VERSION ""

NS_ :

BS_:

BU_: CH DIPF DIPR ETH FC HVI HVS PARTY SDCV VEH VIRT

BO_ 1297 RCM_alertLog: 8 CH
 SG_ RCM_a001_eventIDFsignal m1 : 25|1@1+ (1,0) [0|1] ""  gtw
 SG_ RCM_a100_eventIDFsignal m100 : 25|1@1+ (1,0) [0|1] ""  gtw
 SG_ RCM_a023_eventIDFsignal m23 : 25|1@1+ (1,0) [0|1] ""  gtw
 SG_ RCM_a090_eventIDFsignal m90 : 25|1@1+ (1,0) [0|1] ""  gtw
 SG_ RCM_a089_eventIDFsignal m89 : 25|1@1+ (1,0) [0|1] ""  gtw
 SG_ RCM_a068_eventIDFsignal m68 : 25|1@1+ (1,0) [0|1] ""  gtw
 SG_ RCM_a071_eventIDFsignal m71 : 25|1@1+ (1,0) [0|1] ""  gtw
 SG_ RCM_a086_eventIDFsignal m86 : 25|1@1+ (1,0) [0|1] ""  gtw
 SG_ RCM_a053_eventIDFsignal m53 : 25|1@1+ (1,0) [0|1] ""  gtw
 SG_ RCM_a116_eventIDFsignal m116 : 25|1@1+ (1,0) [0|1] ""  gtw
 SG_ RCM_a017_eventIDFsignal m17 : 25|1@1+ (1,0) [0|1] ""  gtw
 SG_ RCM_a035_eventIDFsignal m35 : 25|1@1+ (1,0) [0|1] ""  gtw
 SG_ RCM_a056_eventIDFsignal m56 : 25|1@1+ (1,0) [0|1] ""  gtw
 SG_ RCM_a113_eventIDFsignal m113 : 25|1@1+ (1,0) [0|1] ""  gtw
 SG_ RCM_a012_eventIDFsignal m12 : 25|1@1+ (1,0) [0|1] ""  gtw
 SG_ RCM_a074_eventIDFsignal m74 : 25|1@1+ (1,0) [0|1] ""  gtw
 SG_ RCM_a029_eventIDFsignal m29 : 25|1@1+ (1,0) [0|1] ""  gtw
 SG_ RCM_a083_eventIDFsignal m83 : 25|1@1+ (1,0) [0|1] ""  gtw
 SG_ RCM_a030_eventIDFsignal m30 : 25|1@1+ (1,0) [0|1] ""  gtw
 SG_ RCM_a033_eventIDFsignal m33 : 25|1@1+ (1,0) [0|1] ""  gtw
 SG_ RCM_a011_eventIDFsignal m11 : 25|1@1+ (1,0) [0|1] ""  gtw
 SG_ RCM_a077_eventIDFsignal m77 : 25|1@1+ (1,0) [0|1] ""  gtw
 SG_ RCM_a008_eventIDFsignal m8 : 25|1@1+ (1,0) [0|1] ""  gtw
 SG_ RCM_a109_eventIDFsignal m109 : 25|1@1+ (1,0) [0|1] ""  gtw
 SG_ RCM_a099_eventIDFsignal m99 : 25|1@1+ (1,0) [0|1] ""  gtw
 SG_ RCM_a055_eventIDFsignal m55 : 25|1@1+ (1,0) [0|1] ""  gtw
 SG_ RCM_a110_eventIDFsignal m110 : 25|1@1+ (1,0) [0|1] ""  gtw
 SG_ RCM_a080_eventIDFsignal m80 : 25|1@1+ (1,0) [0|1] ""  gtw
 SG_ RCM_a094_eventIDFsignal m94 : 25|1@1+ (1,0) [0|1] ""  gtw
 SG_ RCM_a005_eventIDFsignal m5 : 25|1@1+ (1,0) [0|1] ""  gtw
 SG_ RCM_a027_eventIDFsignal m27 : 25|1@1+ (1,0) [0|1] ""  gtw
 SG_ RCM_a104_eventIDFsignal m104 : 25|1@1+ (1,0) [0|1] ""  gtw
 SG_ RCM_a058_eventIDFsignal m58 : 25|1@1+ (1,0) [0|1] ""  gtw
 SG_ RCM_a041_eventIDFsignal m41 : 25|1@1+ (1,0) [0|1] ""  gtw
 SG_ RCM_a063_eventIDFsignal m63 : 25|1@1+ (1,0) [0|1] ""  gtw
 SG_ RCM_a093_eventIDFsignal m93 : 25|1@1+ (1,0) [0|1] ""  gtw
 SG_ RCM_a020_eventIDFsignal m20 : 25|1@1+ (1,0) [0|1] ""  gtw
 SG_ RCM_a103_eventIDFsignal m103 : 25|1@1+ (1,0) [0|1] ""  gtw
 SG_ RCM_a002_eventIDFsignal m2 : 25|1@1+ (1,0) [0|1] ""  gtw
 SG_ RCM_a039_eventIDFsignal m39 : 25|1@1+ (1,0) [0|1] ""  gtw
 SG_ RCM_a064_eventIDFsignal m64 : 25|1@1+ (1,0) [0|1] ""  gtw
 SG_ RCM_a046_eventIDFsignal m46 : 25|1@1+ (1,0) [0|1] ""  gtw
 SG_ RCM_a070_eventIDFsignal m70 : 25|1@1+ (1,0) [0|1] ""  gtw
 SG_ RCM_a034_eventIDFsignal m34 : 25|1@1+ (1,0) [0|1] ""  gtw
 SG_ RCM_a052_eventIDFsignal m52 : 25|1@1+ (1,0) [0|1] ""  gtw
 SG_ RCM_a117_eventIDFsignal m117 : 25|1@1+ (1,0) [0|1] ""  gtw
 SG_ RCM_a087_eventIDFsignal m87 : 25|1@1+ (1,0) [0|1] ""  gtw
 SG_ RCM_a069_eventIDFsignal m69 : 25|1@1+ (1,0) [0|1] ""  gtw
 SG_ RCM_a016_eventIDFsignal m16 : 25|1@1+ (1,0) [0|1] ""  gtw
 SG_ RCM_a051_eventIDFsignal m51 : 25|1@1+ (1,0) [0|1] ""  gtw
 SG_ RCM_a114_eventIDFsignal m114 : 25|1@1+ (1,0) [0|1] ""  gtw
 SG_ RCM_a015_eventIDFsignal m15 : 25|1@1+ (1,0) [0|1] ""  gtw
 SG_ RCM_a073_eventIDFsignal m73 : 25|1@1+ (1,0) [0|1] ""  gtw
 SG_ RCM_a037_eventIDFsignal m37 : 25|1@1+ (1,0) [0|1] ""  gtw
 SG_ RCM_a084_eventIDFsignal m84 : 25|1@1+ (1,0) [0|1] ""  gtw
 SG_ RCM_a048_eventIDFsignal m48 : 25|1@1+ (1,0) [0|1] ""  gtw
 SG_ RCM_a098_eventIDFsignal m98 : 25|1@1+ (1,0) [0|1] ""  gtw
 SG_ RCM_a081_eventIDFsignal m81 : 25|1@1+ (1,0) [0|1] ""  gtw
 SG_ RCM_a108_eventIDFsignal m108 : 25|1@1+ (1,0) [0|1] ""  gtw
 SG_ RCM_a054_eventIDFsignal m54 : 25|1@1+ (1,0) [0|1] ""  gtw
 SG_ RCM_a111_eventIDFsignal m111 : 25|1@1+ (1,0) [0|1] ""  gtw
 SG_ RCM_a032_eventIDFsignal m32 : 25|1@1+ (1,0) [0|1] ""  gtw
 SG_ RCM_a009_eventIDFsignal m9 : 25|1@1+ (1,0) [0|1] ""  gtw
 SG_ RCM_a076_eventIDFsignal m76 : 25|1@1+ (1,0) [0|1] ""  gtw
 SG_ RCM_a010_eventIDFsignal m10 : 25|1@1+ (1,0) [0|1] ""  gtw
 SG_ RCM_a042_eventIDFsignal m42 : 25|1@1+ (1,0) [0|1] ""  gtw
 SG_ RCM_a079_eventIDFsignal m79 : 25|1@1+ (1,0) [0|1] ""  gtw
 SG_ RCM_a006_eventIDFsignal m6 : 25|1@1+ (1,0) [0|1] ""  gtw
 SG_ RCM_a097_eventIDFsignal m97 : 25|1@1+ (1,0) [0|1] ""  gtw
 SG_ RCM_a060_eventIDFsignal m60 : 25|1@1+ (1,0) [0|1] ""  gtw
 SG_ RCM_a107_eventIDFsignal m107 : 25|1@1+ (1,0) [0|1] ""  gtw
 SG_ RCM_a024_eventIDFsignal m24 : 25|1@1+ (1,0) [0|1] ""  gtw
 SG_ RCM_a047_eventIDFsignal m47 : 25|1@1+ (1,0) [0|1] ""  gtw
 SG_ RCM_a092_eventIDFsignal m92 : 25|1@1+ (1,0) [0|1] ""  gtw
 SG_ RCM_a065_eventIDFsignal m65 : 25|1@1+ (1,0) [0|1] ""  gtw
 SG_ RCM_a021_eventIDFsignal m21 : 25|1@1+ (1,0) [0|1] ""  gtw
 SG_ RCM_a102_eventIDFsignal m102 : 25|1@1+ (1,0) [0|1] ""  gtw
 SG_ RCM_a003_eventIDFsignal m3 : 25|1@1+ (1,0) [0|1] ""  gtw
 SG_ RCM_a038_eventIDFsignal m38 : 25|1@1+ (1,0) [0|1] ""  gtw
 SG_ RCM_a022_eventIDFsignal m22 : 25|1@1+ (1,0) [0|1] ""  gtw
 SG_ RCM_a101_eventIDFsignal m101 : 25|1@1+ (1,0) [0|1] ""  gtw
 SG_ RCM_a118_eventIDFsignal m118 : 25|1@1+ (1,0) [0|1] ""  gtw
 SG_ RCM_a044_eventIDFsignal m44 : 25|1@1+ (1,0) [0|1] ""  gtw
 SG_ RCM_a066_eventIDFsignal m66 : 25|1@1+ (1,0) [0|1] ""  gtw
 SG_ RCM_a000_eventIDFsignal m0 : 25|1@1+ (1,0) [0|1] ""  gtw
 SG_ RCM_a091_eventIDFsignal m91 : 25|1@1+ (1,0) [0|1] ""  gtw
 SG_ RCM_a088_eventIDFsignal m88 : 25|1@1+ (1,0) [0|1] ""  gtw
 SG_ RCM_a019_eventIDFsignal m19 : 25|1@1+ (1,0) [0|1] ""  gtw
 SG_ RCM_a054_presPedProRCrossCoup m54 : 24|1@1+ (1,0) [0|1] ""  gtw
 SG_ RCM_a051_presFrntLDoorCrossCoup m51 : 24|1@1+ (1,0) [0|1] ""  gtw
 SG_ RCM_a052_presFrntRDoorCrossCoup m52 : 24|1@1+ (1,0) [0|1] ""  gtw
 SG_ RCM_a053_presPedProLCrossCoup m53 : 24|1@1+ (1,0) [0|1] ""  gtw
 SG_ RCM_a000_crashDetectedHVpyro m0 : 24|1@1+ (1,0) [0|1] ""  gtw
 SG_ RCM_a045_upFrontSensorRDefect m45 : 23|1@1+ (1,0) [0|1] ""  gtw
 SG_ RCM_a052_presFrntRDoorSht2Bat m52 : 23|1@1+ (1,0) [0|1] ""  gtw
 SG_ RCM_a051_presFrntLDoorSht2Bat m51 : 23|1@1+ (1,0) [0|1] ""  gtw
 SG_ RCM_a047_sideAccelBPilRDefect m47 : 23|1@1+ (1,0) [0|1] ""  gtw
 SG_ RCM_a046_sideAccelBPilLDefect m46 : 23|1@1+ (1,0) [0|1] ""  gtw
 SG_ RCM_a050_upFrontSensorCDefect m50 : 23|1@1+ (1,0) [0|1] ""  gtw
 SG_ RCM_a000_crashDetectedStage2 m0 : 23|1@1+ (1,0) [0|1] ""  gtw
 SG_ RCM_a044_upFrontSensorLDefect m44 : 23|1@1+ (1,0) [0|1] ""  gtw
 SG_ RCM_a053_presPedProLSht2Bat m53 : 23|1@1+ (1,0) [0|1] ""  gtw
 SG_ RCM_a048_sideAccelCPilLDefect m48 : 23|1@1+ (1,0) [0|1] ""  gtw
 SG_ RCM_a049_sideAccelCPilRDefect m49 : 23|1@1+ (1,0) [0|1] ""  gtw
 SG_ RCM_a004_algoPASIDMismatch m4 : 23|1@1+ (1,0) [0|1] ""  gtw
 SG_ RCM_a054_presPedProRSht2Bat m54 : 23|1@1+ (1,0) [0|1] ""  gtw
 SG_ RCM_a048_sideAccelCPilLplaus m48 : 22|1@1+ (1,0) [0|1] ""  gtw
 SG_ RCM_a044_upFrontSensorLplaus m44 : 22|1@1+ (1,0) [0|1] ""  gtw
 SG_ RCM_a004_paramLayoutIDInv m4 : 22|1@1+ (1,0) [0|1] ""  gtw
 SG_ RCM_a050_upFrontSensorCplaus m50 : 22|1@1+ (1,0) [0|1] ""  gtw
 SG_ RCM_a053_presPedProLSht2Gnd m53 : 22|1@1+ (1,0) [0|1] ""  gtw
 SG_ RCM_a046_sideAccelBPilLplaus m46 : 22|1@1+ (1,0) [0|1] ""  gtw
 SG_ RCM_a052_presFrntRDoorSht2Gnd m52 : 22|1@1+ (1,0) [0|1] ""  gtw
 SG_ RCM_a051_presFrntLDoorSht2Gnd m51 : 22|1@1+ (1,0) [0|1] ""  gtw
 SG_ RCM_a054_presPedProRSht2Gnd m54 : 22|1@1+ (1,0) [0|1] ""  gtw
 SG_ RCM_a047_sideAccelBPilRplaus m47 : 22|1@1+ (1,0) [0|1] ""  gtw
 SG_ RCM_a000_crashDetectedStage1 m0 : 22|1@1+ (1,0) [0|1] ""  gtw
 SG_ RCM_a045_upFrontSensorRplaus m45 : 22|1@1+ (1,0) [0|1] ""  gtw
 SG_ RCM_a049_sideAccelCPilRplaus m49 : 22|1@1+ (1,0) [0|1] ""  gtw
 SG_ RCM_a017_passABStg2Config m17 : 21|1@1+ (1,0) [0|1] ""  gtw
 SG_ RCM_a052_presFrntRDoorDefect m52 : 21|1@1+ (1,0) [0|1] ""  gtw
 SG_ RCM_a103_imuPtchR8OffCompNegSLDC m103 : 21|1@1+ (1,0) [0|1] ""  gtw
 SG_ RCM_a035_preten2ndRowRCgf m35 : 21|1@1+ (1,0) [0|1] ""  gtw
 SG_ RCM_a041_hoodActuatorLConfig m41 : 21|1@1+ (1,0) [0|1] ""  gtw
 SG_ RCM_a105_imuLongAOffCompNegSLDC m105 : 21|1@1+ (1,0) [0|1] ""  gtw
 SG_ RCM_a031_frntCentrABConfig m31 : 21|1@1+ (1,0) [0|1] ""  gtw
 SG_ RCM_a040_hoodActuatorRConfig m40 : 21|1@1+ (1,0) [0|1] ""  gtw
 SG_ RCM_a014_driverABStg1Config m14 : 21|1@1+ (1,0) [0|1] ""  gtw
 SG_ RCM_a028_sideAB1stRowRConfig m28 : 21|1@1+ (1,0) [0|1] ""  gtw
 SG_ RCM_a016_passABStg1Config m16 : 21|1@1+ (1,0) [0|1] ""  gtw
 SG_ RCM_a054_presPedProRDefect m54 : 21|1@1+ (1,0) [0|1] ""  gtw
 SG_ RCM_a048_sideAccelCPilLOption m48 : 21|1@1+ (1,0) [0|1] ""  gtw
 SG_ RCM_a000_crashDetectedPreten m0 : 21|1@1+ (1,0) [0|1] ""  gtw
 SG_ RCM_a033_curABRightConfig m33 : 21|1@1+ (1,0) [0|1] ""  gtw
 SG_ RCM_a106_imuLatAcOffCompNegSLDC m106 : 21|1@1+ (1,0) [0|1] ""  gtw
 SG_ RCM_a027_sideAB1stRowLConfig m27 : 21|1@1+ (1,0) [0|1] ""  gtw
 SG_ RCM_a094_bucklSwVCRearCnterFault m94 : 21|1@1+ (1,0) [0|1] ""  gtw
 SG_ RCM_a063_sbsw2ndRowRConfig m63 : 21|1@1+ (1,0) [0|1] ""  gtw
 SG_ RCM_a019_pretenShldLeftConfig m19 : 21|1@1+ (1,0) [0|1] ""  gtw
 SG_ RCM_a038_unused6 m38 : 21|1@1+ (1,0) [0|1] ""  gtw
 SG_ RCM_a104_imuRollR8OffCompNegSLDC m104 : 21|1@1+ (1,0) [0|1] ""  gtw
 SG_ RCM_a026_kneeABPassConfig m26 : 21|1@1+ (1,0) [0|1] ""  gtw
 SG_ RCM_a062_alrConfig m62 : 21|1@1+ (1,0) [0|1] ""  gtw
 SG_ RCM_a049_sideAccelCPilROption m49 : 21|1@1+ (1,0) [0|1] ""  gtw
 SG_ RCM_a051_presFrntLDoorDefect m51 : 21|1@1+ (1,0) [0|1] ""  gtw
 SG_ RCM_a025_kneeABDrvrConfig m25 : 21|1@1+ (1,0) [0|1] ""  gtw
 SG_ RCM_a030_farsideABConfig m30 : 21|1@1+ (1,0) [0|1] ""  gtw
 SG_ RCM_a029_driverABAVConfig m29 : 21|1@1+ (1,0) [0|1] ""  gtw
 SG_ RCM_a061_seaTrkPosRightConfig m61 : 21|1@1+ (1,0) [0|1] ""  gtw
 SG_ RCM_a034_preten2ndRowLCgf m34 : 21|1@1+ (1,0) [0|1] ""  gtw
 SG_ RCM_a020_pretenShldRightConfig m20 : 21|1@1+ (1,0) [0|1] ""  gtw
 SG_ RCM_a036_curAB2ndRowLConfig m36 : 21|1@1+ (1,0) [0|1] ""  gtw
 SG_ RCM_a023_loadLimLeftConfig m23 : 21|1@1+ (1,0) [0|1] ""  gtw
 SG_ RCM_a058_bucklHallLeftConfig m58 : 21|1@1+ (1,0) [0|1] ""  gtw
 SG_ RCM_a047_sideAccelBPilROption m47 : 21|1@1+ (1,0) [0|1] ""  gtw
 SG_ RCM_a004_swVersionMismatch m4 : 21|1@1+ (1,0) [0|1] ""  gtw
 SG_ RCM_a001_nearDeployPretensioner m1 : 21|1@1+ (1,0) [0|1] ""  gtw
 SG_ RCM_a102_imuYawR8OffCompNegSLDC m102 : 21|1@1+ (1,0) [0|1] ""  gtw
 SG_ RCM_a039_unused12 m39 : 21|1@1+ (1,0) [0|1] ""  gtw
 SG_ RCM_a044_upFrontSensorLOption m44 : 21|1@1+ (1,0) [0|1] ""  gtw
 SG_ RCM_a053_presPedProLDefect m53 : 21|1@1+ (1,0) [0|1] ""  gtw
 SG_ RCM_a032_curABLeftConfig m32 : 21|1@1+ (1,0) [0|1] ""  gtw
 SG_ RCM_a022_pretenLapRightConfig m22 : 21|1@1+ (1,0) [0|1] ""  gtw
 SG_ RCM_a021_pretenLapLeftConfig m21 : 21|1@1+ (1,0) [0|1] ""  gtw
 SG_ RCM_a050_upFrontSensorCOption m50 : 21|1@1+ (1,0) [0|1] ""  gtw
 SG_ RCM_a018_passActiveVentConfig m18 : 21|1@1+ (1,0) [0|1] ""  gtw
 SG_ RCM_a024_loadLimRightConfig m24 : 21|1@1+ (1,0) [0|1] ""  gtw
 SG_ RCM_a045_upFrontSensorROption m45 : 21|1@1+ (1,0) [0|1] ""  gtw
 SG_ RCM_a037_curAB2ndRowRConfig m37 : 21|1@1+ (1,0) [0|1] ""  gtw
 SG_ RCM_a060_seaTrkPosLeftConfig m60 : 21|1@1+ (1,0) [0|1] ""  gtw
 SG_ RCM_a015_driverABStg2Config m15 : 21|1@1+ (1,0) [0|1] ""  gtw
 SG_ RCM_a107_imuVertAOffCompNegSLDC m107 : 21|1@1+ (1,0) [0|1] ""  gtw
 SG_ RCM_a046_sideAccelBPilLOption m46 : 21|1@1+ (1,0) [0|1] ""  gtw
 SG_ RCM_a059_bucklSwRightConfig m59 : 21|1@1+ (1,0) [0|1] ""  gtw
 SG_ RCM_a105_imuLongAOffCompPosSLDC m105 : 20|1@1+ (1,0) [0|1] ""  gtw
 SG_ RCM_a054_presPedProRAbsPre m54 : 20|1@1+ (1,0) [0|1] ""  gtw
 SG_ RCM_a060_seaTrkPosLeftCrossCoup m60 : 20|1@1+ (1,0) [0|1] ""  gtw
 SG_ RCM_a037_curAB2ndRowRCrossCoup m37 : 20|1@1+ (1,0) [0|1] ""  gtw
 SG_ RCM_a015_driverABStg2CrossCoup m15 : 20|1@1+ (1,0) [0|1] ""  gtw
 SG_ RCM_a103_imuPtchR8OffCompPosSLDC m103 : 20|1@1+ (1,0) [0|1] ""  gtw
 SG_ RCM_a036_curAB2ndRowLCrossCoup m36 : 20|1@1+ (1,0) [0|1] ""  gtw
 SG_ RCM_a058_bucklHallLeftCrossCoup m58 : 20|1@1+ (1,0) [0|1] ""  gtw
 SG_ RCM_a023_loadLimLeftCrossCoup m23 : 20|1@1+ (1,0) [0|1] ""  gtw
 SG_ RCM_a040_hoodActuatorRCrossCoup m40 : 20|1@1+ (1,0) [0|1] ""  gtw
 SG_ RCM_a031_frntCentrABCrossCoup m31 : 20|1@1+ (1,0) [0|1] ""  gtw
 SG_ RCM_a052_presFrntRDoorAbsPre m52 : 20|1@1+ (1,0) [0|1] ""  gtw
 SG_ RCM_a014_driverABStg1CrossCoup m14 : 20|1@1+ (1,0) [0|1] ""  gtw
 SG_ RCM_a039_unused11 m39 : 20|1@1+ (1,0) [0|1] ""  gtw
 SG_ RCM_a046_sideAccelBPilLInitTyp m46 : 20|1@1+ (1,0) [0|1] ""  gtw
 SG_ RCM_a093_bucklSwVCRearLeftFault m93 : 20|1@1+ (1,0) [0|1] ""  gtw
 SG_ RCM_a094_bucklSwVCRearRghtFault m94 : 20|1@1+ (1,0) [0|1] ""  gtw
 SG_ RCM_a106_imuLatAcOffCompPosSLDC m106 : 20|1@1+ (1,0) [0|1] ""  gtw
 SG_ RCM_a063_sbsw2ndRowRCrossCoup m63 : 20|1@1+ (1,0) [0|1] ""  gtw
 SG_ RCM_a022_pretenLapRightCrossCoup m22 : 20|1@1+ (1,0) [0|1] ""  gtw
 SG_ RCM_a021_pretenLapLeftCrossCoup m21 : 20|1@1+ (1,0) [0|1] ""  gtw
 SG_ RCM_a032_curABLeftCrossCoup m32 : 20|1@1+ (1,0) [0|1] ""  gtw
 SG_ RCM_a048_sideAccelCPilLInitTyp m48 : 20|1@1+ (1,0) [0|1] ""  gtw
 SG_ RCM_a018_passActiveVentCrossCoup m18 : 20|1@1+ (1,0) [0|1] ""  gtw
 SG_ RCM_a044_upFrontSensorLInitTyp m44 : 20|1@1+ (1,0) [0|1] ""  gtw
 SG_ RCM_a017_passABStg2CrossCoup m17 : 20|1@1+ (1,0) [0|1] ""  gtw
 SG_ RCM_a104_imuRollR8OffCompPosSLDC m104 : 20|1@1+ (1,0) [0|1] ""  gtw
 SG_ RCM_a041_hoodActuatorLCrossCoup m41 : 20|1@1+ (1,0) [0|1] ""  gtw
 SG_ RCM_a062_alrCrossCoup m62 : 20|1@1+ (1,0) [0|1] ""  gtw
 SG_ RCM_a026_kneeABPassCrossCoup m26 : 20|1@1+ (1,0) [0|1] ""  gtw
 SG_ RCM_a020_pretenShldRightCrossC m20 : 20|1@1+ (1,0) [0|1] ""  gtw
 SG_ RCM_a112_imuYawR8ChnlMonitPerm m112 : 20|1@1+ (1,0) [0|1] ""  gtw
 SG_ RCM_a025_kneeABDrvrCrossCoup m25 : 20|1@1+ (1,0) [0|1] ""  gtw
 SG_ RCM_a051_presFrntLDoorAbsPre m51 : 20|1@1+ (1,0) [0|1] ""  gtw
 SG_ RCM_a028_sideAB1stRowRCrossCoup m28 : 20|1@1+ (1,0) [0|1] ""  gtw
 SG_ RCM_a050_upFrontSensorCInitTyp m50 : 20|1@1+ (1,0) [0|1] ""  gtw
 SG_ RCM_a016_passABStg1CrossCoup m16 : 20|1@1+ (1,0) [0|1] ""  gtw
 SG_ RCM_a034_preten2ndRowLCrossCoup m34 : 20|1@1+ (1,0) [0|1] ""  gtw
 SG_ RCM_a061_seaTrkPosRightCrossCoup m61 : 20|1@1+ (1,0) [0|1] ""  gtw
 SG_ RCM_a029_driverABAVCrossCoup m29 : 20|1@1+ (1,0) [0|1] ""  gtw
 SG_ RCM_a045_upFrontSensorRInitTyp m45 : 20|1@1+ (1,0) [0|1] ""  gtw
 SG_ RCM_a049_sideAccelCPilRInitTyp m49 : 20|1@1+ (1,0) [0|1] ""  gtw
 SG_ RCM_a102_imuYawR8OffCompPosSLDC m102 : 20|1@1+ (1,0) [0|1] ""  gtw
 SG_ RCM_a019_pretenShldLeftCrossC m19 : 20|1@1+ (1,0) [0|1] ""  gtw
 SG_ RCM_a053_presPedProLAbsPre m53 : 20|1@1+ (1,0) [0|1] ""  gtw
 SG_ RCM_a000_crashDetectedRoll m0 : 20|1@1+ (1,0) [0|1] ""  gtw
 SG_ RCM_a033_curABRightCrossCoup m33 : 20|1@1+ (1,0) [0|1] ""  gtw
 SG_ RCM_a004_internalFaultDetected m4 : 20|1@1+ (1,0) [0|1] ""  gtw
 SG_ RCM_a001_nearDeployRoll m1 : 20|1@1+ (1,0) [0|1] ""  gtw
 SG_ RCM_a024_loadLimRightCrossCoup m24 : 20|1@1+ (1,0) [0|1] ""  gtw
 SG_ RCM_a047_sideAccelBPilRInitTyp m47 : 20|1@1+ (1,0) [0|1] ""  gtw
 SG_ RCM_a038_unused5 m38 : 20|1@1+ (1,0) [0|1] ""  gtw
 SG_ RCM_a027_sideAB1stRowLCrossCoup m27 : 20|1@1+ (1,0) [0|1] ""  gtw
 SG_ RCM_a035_preten2ndRowRCrossCoup m35 : 20|1@1+ (1,0) [0|1] ""  gtw
 SG_ RCM_a030_farsideABCrossCoup m30 : 20|1@1+ (1,0) [0|1] ""  gtw
 SG_ RCM_a107_imuVertAOffCompPosSLDC m107 : 20|1@1+ (1,0) [0|1] ""  gtw
 SG_ RCM_a059_bucklHallRightCrossCoup m59 : 20|1@1+ (1,0) [0|1] ""  gtw
 SG_ RCM_a017_passABStg2Short m17 : 19|1@1+ (1,0) [0|1] ""  gtw
 SG_ RCM_a065_swDrvrOrientConfig m65 : 19|1@1+ (1,0) [0|1] ""  gtw
 SG_ RCM_a104_imuRollR8OffCompNegFLDC m104 : 19|1@1+ (1,0) [0|1] ""  gtw
 SG_ RCM_a041_hoodActuatorLShort m41 : 19|1@1+ (1,0) [0|1] ""  gtw
 SG_ RCM_a113_imuPitchR8ChnlMonitPerm m113 : 19|1@1+ (1,0) [0|1] ""  gtw
 SG_ RCM_a020_pretenShldRightShort m20 : 19|1@1+ (1,0) [0|1] ""  gtw
 SG_ RCM_a061_seaTrkPosRightUndefined m61 : 19|1@1+ (1,0) [0|1] ""  gtw
 SG_ RCM_a029_driverABAVShort m29 : 19|1@1+ (1,0) [0|1] ""  gtw
 SG_ RCM_a034_preten2ndRowLShort m34 : 19|1@1+ (1,0) [0|1] ""  gtw
 SG_ RCM_a038_unused4 m38 : 19|1@1+ (1,0) [0|1] ""  gtw
 SG_ RCM_a046_sideAccelBPilLComm m46 : 19|1@1+ (1,0) [0|1] ""  gtw
 SG_ RCM_a016_passABStg1Short m16 : 19|1@1+ (1,0) [0|1] ""  gtw
 SG_ RCM_a028_sideAB1stRowRShort m28 : 19|1@1+ (1,0) [0|1] ""  gtw
 SG_ RCM_a045_upFrontSensorRComm m45 : 19|1@1+ (1,0) [0|1] ""  gtw
 SG_ RCM_a000_crashDetectedRight m0 : 19|1@1+ (1,0) [0|1] ""  gtw
 SG_ RCM_a064_hwcp1Config m64 : 19|1@1+ (1,0) [0|1] ""  gtw
 SG_ RCM_a050_upFrontSensorCComm m50 : 19|1@1+ (1,0) [0|1] ""  gtw
 SG_ RCM_a093_bucklSwVCFrontLeftFault m93 : 19|1@1+ (1,0) [0|1] ""  gtw
 SG_ RCM_a021_pretenLapLeftShort m21 : 19|1@1+ (1,0) [0|1] ""  gtw
 SG_ RCM_a112_imuYawR8ChnlMonitTmp m112 : 19|1@1+ (1,0) [0|1] ""  gtw
 SG_ RCM_a022_pretenLapRightShort m22 : 19|1@1+ (1,0) [0|1] ""  gtw
 SG_ RCM_a039_unused10 m39 : 19|1@1+ (1,0) [0|1] ""  gtw
 SG_ RCM_a051_presFrntLDoorPlaus m51 : 19|1@1+ (1,0) [0|1] ""  gtw
 SG_ RCM_a032_curABLeftShort m32 : 19|1@1+ (1,0) [0|1] ""  gtw
 SG_ RCM_a018_passActiveVentShort m18 : 19|1@1+ (1,0) [0|1] ""  gtw
 SG_ RCM_a019_pretenShldLeftShort m19 : 19|1@1+ (1,0) [0|1] ""  gtw
 SG_ RCM_a063_sbsw2ndRowRUndefined m63 : 19|1@1+ (1,0) [0|1] ""  gtw
 SG_ RCM_a044_upFrontSensorLComm m44 : 19|1@1+ (1,0) [0|1] ""  gtw
 SG_ RCM_a106_imuLatAcOffCompNegFLDC m106 : 19|1@1+ (1,0) [0|1] ""  gtw
 SG_ RCM_a015_driverABStg2Short m15 : 19|1@1+ (1,0) [0|1] ""  gtw
 SG_ RCM_a066_sbsw2ndRowLConfig m66 : 19|1@1+ (1,0) [0|1] ""  gtw
 SG_ RCM_a060_seaTrkPosLeftUndefined m60 : 19|1@1+ (1,0) [0|1] ""  gtw
 SG_ RCM_a047_sideAccelBPilRComm m47 : 19|1@1+ (1,0) [0|1] ""  gtw
 SG_ RCM_a037_curAB2ndRowRShort m37 : 19|1@1+ (1,0) [0|1] ""  gtw
 SG_ RCM_a105_imuLongAOffCompNegFLDC m105 : 19|1@1+ (1,0) [0|1] ""  gtw
 SG_ RCM_a103_imuPtchR8OffCompNegFLDC m103 : 19|1@1+ (1,0) [0|1] ""  gtw
 SG_ RCM_a035_preten2ndRowRShort m35 : 19|1@1+ (1,0) [0|1] ""  gtw
 SG_ RCM_a030_farsideABShort m30 : 19|1@1+ (1,0) [0|1] ""  gtw
 SG_ RCM_a107_imuVertAOffCompNegFLDC m107 : 19|1@1+ (1,0) [0|1] ""  gtw
 SG_ RCM_a004_idleMode m4 : 19|1@1+ (1,0) [0|1] ""  gtw
 SG_ RCM_a040_hoodActuatorRShort m40 : 19|1@1+ (1,0) [0|1] ""  gtw
 SG_ RCM_a091_comEPAS3PsysStatusCntr m91 : 19|1@1+ (1,0) [0|1] ""  gtw
 SG_ RCM_a014_driverABStg1Short m14 : 19|1@1+ (1,0) [0|1] ""  gtw
 SG_ RCM_a031_frntCentrABShort m31 : 19|1@1+ (1,0) [0|1] ""  gtw
 SG_ RCM_a023_loadLimLeftShort m23 : 19|1@1+ (1,0) [0|1] ""  gtw
 SG_ RCM_a049_sideAccelCPilRComm m49 : 19|1@1+ (1,0) [0|1] ""  gtw
 SG_ RCM_a036_curAB2ndRowLShort m36 : 19|1@1+ (1,0) [0|1] ""  gtw
 SG_ RCM_a094_bucklSwVCFrontRghtFault m94 : 19|1@1+ (1,0) [0|1] ""  gtw
 SG_ RCM_a033_curABRightShort m33 : 19|1@1+ (1,0) [0|1] ""  gtw
 SG_ RCM_a114_imuRollR8ChnlMonitPerm m114 : 19|1@1+ (1,0) [0|1] ""  gtw
 SG_ RCM_a102_imuYawR8OffCompNegFLDC m102 : 19|1@1+ (1,0) [0|1] ""  gtw
 SG_ RCM_a054_presPedProRPlaus m54 : 19|1@1+ (1,0) [0|1] ""  gtw
 SG_ RCM_a058_bucklHallLeftUndef m58 : 19|1@1+ (1,0) [0|1] ""  gtw
 SG_ RCM_a027_sideAB1stRowLShort m27 : 19|1@1+ (1,0) [0|1] ""  gtw
 SG_ RCM_a052_presFrntRDoorPlaus m52 : 19|1@1+ (1,0) [0|1] ""  gtw
 SG_ RCM_a001_nearDeployRight m1 : 19|1@1+ (1,0) [0|1] ""  gtw
 SG_ RCM_a024_loadLimRightShort m24 : 19|1@1+ (1,0) [0|1] ""  gtw
 SG_ RCM_a059_bucklHallRightUndef m59 : 19|1@1+ (1,0) [0|1] ""  gtw
 SG_ RCM_a053_presPedProLPlaus m53 : 19|1@1+ (1,0) [0|1] ""  gtw
 SG_ RCM_a026_kneeABPassShort m26 : 19|1@1+ (1,0) [0|1] ""  gtw
 SG_ RCM_a048_sideAccelCPilLComm m48 : 19|1@1+ (1,0) [0|1] ""  gtw
 SG_ RCM_a025_kneeABDrvrShort m25 : 19|1@1+ (1,0) [0|1] ""  gtw
 SG_ RCM_a062_alrUndefined m62 : 19|1@1+ (1,0) [0|1] ""  gtw
 SG_ RCM_a089_comChassisCANPH3Cntr m89 : 18|1@1+ (1,0) [0|1] ""  gtw
 SG_ RCM_a096_comESPwheelSpeedsCntr m96 : 18|1@1+ (1,0) [0|1] ""  gtw
 SG_ RCM_a024_loadLimRightOpen m24 : 18|1@1+ (1,0) [0|1] ""  gtw
 SG_ RCM_a104_imuRollR8OffCompPosFLDC m104 : 18|1@1+ (1,0) [0|1] ""  gtw
 SG_ RCM_a076_comEPBLStatusCntr m76 : 18|1@1+ (1,0) [0|1] ""  gtw
 SG_ RCM_a095_comESPstatusCntr m95 : 18|1@1+ (1,0) [0|1] ""  gtw
 SG_ RCM_a033_curABRightOpen m33 : 18|1@1+ (1,0) [0|1] ""  gtw
 SG_ RCM_a072_comUnusedCntr m72 : 18|1@1+ (1,0) [0|1] ""  gtw
 SG_ RCM_a077_comEPBRStatusCntr m77 : 18|1@1+ (1,0) [0|1] ""  gtw
 SG_ RCM_a091_comEPAS3PsysStatusChkSm m91 : 18|1@1+ (1,0) [0|1] ""  gtw
 SG_ RCM_a069_comChassisCANPH7Cntr m69 : 18|1@1+ (1,0) [0|1] ""  gtw
 SG_ RCM_a079_comOCS1DCntr m79 : 18|1@1+ (1,0) [0|1] ""  gtw
 SG_ RCM_a097_comDIspeedCntr m97 : 18|1@1+ (1,0) [0|1] ""  gtw
 SG_ RCM_a042_ens1Config m42 : 18|1@1+ (1,0) [0|1] ""  gtw
 SG_ RCM_a031_frntCentrABOpen m31 : 18|1@1+ (1,0) [0|1] ""  gtw
 SG_ RCM_a040_hoodActuatorROpen m40 : 18|1@1+ (1,0) [0|1] ""  gtw
 SG_ RCM_a014_driverABStg1Open m14 : 18|1@1+ (1,0) [0|1] ""  gtw
 SG_ RCM_a046_sideAccelBPilLCLosCoup m46 : 18|1@1+ (1,0) [0|1] ""  gtw
 SG_ RCM_a036_curAB2ndRowLOpen m36 : 18|1@1+ (1,0) [0|1] ""  gtw
 SG_ RCM_a074_comChassisCANPH5Cntr m74 : 18|1@1+ (1,0) [0|1] ""  gtw
 SG_ RCM_a081_comVCFRONTLVPrwCntr m81 : 18|1@1+ (1,0) [0|1] ""  gtw
 SG_ RCM_a058_bucklHallLeftOpen m58 : 18|1@1+ (1,0) [0|1] ""  gtw
 SG_ RCM_a023_loadLimLeftOpen m23 : 18|1@1+ (1,0) [0|1] ""  gtw
 SG_ RCM_a043_ens2Config m43 : 18|1@1+ (1,0) [0|1] ""  gtw
 SG_ RCM_a100_comDIsystemStatusCntr m100 : 18|1@1+ (1,0) [0|1] ""  gtw
 SG_ RCM_a015_driverABStg2Open m15 : 18|1@1+ (1,0) [0|1] ""  gtw
 SG_ RCM_a037_curAB2ndRowROpen m37 : 18|1@1+ (1,0) [0|1] ""  gtw
 SG_ RCM_a060_seaTrkPosLeftOpen m60 : 18|1@1+ (1,0) [0|1] ""  gtw
 SG_ RCM_a059_bucklHallRightOpen m59 : 18|1@1+ (1,0) [0|1] ""  gtw
 SG_ RCM_a030_farsideABOpen m30 : 18|1@1+ (1,0) [0|1] ""  gtw
 SG_ RCM_a048_sideAccelCPilLCrossCoup m48 : 18|1@1+ (1,0) [0|1] ""  gtw
 SG_ RCM_a106_imuLatAcOffCompPosFLDC m106 : 18|1@1+ (1,0) [0|1] ""  gtw
 SG_ RCM_a093_comVCLEFTStatusCntr m93 : 18|1@1+ (1,0) [0|1] ""  gtw
 SG_ RCM_a035_preten2ndRowROpen m35 : 18|1@1+ (1,0) [0|1] ""  gtw
 SG_ RCM_a075_comChassisCANPH6Cntr m75 : 18|1@1+ (1,0) [0|1] ""  gtw
 SG_ RCM_a065_swDrvrOrientCrossCoup m65 : 18|1@1+ (1,0) [0|1] ""  gtw
 SG_ RCM_a105_imuLongAOffCompPosFLDC m105 : 18|1@1+ (1,0) [0|1] ""  gtw
 SG_ RCM_a103_imuPtchR8OffCompPosFLDC m103 : 18|1@1+ (1,0) [0|1] ""  gtw
 SG_ RCM_a022_pretenLapRightOpen m22 : 18|1@1+ (1,0) [0|1] ""  gtw
 SG_ RCM_a021_pretenLapLeftOpen m21 : 18|1@1+ (1,0) [0|1] ""  gtw
 SG_ RCM_a018_passActiveVentOpen m18 : 18|1@1+ (1,0) [0|1] ""  gtw
 SG_ RCM_a053_presPedProLOption m53 : 18|1@1+ (1,0) [0|1] ""  gtw
 SG_ RCM_a071_comChassisCANPH9Cntr m71 : 18|1@1+ (1,0) [0|1] ""  gtw
 SG_ RCM_a044_upFrontSensorLCrossCoup m44 : 18|1@1+ (1,0) [0|1] ""  gtw
 SG_ RCM_a032_curABLeftOpen m32 : 18|1@1+ (1,0) [0|1] ""  gtw
 SG_ RCM_a063_sbsw2ndRowROpen m63 : 18|1@1+ (1,0) [0|1] ""  gtw
 SG_ RCM_a004_rollAlgoDisabled m4 : 18|1@1+ (1,0) [0|1] ""  gtw
 SG_ RCM_a088_comChassisCANPH2Cntr m88 : 18|1@1+ (1,0) [0|1] ""  gtw
 SG_ RCM_a038_unused3 m38 : 18|1@1+ (1,0) [0|1] ""  gtw
 SG_ RCM_a107_imuVertAOffCompPosFLDC m107 : 18|1@1+ (1,0) [0|1] ""  gtw
 SG_ RCM_a066_sbsw2ndRowLCrossCoup m66 : 18|1@1+ (1,0) [0|1] ""  gtw
 SG_ RCM_a019_pretenShldLeftOpen m19 : 18|1@1+ (1,0) [0|1] ""  gtw
 SG_ RCM_a050_upFrontSensorCCrossCoup m50 : 18|1@1+ (1,0) [0|1] ""  gtw
 SG_ RCM_a078_comOCS1PCntr m78 : 18|1@1+ (1,0) [0|1] ""  gtw
 SG_ RCM_a114_imuRollR8ChnlMonitTmp m114 : 18|1@1+ (1,0) [0|1] ""  gtw
 SG_ RCM_a094_comVCRIGHTStatusCntr m94 : 18|1@1+ (1,0) [0|1] ""  gtw
 SG_ RCM_a073_comChassisCANPH4Cntr m73 : 18|1@1+ (1,0) [0|1] ""  gtw
 SG_ RCM_a000_crashDetectedLeft m0 : 18|1@1+ (1,0) [0|1] ""  gtw
 SG_ RCM_a045_upFrontSensorRCrossCoup m45 : 18|1@1+ (1,0) [0|1] ""  gtw
 SG_ RCM_a061_seaTrkPosRightOpen m61 : 18|1@1+ (1,0) [0|1] ""  gtw
 SG_ RCM_a029_driverABAVOpen m29 : 18|1@1+ (1,0) [0|1] ""  gtw
 SG_ RCM_a034_preten2ndRowLOpen m34 : 18|1@1+ (1,0) [0|1] ""  gtw
 SG_ RCM_a049_sideAccelCPilRCrossCoup m49 : 18|1@1+ (1,0) [0|1] ""  gtw
 SG_ RCM_a020_pretenShldRightOpen m20 : 18|1@1+ (1,0) [0|1] ""  gtw
 SG_ RCM_a054_presPedProROption m54 : 18|1@1+ (1,0) [0|1] ""  gtw
 SG_ RCM_a064_hwcp1CrossCoup m64 : 18|1@1+ (1,0) [0|1] ""  gtw
 SG_ RCM_a016_passABStg1Open m16 : 18|1@1+ (1,0) [0|1] ""  gtw
 SG_ RCM_a007_invalidShtdwnReqSequnce m7 : 18|1@1+ (1,0) [0|1] ""  gtw
 SG_ RCM_a102_imuYawR8OffCompPosFLDC m102 : 18|1@1+ (1,0) [0|1] ""  gtw
 SG_ RCM_a028_sideAB1stRowROpen m28 : 18|1@1+ (1,0) [0|1] ""  gtw
 SG_ RCM_a099_comDItorqueCntr m99 : 18|1@1+ (1,0) [0|1] ""  gtw
 SG_ RCM_a080_comGTWACSCntr m80 : 18|1@1+ (1,0) [0|1] ""  gtw
 SG_ RCM_a101_idfEnviMonitoringEvent m101 : 18|1@1+ (1,0) [0|1] ""  gtw
 SG_ RCM_a062_alrOpen m62 : 18|1@1+ (1,0) [0|1] ""  gtw
 SG_ RCM_a039_unused9 m39 : 18|1@1+ (1,0) [0|1] ""  gtw
 SG_ RCM_a113_imuPitchR8ChnlMonitTmp m113 : 18|1@1+ (1,0) [0|1] ""  gtw
 SG_ RCM_a025_kneeABDrvrOpen m25 : 18|1@1+ (1,0) [0|1] ""  gtw
 SG_ RCM_a051_presFrntLDoorOption m51 : 18|1@1+ (1,0) [0|1] ""  gtw
 SG_ RCM_a026_kneeABPassOpen m26 : 18|1@1+ (1,0) [0|1] ""  gtw
 SG_ RCM_a087_comUnusedCANSilent m87 : 18|1@1+ (1,0) [0|1] ""  gtw
 SG_ RCM_a092_comDASSafetyFrontCntr m92 : 18|1@1+ (1,0) [0|1] ""  gtw
 SG_ RCM_a041_hoodActuatorLOpen m41 : 18|1@1+ (1,0) [0|1] ""  gtw
 SG_ RCM_a047_sideAccelBPilRCrossCoup m47 : 18|1@1+ (1,0) [0|1] ""  gtw
 SG_ RCM_a052_presFrntRDoorOption m52 : 18|1@1+ (1,0) [0|1] ""  gtw
 SG_ RCM_a017_passABStg2Open m17 : 18|1@1+ (1,0) [0|1] ""  gtw
 SG_ RCM_a008_normalShtdwnUnavail m8 : 18|1@1+ (1,0) [0|1] ""  gtw
 SG_ RCM_a070_comChassisCANPH8Cntr m70 : 18|1@1+ (1,0) [0|1] ""  gtw
 SG_ RCM_a001_nearDeployLeft m1 : 18|1@1+ (1,0) [0|1] ""  gtw
 SG_ RCM_a098_comDIchassisControlCntr m98 : 18|1@1+ (1,0) [0|1] ""  gtw
 SG_ RCM_a027_sideAB1stRowLOpen m27 : 18|1@1+ (1,0) [0|1] ""  gtw
 SG_ RCM_a017_passABStg2Sht2Bat m17 : 17|1@1+ (1,0) [0|1] ""  gtw
 SG_ RCM_a060_seaTrkPosLeftShort2Bat m60 : 17|1@1+ (1,0) [0|1] ""  gtw
 SG_ RCM_a115_imuLinAccChnlMonitPerm m115 : 17|1@1+ (1,0) [0|1] ""  gtw
 SG_ RCM_a044_upFrontSensorLSht2Bat m44 : 17|1@1+ (1,0) [0|1] ""  gtw
 SG_ RCM_a065_swDrvrOrientSht2Bat m65 : 17|1@1+ (1,0) [0|1] ""  gtw
 SG_ RCM_a071_comChassisCANPH9ChkSm m71 : 17|1@1+ (1,0) [0|1] ""  gtw
 SG_ RCM_a041_hoodActuatorLSht2Bat m41 : 17|1@1+ (1,0) [0|1] ""  gtw
 SG_ RCM_a061_seaTrkPosRightSht2Bat m61 : 17|1@1+ (1,0) [0|1] ""  gtw
 SG_ RCM_a102_imuYawR8OffCompNegLife m102 : 17|1@1+ (1,0) [0|1] ""  gtw
 SG_ RCM_a101_idfEnviMonitoringError m101 : 17|1@1+ (1,0) [0|1] ""  gtw
 SG_ RCM_a029_driverABAVSht2Bat m29 : 17|1@1+ (1,0) [0|1] ""  gtw
 SG_ RCM_a079_comOCS1DChkSm m79 : 17|1@1+ (1,0) [0|1] ""  gtw
 SG_ RCM_a034_preten2ndRowLSht2Bat m34 : 17|1@1+ (1,0) [0|1] ""  gtw
 SG_ RCM_a097_comDIspeedChkSm m97 : 17|1@1+ (1,0) [0|1] ""  gtw
 SG_ RCM_a045_upFrontSensorRSht2Bat m45 : 17|1@1+ (1,0) [0|1] ""  gtw
 SG_ RCM_a020_pretenShldRightSht2Bat m20 : 17|1@1+ (1,0) [0|1] ""  gtw
 SG_ RCM_a069_comChassisCANPH7ChkSm m69 : 17|1@1+ (1,0) [0|1] ""  gtw
 SG_ RCM_a028_sideAB1stRowRSht2Bat m28 : 17|1@1+ (1,0) [0|1] ""  gtw
 SG_ RCM_a078_comOCS1PChkSm m78 : 17|1@1+ (1,0) [0|1] ""  gtw
 SG_ RCM_a016_passABStg1Sht2Bat m16 : 17|1@1+ (1,0) [0|1] ""  gtw
 SG_ RCM_a050_upFrontSensorCSht2Bat m50 : 17|1@1+ (1,0) [0|1] ""  gtw
 SG_ RCM_a081_comVCFRONTLVPwrChkSm m81 : 17|1@1+ (1,0) [0|1] ""  gtw
 SG_ RCM_a043_ens2Sht2Gnd m43 : 17|1@1+ (1,0) [0|1] ""  gtw
 SG_ RCM_a114_imuRollR8SnsrMonitPerm m114 : 17|1@1+ (1,0) [0|1] ""  gtw
 SG_ RCM_a091_comEPAS3PsysStatusMIA m91 : 17|1@1+ (1,0) [0|1] ""  gtw
 SG_ RCM_a055_imuCalibrationFailed m55 : 17|1@1+ (1,0) [0|1] ""  gtw
 SG_ RCM_a046_sideAccelBPilLSht2Bat m46 : 17|1@1+ (1,0) [0|1] ""  gtw
 SG_ RCM_a021_pretenLapLeftSht2Bat m21 : 17|1@1+ (1,0) [0|1] ""  gtw
 SG_ RCM_a018_passActiveVentSht2Bat m18 : 17|1@1+ (1,0) [0|1] ""  gtw
 SG_ RCM_a104_imuRollR8OffCompNegLife m104 : 17|1@1+ (1,0) [0|1] ""  gtw
 SG_ RCM_a032_curABLeftSht2Bat m32 : 17|1@1+ (1,0) [0|1] ""  gtw
 SG_ RCM_a042_ens1Sht2Gnd m42 : 17|1@1+ (1,0) [0|1] ""  gtw
 SG_ RCM_a012_vinNotProgrammed m12 : 17|1@1+ (1,0) [0|1] ""  gtw
 SG_ RCM_a007_lossOfBackupPowerSupply m7 : 17|1@1+ (1,0) [0|1] ""  gtw
 SG_ RCM_a092_comDASSafetyFrontChkSm m92 : 17|1@1+ (1,0) [0|1] ""  gtw
 SG_ RCM_a048_sideAccelCPilLSht2Bat m48 : 17|1@1+ (1,0) [0|1] ""  gtw
 SG_ RCM_a022_pretenLapRightSht2Bat m22 : 17|1@1+ (1,0) [0|1] ""  gtw
 SG_ RCM_a118_imuInPlaneSnsrMonitPerm m118 : 17|1@1+ (1,0) [0|1] ""  gtw
 SG_ RCM_a103_imuPtchR8OffCompNegLife m103 : 17|1@1+ (1,0) [0|1] ""  gtw
 SG_ RCM_a004_sideAlgoDisabled m4 : 17|1@1+ (1,0) [0|1] ""  gtw
 SG_ RCM_a019_pretenShldLeftSht2Bat m19 : 17|1@1+ (1,0) [0|1] ""  gtw
 SG_ RCM_a063_sbsw2ndRowRSht2Bat m63 : 17|1@1+ (1,0) [0|1] ""  gtw
 SG_ RCM_a100_comDIsystemStatusChkSm m100 : 17|1@1+ (1,0) [0|1] ""  gtw
 SG_ RCM_a105_imuLongAOffCompNegLife m105 : 17|1@1+ (1,0) [0|1] ""  gtw
 SG_ RCM_a037_curAB2ndRowRSht2Bat m37 : 17|1@1+ (1,0) [0|1] ""  gtw
 SG_ RCM_a006_batteryVoltageTooLow m6 : 17|1@1+ (1,0) [0|1] ""  gtw
 SG_ RCM_a013_driveOrientPlausiCheck m13 : 17|1@1+ (1,0) [0|1] ""  gtw
 SG_ RCM_a088_comChassisCANPH2ChkSm m88 : 17|1@1+ (1,0) [0|1] ""  gtw
 SG_ RCM_a112_imuYawR8SnsrMonitPerm m112 : 17|1@1+ (1,0) [0|1] ""  gtw
 SG_ RCM_a015_driverABStg2Sht2Bat m15 : 17|1@1+ (1,0) [0|1] ""  gtw
 SG_ RCM_a106_imuLatAcOffCompNegLife m106 : 17|1@1+ (1,0) [0|1] ""  gtw
 SG_ RCM_a035_preten2ndRowRSht2Bat m35 : 17|1@1+ (1,0) [0|1] ""  gtw
 SG_ RCM_a054_presPedProRInitTyp m54 : 17|1@1+ (1,0) [0|1] ""  gtw
 SG_ RCM_a056_ocs1pWrongCalD m56 : 17|1@1+ (1,0) [0|1] ""  gtw
 SG_ RCM_a030_farsideABSht2Bat m30 : 17|1@1+ (1,0) [0|1] ""  gtw
 SG_ RCM_a070_comChassisCANPH8ChkSm m70 : 17|1@1+ (1,0) [0|1] ""  gtw
 SG_ RCM_a098_comDIchassisCntrlChkSm m98 : 17|1@1+ (1,0) [0|1] ""  gtw
 SG_ RCM_a059_bucklHallRightSht2Bat m59 : 17|1@1+ (1,0) [0|1] ""  gtw
 SG_ RCM_a051_presFrntLDoorInitTyp m51 : 17|1@1+ (1,0) [0|1] ""  gtw
 SG_ RCM_a031_frntCentrABSht2Bat m31 : 17|1@1+ (1,0) [0|1] ""  gtw
 SG_ RCM_a014_driverABStg1Sht2Bat m14 : 17|1@1+ (1,0) [0|1] ""  gtw
 SG_ RCM_a073_comChassisCANPH4ChkSm m73 : 17|1@1+ (1,0) [0|1] ""  gtw
 SG_ RCM_a040_hoodActuatorRSht2Bat m40 : 17|1@1+ (1,0) [0|1] ""  gtw
 SG_ RCM_a094_comVCRIGHTStatusChkSm m94 : 17|1@1+ (1,0) [0|1] ""  gtw
 SG_ RCM_a001_nearDeployRear m1 : 17|1@1+ (1,0) [0|1] ""  gtw
 SG_ RCM_a072_comUnusedChkSm m72 : 17|1@1+ (1,0) [0|1] ""  gtw
 SG_ RCM_a117_imuZaccelChnlMonitPerm m117 : 17|1@1+ (1,0) [0|1] ""  gtw
 SG_ RCM_a036_curAB2ndRowLSht2Bat m36 : 17|1@1+ (1,0) [0|1] ""  gtw
 SG_ RCM_a058_bucklHallLeftSht2Bat m58 : 17|1@1+ (1,0) [0|1] ""  gtw
 SG_ RCM_a023_loadLimLeftSht2Bat m23 : 17|1@1+ (1,0) [0|1] ""  gtw
 SG_ RCM_a077_comEPBRStatusChkSm m77 : 17|1@1+ (1,0) [0|1] ""  gtw
 SG_ RCM_a039_unused8 m39 : 17|1@1+ (1,0) [0|1] ""  gtw
 SG_ RCM_a052_presFrntRDoorInitTyp m52 : 17|1@1+ (1,0) [0|1] ""  gtw
 SG_ RCM_a033_curABRightSht2Bat m33 : 17|1@1+ (1,0) [0|1] ""  gtw
 SG_ RCM_a116_imuLatAccChnlMonitPerm m116 : 17|1@1+ (1,0) [0|1] ""  gtw
 SG_ RCM_a053_presPedProLInitTyp m53 : 17|1@1+ (1,0) [0|1] ""  gtw
 SG_ RCM_a064_hwcp1Sht2Bat m64 : 17|1@1+ (1,0) [0|1] ""  gtw
 SG_ RCM_a074_comChassisCANPH5ChkSm m74 : 17|1@1+ (1,0) [0|1] ""  gtw
 SG_ RCM_a038_unused2 m38 : 17|1@1+ (1,0) [0|1] ""  gtw
 SG_ RCM_a087_comPARTYCANSilent m87 : 17|1@1+ (1,0) [0|1] ""  gtw
 SG_ RCM_a049_sideAccelCPilRSht2Bat m49 : 17|1@1+ (1,0) [0|1] ""  gtw
 SG_ RCM_a107_imuVertAOffCompNegLife m107 : 17|1@1+ (1,0) [0|1] ""  gtw
 SG_ RCM_a075_comChassisCANPH6ChkSm m75 : 17|1@1+ (1,0) [0|1] ""  gtw
 SG_ RCM_a093_comVCLEFTStatusChkSm m93 : 17|1@1+ (1,0) [0|1] ""  gtw
 SG_ RCM_a027_sideAB1stRowLSht2Bat m27 : 17|1@1+ (1,0) [0|1] ""  gtw
 SG_ RCM_a008_lossOfBckupPwrSupMonit m8 : 17|1@1+ (1,0) [0|1] ""  gtw
 SG_ RCM_a047_sideAccelBPilRSht2Bat m47 : 17|1@1+ (1,0) [0|1] ""  gtw
 SG_ RCM_a024_loadLimRightSht2Bat m24 : 17|1@1+ (1,0) [0|1] ""  gtw
 SG_ RCM_a099_comDItorqueChkSm m99 : 17|1@1+ (1,0) [0|1] ""  gtw
 SG_ RCM_a080_comGTWACSChkSm m80 : 17|1@1+ (1,0) [0|1] ""  gtw
 SG_ RCM_a000_crashDetectedRear m0 : 17|1@1+ (1,0) [0|1] ""  gtw
 SG_ RCM_a076_comEPBLStatusChkSm m76 : 17|1@1+ (1,0) [0|1] ""  gtw
 SG_ RCM_a026_kneeABPassSht2Bat m26 : 17|1@1+ (1,0) [0|1] ""  gtw
 SG_ RCM_a095_comESPstatusChkSm m95 : 17|1@1+ (1,0) [0|1] ""  gtw
 SG_ RCM_a062_alrSht2Bat m62 : 17|1@1+ (1,0) [0|1] ""  gtw
 SG_ RCM_a025_kneeABDrvrSht2Bat m25 : 17|1@1+ (1,0) [0|1] ""  gtw
 SG_ RCM_a057_ocs1dWrongCalD m57 : 17|1@1+ (1,0) [0|1] ""  gtw
 SG_ RCM_a066_sbsw2ndRowLSht2Bat m66 : 17|1@1+ (1,0) [0|1] ""  gtw
 SG_ RCM_a089_comChassisCANPH3ChkSm m89 : 17|1@1+ (1,0) [0|1] ""  gtw
 SG_ RCM_a113_imuPitchR8SnsrMonitPerm m113 : 17|1@1+ (1,0) [0|1] ""  gtw
 SG_ RCM_a096_comESPwheelSpeedsChkSm m96 : 17|1@1+ (1,0) [0|1] ""  gtw
 SG_ RCM_a036_curAB2ndRowLSht2Gnd m36 : 16|1@1+ (1,0) [0|1] ""  gtw
 SG_ RCM_a023_loadLimLeftSht2Gnd m23 : 16|1@1+ (1,0) [0|1] ""  gtw
 SG_ RCM_a092_comDASSafetyFrontMIA m92 : 16|1@1+ (1,0) [0|1] ""  gtw
 SG_ RCM_a118_imuInPlaneSnsrMonitTmp m118 : 16|1@1+ (1,0) [0|1] ""  gtw
 SG_ RCM_a083_comGTWCarStateMIA m83 : 16|1@1+ (1,0) [0|1] ""  gtw
 SG_ RCM_a008_lossOfMainPwrSupMonit m8 : 16|1@1+ (1,0) [0|1] ""  gtw
 SG_ RCM_a057_ocs1dFaulted m57 : 16|1@1+ (1,0) [0|1] ""  gtw
 SG_ RCM_a064_hwcp1CheckFail m64 : 16|1@1+ (1,0) [0|1] ""  gtw
 SG_ RCM_a002_airbagsUnArmed m2 : 16|1@1+ (1,0) [0|1] ""  gtw
 SG_ RCM_a102_imuYawR8OffCompPosLife m102 : 16|1@1+ (1,0) [0|1] ""  gtw
 SG_ RCM_a037_curAB2ndRowRSht2Gnd m37 : 16|1@1+ (1,0) [0|1] ""  gtw
 SG_ RCM_a109_immunityThrsholdCrossed m109 : 16|1@1+ (1,0) [0|1] ""  gtw
 SG_ RCM_a087_comChassisCANSilent m87 : 16|1@1+ (1,0) [0|1] ""  gtw
 SG_ RCM_a015_driverABStg2Sht2Gnd m15 : 16|1@1+ (1,0) [0|1] ""  gtw
 SG_ RCM_a061_seaTrkPosRightShort m61 : 16|1@1+ (1,0) [0|1] ""  gtw
 SG_ RCM_a012_vinMismatch m12 : 16|1@1+ (1,0) [0|1] ""  gtw
 SG_ RCM_a038_unused1 m38 : 16|1@1+ (1,0) [0|1] ""  gtw
 SG_ RCM_a011_edrDataAreaLocked m11 : 16|1@1+ (1,0) [0|1] ""  gtw
 SG_ RCM_a010_scmNotFunctional m10 : 16|1@1+ (1,0) [0|1] ""  gtw
 SG_ RCM_a035_preten2ndRowRSht2Gnd m35 : 16|1@1+ (1,0) [0|1] ""  gtw
 SG_ RCM_a084_comTPMSStatusMIA m84 : 16|1@1+ (1,0) [0|1] ""  gtw
 SG_ RCM_a114_imuRollR8SnsrMonitTmp m114 : 16|1@1+ (1,0) [0|1] ""  gtw
 SG_ RCM_a030_farsideABSht2Gnd m30 : 16|1@1+ (1,0) [0|1] ""  gtw
 SG_ RCM_a101_idfMisuseMonitoringErr m101 : 16|1@1+ (1,0) [0|1] ""  gtw
 SG_ RCM_a052_presFrntRDoorComm m52 : 16|1@1+ (1,0) [0|1] ""  gtw
 SG_ RCM_a027_sideAB1stRowLSht2Gnd m27 : 16|1@1+ (1,0) [0|1] ""  gtw
 SG_ RCM_a047_sideAccelBPilRSht2Gnd m47 : 16|1@1+ (1,0) [0|1] ""  gtw
 SG_ RCM_a117_imuZaccelChnlMonitTmp m117 : 16|1@1+ (1,0) [0|1] ""  gtw
 SG_ RCM_a078_comOCS1PMIA m78 : 16|1@1+ (1,0) [0|1] ""  gtw
 SG_ RCM_a094_comVCRIGHTStatusMIA m94 : 16|1@1+ (1,0) [0|1] ""  gtw
 SG_ RCM_a051_presFrntLDoorComm m51 : 16|1@1+ (1,0) [0|1] ""  gtw
 SG_ RCM_a004_frontAlgoDisabled m4 : 16|1@1+ (1,0) [0|1] ""  gtw
 SG_ RCM_a065_swDrvrOrientCheck m65 : 16|1@1+ (1,0) [0|1] ""  gtw
 SG_ RCM_a024_loadLimRightSht2Gnd m24 : 16|1@1+ (1,0) [0|1] ""  gtw
 SG_ RCM_a073_comChassisCANPH4MIA m73 : 16|1@1+ (1,0) [0|1] ""  gtw
 SG_ RCM_a068_comChassisCANBusOff m68 : 16|1@1+ (1,0) [0|1] ""  gtw
 SG_ RCM_a104_imuRollR8OffCompPosLife m104 : 16|1@1+ (1,0) [0|1] ""  gtw
 SG_ RCM_a071_comChassisCANPH9MIA m71 : 16|1@1+ (1,0) [0|1] ""  gtw
 SG_ RCM_a108_crashAlgoWakeupSig m108 : 16|1@1+ (1,0) [0|1] ""  gtw
 SG_ RCM_a054_presPedProRComm m54 : 16|1@1+ (1,0) [0|1] ""  gtw
 SG_ RCM_a085_comGTWCarConfigMIA m85 : 16|1@1+ (1,0) [0|1] ""  gtw
 SG_ RCM_a033_curABRightSht2Gnd m33 : 16|1@1+ (1,0) [0|1] ""  gtw
 SG_ RCM_a005_externalCRCError m5 : 16|1@1+ (1,0) [0|1] ""  gtw
 SG_ RCM_a088_comChassisCANPH2MIA m88 : 16|1@1+ (1,0) [0|1] ""  gtw
 SG_ RCM_a103_imuPtchR8OffCompPosLife m103 : 16|1@1+ (1,0) [0|1] ""  gtw
 SG_ RCM_a049_sideAccelCPilRSht2Gnd m49 : 16|1@1+ (1,0) [0|1] ""  gtw
 SG_ RCM_a112_imuYawR8SnsrMonitTmp m112 : 16|1@1+ (1,0) [0|1] ""  gtw
 SG_ RCM_a007_lossOfMainPowerSupply m7 : 16|1@1+ (1,0) [0|1] ""  gtw
 SG_ RCM_a105_imuLongAOffCompPosLife m105 : 16|1@1+ (1,0) [0|1] ""  gtw
 SG_ RCM_a100_comDIsystemStatusMIA m100 : 16|1@1+ (1,0) [0|1] ""  gtw
 SG_ RCM_a034_preten2ndRowLSht2Gnd m34 : 16|1@1+ (1,0) [0|1] ""  gtw
 SG_ RCM_a060_seaTrkPosLeftShort m60 : 16|1@1+ (1,0) [0|1] ""  gtw
 SG_ RCM_a039_unused7 m39 : 16|1@1+ (1,0) [0|1] ""  gtw
 SG_ RCM_a045_upFrontSensorRSht2Gnd m45 : 16|1@1+ (1,0) [0|1] ""  gtw
 SG_ RCM_a020_pretenShldRightSht2Gnd m20 : 16|1@1+ (1,0) [0|1] ""  gtw
 SG_ RCM_a003_warningIndicatorOn m3 : 16|1@1+ (1,0) [0|1] ""  gtw
 SG_ RCM_a106_imuLatAcOffCompPosLife m106 : 16|1@1+ (1,0) [0|1] ""  gtw
 SG_ RCM_a029_driverABAVSht2Gnd m29 : 16|1@1+ (1,0) [0|1] ""  gtw
 SG_ RCM_a091_comEPAS3PStAnglInvlidQF m91 : 16|1@1+ (1,0) [0|1] ""  gtw
 SG_ RCM_a000_crashDetectedFront m0 : 16|1@1+ (1,0) [0|1] ""  gtw
 SG_ RCM_a028_sideAB1stRowRSht2Gnd m28 : 16|1@1+ (1,0) [0|1] ""  gtw
 SG_ RCM_a016_passABStg1Sht2Gnd m16 : 16|1@1+ (1,0) [0|1] ""  gtw
 SG_ RCM_a067_comCANInitialization m67 : 16|1@1+ (1,0) [0|1] ""  gtw
 SG_ RCM_a009_reprogramLimitExceeded m9 : 16|1@1+ (1,0) [0|1] ""  gtw
 SG_ RCM_a059_bucklHallRightShort m59 : 16|1@1+ (1,0) [0|1] ""  gtw
 SG_ RCM_a075_comChassisCANPH6MIA m75 : 16|1@1+ (1,0) [0|1] ""  gtw
 SG_ RCM_a050_upFrontSensorCSht2Gnd m50 : 16|1@1+ (1,0) [0|1] ""  gtw
 SG_ RCM_a093_comVCLEFTStatusMIA m93 : 16|1@1+ (1,0) [0|1] ""  gtw
 SG_ RCM_a013_driveOrientiInitNotDone m13 : 16|1@1+ (1,0) [0|1] ""  gtw
 SG_ RCM_a026_kneeABPassSht2Gnd m26 : 16|1@1+ (1,0) [0|1] ""  gtw
 SG_ RCM_a001_nearDeployFront m1 : 16|1@1+ (1,0) [0|1] ""  gtw
 SG_ RCM_a025_kneeABDrvrSht2Gnd m25 : 16|1@1+ (1,0) [0|1] ""  gtw
 SG_ RCM_a006_batteryVoltageTooHigh m6 : 16|1@1+ (1,0) [0|1] ""  gtw
 SG_ RCM_a081_comVCFRONTLVPrwMIA m81 : 16|1@1+ (1,0) [0|1] ""  gtw
 SG_ RCM_a044_upFrontSensorLSht2Gnd m44 : 16|1@1+ (1,0) [0|1] ""  gtw
 SG_ RCM_a074_comChassisCANPH5MIA m74 : 16|1@1+ (1,0) [0|1] ""  gtw
 SG_ RCM_a055_imuCalibrationNotDone m55 : 16|1@1+ (1,0) [0|1] ""  gtw
 SG_ RCM_a017_passABStg2Sht2Gnd m17 : 16|1@1+ (1,0) [0|1] ""  gtw
 SG_ RCM_a053_presPedProLComm m53 : 16|1@1+ (1,0) [0|1] ""  gtw
 SG_ RCM_a058_bucklHallLeftShort m58 : 16|1@1+ (1,0) [0|1] ""  gtw
 SG_ RCM_a041_hoodActuatorLSht2Gnd m41 : 16|1@1+ (1,0) [0|1] ""  gtw
 SG_ RCM_a056_ocs1pFaulted m56 : 16|1@1+ (1,0) [0|1] ""  gtw
 SG_ RCM_a082_comUIodoMIA m82 : 16|1@1+ (1,0) [0|1] ""  gtw
 SG_ RCM_a116_imuLatAccChnlMonitTmp m116 : 16|1@1+ (1,0) [0|1] ""  gtw
 SG_ RCM_a048_sideAccelCPilLSht2Gnd m48 : 16|1@1+ (1,0) [0|1] ""  gtw
 SG_ RCM_a032_curABLeftSht2Gnd m32 : 16|1@1+ (1,0) [0|1] ""  gtw
 SG_ RCM_a077_comEPBRStatusMIA m77 : 16|1@1+ (1,0) [0|1] ""  gtw
 SG_ RCM_a022_pretenLapRightSht2Gnd m22 : 16|1@1+ (1,0) [0|1] ""  gtw
 SG_ RCM_a042_ens1Sht2Bat m42 : 16|1@1+ (1,0) [0|1] ""  gtw
 SG_ RCM_a021_pretenLapLeftSht2Gnd m21 : 16|1@1+ (1,0) [0|1] ""  gtw
 SG_ RCM_a018_passActiveVentSht2Gnd m18 : 16|1@1+ (1,0) [0|1] ""  gtw
 SG_ RCM_a072_comUnusedMIA m72 : 16|1@1+ (1,0) [0|1] ""  gtw
 SG_ RCM_a097_comDIspeedMIA m97 : 16|1@1+ (1,0) [0|1] ""  gtw
 SG_ RCM_a063_sbsw2ndRowRSht2Gnd m63 : 16|1@1+ (1,0) [0|1] ""  gtw
 SG_ RCM_a069_comChassisCANPH7MIA m69 : 16|1@1+ (1,0) [0|1] ""  gtw
 SG_ RCM_a079_comOCS1DMIA m79 : 16|1@1+ (1,0) [0|1] ""  gtw
 SG_ RCM_a086_comVINmessageMIA m86 : 16|1@1+ (1,0) [0|1] ""  gtw
 SG_ RCM_a110_inFactoryMode m110 : 16|1@1+ (1,0) [0|1] ""  gtw
 SG_ RCM_a019_pretenShldLeftSht2Gnd m19 : 16|1@1+ (1,0) [0|1] ""  gtw
 SG_ RCM_a107_imuVertAOffCompPosLife m107 : 16|1@1+ (1,0) [0|1] ""  gtw
 SG_ RCM_a043_ens2Sht2Bat m43 : 16|1@1+ (1,0) [0|1] ""  gtw
 SG_ RCM_a070_comChassisCANPH8MIA m70 : 16|1@1+ (1,0) [0|1] ""  gtw
 SG_ RCM_a115_imuLinAccChnlMonitTmp m115 : 16|1@1+ (1,0) [0|1] ""  gtw
 SG_ RCM_a111_diagEnabled m111 : 16|1@1+ (1,0) [0|1] ""  gtw
 SG_ RCM_a098_comDIchassisControlMIA m98 : 16|1@1+ (1,0) [0|1] ""  gtw
 SG_ RCM_a113_imuPitchR8SnsrMonitTmp m113 : 16|1@1+ (1,0) [0|1] ""  gtw
 SG_ RCM_a046_sideAccelBPilLSht2Gnd m46 : 16|1@1+ (1,0) [0|1] ""  gtw
 SG_ RCM_a089_comChassisCANPH3MIA m89 : 16|1@1+ (1,0) [0|1] ""  gtw
 SG_ RCM_a096_comESPwheelSpeedsMIA m96 : 16|1@1+ (1,0) [0|1] ""  gtw
 SG_ RCM_a095_comESPstatusMIA m95 : 16|1@1+ (1,0) [0|1] ""  gtw
 SG_ RCM_a076_comEPBLStatusMIA m76 : 16|1@1+ (1,0) [0|1] ""  gtw
 SG_ RCM_a066_sbsw2ndRowLShort m66 : 16|1@1+ (1,0) [0|1] ""  gtw
 SG_ RCM_a031_frntCentrABSht2Gnd m31 : 16|1@1+ (1,0) [0|1] ""  gtw
 SG_ RCM_a040_hoodActuatorRSht2Gnd m40 : 16|1@1+ (1,0) [0|1] ""  gtw
 SG_ RCM_a090_comPartyCANBusOff m90 : 16|1@1+ (1,0) [0|1] ""  gtw
 SG_ RCM_a099_comDItorqueMIA m99 : 16|1@1+ (1,0) [0|1] ""  gtw
 SG_ RCM_a014_driverABStg1Sht2Gnd m14 : 16|1@1+ (1,0) [0|1] ""  gtw
 SG_ RCM_a080_comGTWACSMIA m80 : 16|1@1+ (1,0) [0|1] ""  gtw
 SG_ RCM_a062_alrShort m62 : 16|1@1+ (1,0) [0|1] ""  gtw
 SG_ RCM_a112_eventDriveOrientation m112 : 14|1@1+ (1,0) [0|1] ""  gtw
 SG_ RCM_a057_eventDriveOrientation m57 : 14|1@1+ (1,0) [0|1] ""  gtw
 SG_ RCM_a082_eventDriveOrientation m82 : 14|1@1+ (1,0) [0|1] ""  gtw
 SG_ RCM_a028_eventDriveOrientation m28 : 14|1@1+ (1,0) [0|1] ""  gtw
 SG_ RCM_a075_eventDriveOrientation m75 : 14|1@1+ (1,0) [0|1] ""  gtw
 SG_ RCM_a013_eventDriveOrientation m13 : 14|1@1+ (1,0) [0|1] ""  gtw
 SG_ RCM_a031_eventDriveOrientation m31 : 14|1@1+ (1,0) [0|1] ""  gtw
 SG_ RCM_a094_eventDriveOrientation m94 : 14|1@1+ (1,0) [0|1] ""  gtw
 SG_ RCM_a041_eventDriveOrientation m41 : 14|1@1+ (1,0) [0|1] ""  gtw
 SG_ RCM_a063_eventDriveOrientation m63 : 14|1@1+ (1,0) [0|1] ""  gtw
 SG_ RCM_a104_eventDriveOrientation m104 : 14|1@1+ (1,0) [0|1] ""  gtw
 SG_ RCM_a027_eventDriveOrientation m27 : 14|1@1+ (1,0) [0|1] ""  gtw
 SG_ RCM_a058_eventDriveOrientation m58 : 14|1@1+ (1,0) [0|1] ""  gtw
 SG_ RCM_a005_eventDriveOrientation m5 : 14|1@1+ (1,0) [0|1] ""  gtw
 SG_ RCM_a091_eventDriveOrientation m91 : 14|1@1+ (1,0) [0|1] ""  gtw
 SG_ RCM_a066_eventDriveOrientation m66 : 14|1@1+ (1,0) [0|1] ""  gtw
 SG_ RCM_a088_eventDriveOrientation m88 : 14|1@1+ (1,0) [0|1] ""  gtw
 SG_ RCM_a101_eventDriveOrientation m101 : 14|1@1+ (1,0) [0|1] ""  gtw
 SG_ RCM_a022_eventDriveOrientation m22 : 14|1@1+ (1,0) [0|1] ""  gtw
 SG_ RCM_a044_eventDriveOrientation m44 : 14|1@1+ (1,0) [0|1] ""  gtw
 SG_ RCM_a118_eventDriveOrientation m118 : 14|1@1+ (1,0) [0|1] ""  gtw
 SG_ RCM_a000_eventDriveOrientation m0 : 14|1@1+ (1,0) [0|1] ""  gtw
 SG_ RCM_a019_eventDriveOrientation m19 : 14|1@1+ (1,0) [0|1] ""  gtw
 SG_ RCM_a074_eventDriveOrientation m74 : 14|1@1+ (1,0) [0|1] ""  gtw
 SG_ RCM_a012_eventDriveOrientation m12 : 14|1@1+ (1,0) [0|1] ""  gtw
 SG_ RCM_a056_eventDriveOrientation m56 : 14|1@1+ (1,0) [0|1] ""  gtw
 SG_ RCM_a113_eventDriveOrientation m113 : 14|1@1+ (1,0) [0|1] ""  gtw
 SG_ RCM_a030_eventDriveOrientation m30 : 14|1@1+ (1,0) [0|1] ""  gtw
 SG_ RCM_a083_eventDriveOrientation m83 : 14|1@1+ (1,0) [0|1] ""  gtw
 SG_ RCM_a029_eventDriveOrientation m29 : 14|1@1+ (1,0) [0|1] ""  gtw
 SG_ RCM_a006_eventDriveOrientation m6 : 14|1@1+ (1,0) [0|1] ""  gtw
 SG_ RCM_a079_eventDriveOrientation m79 : 14|1@1+ (1,0) [0|1] ""  gtw
 SG_ RCM_a097_eventDriveOrientation m97 : 14|1@1+ (1,0) [0|1] ""  gtw
 SG_ RCM_a107_eventDriveOrientation m107 : 14|1@1+ (1,0) [0|1] ""  gtw
 SG_ RCM_a024_eventDriveOrientation m24 : 14|1@1+ (1,0) [0|1] ""  gtw
 SG_ RCM_a042_eventDriveOrientation m42 : 14|1@1+ (1,0) [0|1] ""  gtw
 SG_ RCM_a060_eventDriveOrientation m60 : 14|1@1+ (1,0) [0|1] ""  gtw
 SG_ RCM_a089_eventDriveOrientation m89 : 14|1@1+ (1,0) [0|1] ""  gtw
 SG_ RCM_a001_eventDriveOrientation m1 : 14|1@1+ (1,0) [0|1] ""  gtw
 SG_ RCM_a090_eventDriveOrientation m90 : 14|1@1+ (1,0) [0|1] ""  gtw
 SG_ RCM_a067_eventDriveOrientation m67 : 14|1@1+ (1,0) [0|1] ""  gtw
 SG_ RCM_a023_eventDriveOrientation m23 : 14|1@1+ (1,0) [0|1] ""  gtw
 SG_ RCM_a100_eventDriveOrientation m100 : 14|1@1+ (1,0) [0|1] ""  gtw
 SG_ RCM_a045_eventDriveOrientation m45 : 14|1@1+ (1,0) [0|1] ""  gtw
 SG_ RCM_a018_eventDriveOrientation m18 : 14|1@1+ (1,0) [0|1] ""  gtw
 SG_ RCM_a037_eventDriveOrientation m37 : 14|1@1+ (1,0) [0|1] ""  gtw
 SG_ RCM_a084_eventDriveOrientation m84 : 14|1@1+ (1,0) [0|1] ""  gtw
 SG_ RCM_a114_eventDriveOrientation m114 : 14|1@1+ (1,0) [0|1] ""  gtw
 SG_ RCM_a051_eventDriveOrientation m51 : 14|1@1+ (1,0) [0|1] ""  gtw
 SG_ RCM_a073_eventDriveOrientation m73 : 14|1@1+ (1,0) [0|1] ""  gtw
 SG_ RCM_a015_eventDriveOrientation m15 : 14|1@1+ (1,0) [0|1] ""  gtw
 SG_ RCM_a048_eventDriveOrientation m48 : 14|1@1+ (1,0) [0|1] ""  gtw
 SG_ RCM_a043_eventDriveOrientation m43 : 14|1@1+ (1,0) [0|1] ""  gtw
 SG_ RCM_a078_eventDriveOrientation m78 : 14|1@1+ (1,0) [0|1] ""  gtw
 SG_ RCM_a007_eventDriveOrientation m7 : 14|1@1+ (1,0) [0|1] ""  gtw
 SG_ RCM_a096_eventDriveOrientation m96 : 14|1@1+ (1,0) [0|1] ""  gtw
 SG_ RCM_a061_eventDriveOrientation m61 : 14|1@1+ (1,0) [0|1] ""  gtw
 SG_ RCM_a025_eventDriveOrientation m25 : 14|1@1+ (1,0) [0|1] ""  gtw
 SG_ RCM_a106_eventDriveOrientation m106 : 14|1@1+ (1,0) [0|1] ""  gtw
 SG_ RCM_a002_eventDriveOrientation m2 : 14|1@1+ (1,0) [0|1] ""  gtw
 SG_ RCM_a093_eventDriveOrientation m93 : 14|1@1+ (1,0) [0|1] ""  gtw
 SG_ RCM_a103_eventDriveOrientation m103 : 14|1@1+ (1,0) [0|1] ""  gtw
 SG_ RCM_a020_eventDriveOrientation m20 : 14|1@1+ (1,0) [0|1] ""  gtw
 SG_ RCM_a046_eventDriveOrientation m46 : 14|1@1+ (1,0) [0|1] ""  gtw
 SG_ RCM_a039_eventDriveOrientation m39 : 14|1@1+ (1,0) [0|1] ""  gtw
 SG_ RCM_a064_eventDriveOrientation m64 : 14|1@1+ (1,0) [0|1] ""  gtw
 SG_ RCM_a049_eventDriveOrientation m49 : 14|1@1+ (1,0) [0|1] ""  gtw
 SG_ RCM_a014_eventDriveOrientation m14 : 14|1@1+ (1,0) [0|1] ""  gtw
 SG_ RCM_a036_eventDriveOrientation m36 : 14|1@1+ (1,0) [0|1] ""  gtw
 SG_ RCM_a085_eventDriveOrientation m85 : 14|1@1+ (1,0) [0|1] ""  gtw
 SG_ RCM_a115_eventDriveOrientation m115 : 14|1@1+ (1,0) [0|1] ""  gtw
 SG_ RCM_a050_eventDriveOrientation m50 : 14|1@1+ (1,0) [0|1] ""  gtw
 SG_ RCM_a072_eventDriveOrientation m72 : 14|1@1+ (1,0) [0|1] ""  gtw
 SG_ RCM_a033_eventDriveOrientation m33 : 14|1@1+ (1,0) [0|1] ""  gtw
 SG_ RCM_a080_eventDriveOrientation m80 : 14|1@1+ (1,0) [0|1] ""  gtw
 SG_ RCM_a109_eventDriveOrientation m109 : 14|1@1+ (1,0) [0|1] ""  gtw
 SG_ RCM_a110_eventDriveOrientation m110 : 14|1@1+ (1,0) [0|1] ""  gtw
 SG_ RCM_a055_eventDriveOrientation m55 : 14|1@1+ (1,0) [0|1] ""  gtw
 SG_ RCM_a077_eventDriveOrientation m77 : 14|1@1+ (1,0) [0|1] ""  gtw
 SG_ RCM_a008_eventDriveOrientation m8 : 14|1@1+ (1,0) [0|1] ""  gtw
 SG_ RCM_a011_eventDriveOrientation m11 : 14|1@1+ (1,0) [0|1] ""  gtw
 SG_ RCM_a099_eventDriveOrientation m99 : 14|1@1+ (1,0) [0|1] ""  gtw
 SG_ RCM_a038_eventDriveOrientation m38 : 14|1@1+ (1,0) [0|1] ""  gtw
 SG_ RCM_a065_eventDriveOrientation m65 : 14|1@1+ (1,0) [0|1] ""  gtw
 SG_ RCM_a021_eventDriveOrientation m21 : 14|1@1+ (1,0) [0|1] ""  gtw
 SG_ RCM_a102_eventDriveOrientation m102 : 14|1@1+ (1,0) [0|1] ""  gtw
 SG_ RCM_a003_eventDriveOrientation m3 : 14|1@1+ (1,0) [0|1] ""  gtw
 SG_ RCM_a092_eventDriveOrientation m92 : 14|1@1+ (1,0) [0|1] ""  gtw
 SG_ RCM_a047_eventDriveOrientation m47 : 14|1@1+ (1,0) [0|1] ""  gtw
 SG_ RCM_a068_eventDriveOrientation m68 : 14|1@1+ (1,0) [0|1] ""  gtw
 SG_ RCM_a116_eventDriveOrientation m116 : 14|1@1+ (1,0) [0|1] ""  gtw
 SG_ RCM_a053_eventDriveOrientation m53 : 14|1@1+ (1,0) [0|1] ""  gtw
 SG_ RCM_a086_eventDriveOrientation m86 : 14|1@1+ (1,0) [0|1] ""  gtw
 SG_ RCM_a071_eventDriveOrientation m71 : 14|1@1+ (1,0) [0|1] ""  gtw
 SG_ RCM_a017_eventDriveOrientation m17 : 14|1@1+ (1,0) [0|1] ""  gtw
 SG_ RCM_a035_eventDriveOrientation m35 : 14|1@1+ (1,0) [0|1] ""  gtw
 SG_ RCM_a081_eventDriveOrientation m81 : 14|1@1+ (1,0) [0|1] ""  gtw
 SG_ RCM_a108_eventDriveOrientation m108 : 14|1@1+ (1,0) [0|1] ""  gtw
 SG_ RCM_a009_eventDriveOrientation m9 : 14|1@1+ (1,0) [0|1] ""  gtw
 SG_ RCM_a076_eventDriveOrientation m76 : 14|1@1+ (1,0) [0|1] ""  gtw
 SG_ RCM_a010_eventDriveOrientation m10 : 14|1@1+ (1,0) [0|1] ""  gtw
 SG_ RCM_a098_eventDriveOrientation m98 : 14|1@1+ (1,0) [0|1] ""  gtw
 SG_ RCM_a111_eventDriveOrientation m111 : 14|1@1+ (1,0) [0|1] ""  gtw
 SG_ RCM_a054_eventDriveOrientation m54 : 14|1@1+ (1,0) [0|1] ""  gtw
 SG_ RCM_a032_eventDriveOrientation m32 : 14|1@1+ (1,0) [0|1] ""  gtw
 SG_ RCM_a095_eventDriveOrientation m95 : 14|1@1+ (1,0) [0|1] ""  gtw
 SG_ RCM_a062_eventDriveOrientation m62 : 14|1@1+ (1,0) [0|1] ""  gtw
 SG_ RCM_a105_eventDriveOrientation m105 : 14|1@1+ (1,0) [0|1] ""  gtw
 SG_ RCM_a026_eventDriveOrientation m26 : 14|1@1+ (1,0) [0|1] ""  gtw
 SG_ RCM_a040_eventDriveOrientation m40 : 14|1@1+ (1,0) [0|1] ""  gtw
 SG_ RCM_a059_eventDriveOrientation m59 : 14|1@1+ (1,0) [0|1] ""  gtw
 SG_ RCM_a004_eventDriveOrientation m4 : 14|1@1+ (1,0) [0|1] ""  gtw
 SG_ RCM_a117_eventDriveOrientation m117 : 14|1@1+ (1,0) [0|1] ""  gtw
 SG_ RCM_a052_eventDriveOrientation m52 : 14|1@1+ (1,0) [0|1] ""  gtw
 SG_ RCM_a070_eventDriveOrientation m70 : 14|1@1+ (1,0) [0|1] ""  gtw
 SG_ RCM_a016_eventDriveOrientation m16 : 14|1@1+ (1,0) [0|1] ""  gtw
 SG_ RCM_a034_eventDriveOrientation m34 : 14|1@1+ (1,0) [0|1] ""  gtw
 SG_ RCM_a069_eventDriveOrientation m69 : 14|1@1+ (1,0) [0|1] ""  gtw
 SG_ RCM_a087_eventDriveOrientation m87 : 14|1@1+ (1,0) [0|1] ""  gtw
 SG_ RCM_a017_eventDiagEnabled m17 : 13|1@1+ (1,0) [0|1] ""  gtw
 SG_ RCM_a035_eventDiagEnabled m35 : 13|1@1+ (1,0) [0|1] ""  gtw
 SG_ RCM_a071_eventDiagEnabled m71 : 13|1@1+ (1,0) [0|1] ""  gtw
 SG_ RCM_a086_eventDiagEnabled m86 : 13|1@1+ (1,0) [0|1] ""  gtw
 SG_ RCM_a053_eventDiagEnabled m53 : 13|1@1+ (1,0) [0|1] ""  gtw
 SG_ RCM_a116_eventDiagEnabled m116 : 13|1@1+ (1,0) [0|1] ""  gtw
 SG_ RCM_a068_eventDiagEnabled m68 : 13|1@1+ (1,0) [0|1] ""  gtw
 SG_ RCM_a010_eventDiagEnabled m10 : 13|1@1+ (1,0) [0|1] ""  gtw
 SG_ RCM_a081_eventDiagEnabled m81 : 13|1@1+ (1,0) [0|1] ""  gtw
 SG_ RCM_a111_eventDiagEnabled m111 : 13|1@1+ (1,0) [0|1] ""  gtw
 SG_ RCM_a054_eventDiagEnabled m54 : 13|1@1+ (1,0) [0|1] ""  gtw
 SG_ RCM_a032_eventDiagEnabled m32 : 13|1@1+ (1,0) [0|1] ""  gtw
 SG_ RCM_a108_eventDiagEnabled m108 : 13|1@1+ (1,0) [0|1] ""  gtw
 SG_ RCM_a098_eventDiagEnabled m98 : 13|1@1+ (1,0) [0|1] ""  gtw
 SG_ RCM_a076_eventDiagEnabled m76 : 13|1@1+ (1,0) [0|1] ""  gtw
 SG_ RCM_a009_eventDiagEnabled m9 : 13|1@1+ (1,0) [0|1] ""  gtw
 SG_ RCM_a004_eventDiagEnabled m4 : 13|1@1+ (1,0) [0|1] ""  gtw
 SG_ RCM_a062_eventDiagEnabled m62 : 13|1@1+ (1,0) [0|1] ""  gtw
 SG_ RCM_a040_eventDiagEnabled m40 : 13|1@1+ (1,0) [0|1] ""  gtw
 SG_ RCM_a095_eventDiagEnabled m95 : 13|1@1+ (1,0) [0|1] ""  gtw
 SG_ RCM_a059_eventDiagEnabled m59 : 13|1@1+ (1,0) [0|1] ""  gtw
 SG_ RCM_a026_eventDiagEnabled m26 : 13|1@1+ (1,0) [0|1] ""  gtw
 SG_ RCM_a105_eventDiagEnabled m105 : 13|1@1+ (1,0) [0|1] ""  gtw
 SG_ RCM_a043_eventDiagEnabled m43 : 13|1@1+ (1,0) [0|1] ""  gtw
 SG_ RCM_a096_eventDiagEnabled m96 : 13|1@1+ (1,0) [0|1] ""  gtw
 SG_ RCM_a025_eventDiagEnabled m25 : 13|1@1+ (1,0) [0|1] ""  gtw
 SG_ RCM_a106_eventDiagEnabled m106 : 13|1@1+ (1,0) [0|1] ""  gtw
 SG_ RCM_a078_eventDiagEnabled m78 : 13|1@1+ (1,0) [0|1] ""  gtw
 SG_ RCM_a007_eventDiagEnabled m7 : 13|1@1+ (1,0) [0|1] ""  gtw
 SG_ RCM_a061_eventDiagEnabled m61 : 13|1@1+ (1,0) [0|1] ""  gtw
 SG_ RCM_a039_eventDiagEnabled m39 : 13|1@1+ (1,0) [0|1] ""  gtw
 SG_ RCM_a103_eventDiagEnabled m103 : 13|1@1+ (1,0) [0|1] ""  gtw
 SG_ RCM_a020_eventDiagEnabled m20 : 13|1@1+ (1,0) [0|1] ""  gtw
 SG_ RCM_a002_eventDiagEnabled m2 : 13|1@1+ (1,0) [0|1] ""  gtw
 SG_ RCM_a046_eventDiagEnabled m46 : 13|1@1+ (1,0) [0|1] ""  gtw
 SG_ RCM_a093_eventDiagEnabled m93 : 13|1@1+ (1,0) [0|1] ""  gtw
 SG_ RCM_a064_eventDiagEnabled m64 : 13|1@1+ (1,0) [0|1] ""  gtw
 SG_ RCM_a115_eventDiagEnabled m115 : 13|1@1+ (1,0) [0|1] ""  gtw
 SG_ RCM_a050_eventDiagEnabled m50 : 13|1@1+ (1,0) [0|1] ""  gtw
 SG_ RCM_a036_eventDiagEnabled m36 : 13|1@1+ (1,0) [0|1] ""  gtw
 SG_ RCM_a072_eventDiagEnabled m72 : 13|1@1+ (1,0) [0|1] ""  gtw
 SG_ RCM_a049_eventDiagEnabled m49 : 13|1@1+ (1,0) [0|1] ""  gtw
 SG_ RCM_a014_eventDiagEnabled m14 : 13|1@1+ (1,0) [0|1] ""  gtw
 SG_ RCM_a085_eventDiagEnabled m85 : 13|1@1+ (1,0) [0|1] ""  gtw
 SG_ RCM_a109_eventDiagEnabled m109 : 13|1@1+ (1,0) [0|1] ""  gtw
 SG_ RCM_a077_eventDiagEnabled m77 : 13|1@1+ (1,0) [0|1] ""  gtw
 SG_ RCM_a008_eventDiagEnabled m8 : 13|1@1+ (1,0) [0|1] ""  gtw
 SG_ RCM_a080_eventDiagEnabled m80 : 13|1@1+ (1,0) [0|1] ""  gtw
 SG_ RCM_a099_eventDiagEnabled m99 : 13|1@1+ (1,0) [0|1] ""  gtw
 SG_ RCM_a011_eventDiagEnabled m11 : 13|1@1+ (1,0) [0|1] ""  gtw
 SG_ RCM_a110_eventDiagEnabled m110 : 13|1@1+ (1,0) [0|1] ""  gtw
 SG_ RCM_a055_eventDiagEnabled m55 : 13|1@1+ (1,0) [0|1] ""  gtw
 SG_ RCM_a033_eventDiagEnabled m33 : 13|1@1+ (1,0) [0|1] ""  gtw
 SG_ RCM_a030_eventDiagEnabled m30 : 13|1@1+ (1,0) [0|1] ""  gtw
 SG_ RCM_a029_eventDiagEnabled m29 : 13|1@1+ (1,0) [0|1] ""  gtw
 SG_ RCM_a056_eventDiagEnabled m56 : 13|1@1+ (1,0) [0|1] ""  gtw
 SG_ RCM_a113_eventDiagEnabled m113 : 13|1@1+ (1,0) [0|1] ""  gtw
 SG_ RCM_a074_eventDiagEnabled m74 : 13|1@1+ (1,0) [0|1] ""  gtw
 SG_ RCM_a012_eventDiagEnabled m12 : 13|1@1+ (1,0) [0|1] ""  gtw
 SG_ RCM_a083_eventDiagEnabled m83 : 13|1@1+ (1,0) [0|1] ""  gtw
 SG_ RCM_a097_eventDiagEnabled m97 : 13|1@1+ (1,0) [0|1] ""  gtw
 SG_ RCM_a024_eventDiagEnabled m24 : 13|1@1+ (1,0) [0|1] ""  gtw
 SG_ RCM_a107_eventDiagEnabled m107 : 13|1@1+ (1,0) [0|1] ""  gtw
 SG_ RCM_a006_eventDiagEnabled m6 : 13|1@1+ (1,0) [0|1] ""  gtw
 SG_ RCM_a079_eventDiagEnabled m79 : 13|1@1+ (1,0) [0|1] ""  gtw
 SG_ RCM_a060_eventDiagEnabled m60 : 13|1@1+ (1,0) [0|1] ""  gtw
 SG_ RCM_a042_eventDiagEnabled m42 : 13|1@1+ (1,0) [0|1] ""  gtw
 SG_ RCM_a045_eventDiagEnabled m45 : 13|1@1+ (1,0) [0|1] ""  gtw
 SG_ RCM_a018_eventDiagEnabled m18 : 13|1@1+ (1,0) [0|1] ""  gtw
 SG_ RCM_a090_eventDiagEnabled m90 : 13|1@1+ (1,0) [0|1] ""  gtw
 SG_ RCM_a023_eventDiagEnabled m23 : 13|1@1+ (1,0) [0|1] ""  gtw
 SG_ RCM_a100_eventDiagEnabled m100 : 13|1@1+ (1,0) [0|1] ""  gtw
 SG_ RCM_a001_eventDiagEnabled m1 : 13|1@1+ (1,0) [0|1] ""  gtw
 SG_ RCM_a089_eventDiagEnabled m89 : 13|1@1+ (1,0) [0|1] ""  gtw
 SG_ RCM_a067_eventDiagEnabled m67 : 13|1@1+ (1,0) [0|1] ""  gtw
 SG_ RCM_a073_eventDiagEnabled m73 : 13|1@1+ (1,0) [0|1] ""  gtw
 SG_ RCM_a015_eventDiagEnabled m15 : 13|1@1+ (1,0) [0|1] ""  gtw
 SG_ RCM_a084_eventDiagEnabled m84 : 13|1@1+ (1,0) [0|1] ""  gtw
 SG_ RCM_a037_eventDiagEnabled m37 : 13|1@1+ (1,0) [0|1] ""  gtw
 SG_ RCM_a048_eventDiagEnabled m48 : 13|1@1+ (1,0) [0|1] ""  gtw
 SG_ RCM_a051_eventDiagEnabled m51 : 13|1@1+ (1,0) [0|1] ""  gtw
 SG_ RCM_a114_eventDiagEnabled m114 : 13|1@1+ (1,0) [0|1] ""  gtw
 SG_ RCM_a117_eventDiagEnabled m117 : 13|1@1+ (1,0) [0|1] ""  gtw
 SG_ RCM_a052_eventDiagEnabled m52 : 13|1@1+ (1,0) [0|1] ""  gtw
 SG_ RCM_a034_eventDiagEnabled m34 : 13|1@1+ (1,0) [0|1] ""  gtw
 SG_ RCM_a070_eventDiagEnabled m70 : 13|1@1+ (1,0) [0|1] ""  gtw
 SG_ RCM_a069_eventDiagEnabled m69 : 13|1@1+ (1,0) [0|1] ""  gtw
 SG_ RCM_a087_eventDiagEnabled m87 : 13|1@1+ (1,0) [0|1] ""  gtw
 SG_ RCM_a016_eventDiagEnabled m16 : 13|1@1+ (1,0) [0|1] ""  gtw
 SG_ RCM_a082_eventDiagEnabled m82 : 13|1@1+ (1,0) [0|1] ""  gtw
 SG_ RCM_a031_eventDiagEnabled m31 : 13|1@1+ (1,0) [0|1] ""  gtw
 SG_ RCM_a013_eventDiagEnabled m13 : 13|1@1+ (1,0) [0|1] ""  gtw
 SG_ RCM_a057_eventDiagEnabled m57 : 13|1@1+ (1,0) [0|1] ""  gtw
 SG_ RCM_a112_eventDiagEnabled m112 : 13|1@1+ (1,0) [0|1] ""  gtw
 SG_ RCM_a028_eventDiagEnabled m28 : 13|1@1+ (1,0) [0|1] ""  gtw
 SG_ RCM_a075_eventDiagEnabled m75 : 13|1@1+ (1,0) [0|1] ""  gtw
 SG_ RCM_a041_eventDiagEnabled m41 : 13|1@1+ (1,0) [0|1] ""  gtw
 SG_ RCM_a058_eventDiagEnabled m58 : 13|1@1+ (1,0) [0|1] ""  gtw
 SG_ RCM_a094_eventDiagEnabled m94 : 13|1@1+ (1,0) [0|1] ""  gtw
 SG_ RCM_a104_eventDiagEnabled m104 : 13|1@1+ (1,0) [0|1] ""  gtw
 SG_ RCM_a027_eventDiagEnabled m27 : 13|1@1+ (1,0) [0|1] ""  gtw
 SG_ RCM_a063_eventDiagEnabled m63 : 13|1@1+ (1,0) [0|1] ""  gtw
 SG_ RCM_a005_eventDiagEnabled m5 : 13|1@1+ (1,0) [0|1] ""  gtw
 SG_ RCM_a044_eventDiagEnabled m44 : 13|1@1+ (1,0) [0|1] ""  gtw
 SG_ RCM_a118_eventDiagEnabled m118 : 13|1@1+ (1,0) [0|1] ""  gtw
 SG_ RCM_a091_eventDiagEnabled m91 : 13|1@1+ (1,0) [0|1] ""  gtw
 SG_ RCM_a000_eventDiagEnabled m0 : 13|1@1+ (1,0) [0|1] ""  gtw
 SG_ RCM_a066_eventDiagEnabled m66 : 13|1@1+ (1,0) [0|1] ""  gtw
 SG_ RCM_a019_eventDiagEnabled m19 : 13|1@1+ (1,0) [0|1] ""  gtw
 SG_ RCM_a088_eventDiagEnabled m88 : 13|1@1+ (1,0) [0|1] ""  gtw
 SG_ RCM_a101_eventDiagEnabled m101 : 13|1@1+ (1,0) [0|1] ""  gtw
 SG_ RCM_a022_eventDiagEnabled m22 : 13|1@1+ (1,0) [0|1] ""  gtw
 SG_ RCM_a065_eventDiagEnabled m65 : 13|1@1+ (1,0) [0|1] ""  gtw
 SG_ RCM_a038_eventDiagEnabled m38 : 13|1@1+ (1,0) [0|1] ""  gtw
 SG_ RCM_a021_eventDiagEnabled m21 : 13|1@1+ (1,0) [0|1] ""  gtw
 SG_ RCM_a102_eventDiagEnabled m102 : 13|1@1+ (1,0) [0|1] ""  gtw
 SG_ RCM_a003_eventDiagEnabled m3 : 13|1@1+ (1,0) [0|1] ""  gtw
 SG_ RCM_a047_eventDiagEnabled m47 : 13|1@1+ (1,0) [0|1] ""  gtw
 SG_ RCM_a092_eventDiagEnabled m92 : 13|1@1+ (1,0) [0|1] ""  gtw
 SG_ RCM_a025_eventFactoryMode m25 : 12|1@1+ (1,0) [0|1] ""  gtw
 SG_ RCM_a106_eventFactoryMode m106 : 12|1@1+ (1,0) [0|1] ""  gtw
 SG_ RCM_a096_eventFactoryMode m96 : 12|1@1+ (1,0) [0|1] ""  gtw
 SG_ RCM_a007_eventFactoryMode m7 : 12|1@1+ (1,0) [0|1] ""  gtw
 SG_ RCM_a078_eventFactoryMode m78 : 12|1@1+ (1,0) [0|1] ""  gtw
 SG_ RCM_a061_eventFactoryMode m61 : 12|1@1+ (1,0) [0|1] ""  gtw
 SG_ RCM_a043_eventFactoryMode m43 : 12|1@1+ (1,0) [0|1] ""  gtw
 SG_ RCM_a000_eventFactoryMode m0 : 12|1@1+ (1,0) [0|1] ""  gtw
 SG_ RCM_a019_eventFactoryMode m19 : 12|1@1+ (1,0) [0|1] ""  gtw
 SG_ RCM_a044_eventFactoryMode m44 : 12|1@1+ (1,0) [0|1] ""  gtw
 SG_ RCM_a118_eventFactoryMode m118 : 12|1@1+ (1,0) [0|1] ""  gtw
 SG_ RCM_a088_eventFactoryMode m88 : 12|1@1+ (1,0) [0|1] ""  gtw
 SG_ RCM_a022_eventFactoryMode m22 : 12|1@1+ (1,0) [0|1] ""  gtw
 SG_ RCM_a101_eventFactoryMode m101 : 12|1@1+ (1,0) [0|1] ""  gtw
 SG_ RCM_a091_eventFactoryMode m91 : 12|1@1+ (1,0) [0|1] ""  gtw
 SG_ RCM_a066_eventFactoryMode m66 : 12|1@1+ (1,0) [0|1] ""  gtw
 SG_ RCM_a085_eventFactoryMode m85 : 12|1@1+ (1,0) [0|1] ""  gtw
 SG_ RCM_a036_eventFactoryMode m36 : 12|1@1+ (1,0) [0|1] ""  gtw
 SG_ RCM_a049_eventFactoryMode m49 : 12|1@1+ (1,0) [0|1] ""  gtw
 SG_ RCM_a050_eventFactoryMode m50 : 12|1@1+ (1,0) [0|1] ""  gtw
 SG_ RCM_a115_eventFactoryMode m115 : 12|1@1+ (1,0) [0|1] ""  gtw
 SG_ RCM_a072_eventFactoryMode m72 : 12|1@1+ (1,0) [0|1] ""  gtw
 SG_ RCM_a014_eventFactoryMode m14 : 12|1@1+ (1,0) [0|1] ""  gtw
 SG_ RCM_a086_eventFactoryMode m86 : 12|1@1+ (1,0) [0|1] ""  gtw
 SG_ RCM_a068_eventFactoryMode m68 : 12|1@1+ (1,0) [0|1] ""  gtw
 SG_ RCM_a035_eventFactoryMode m35 : 12|1@1+ (1,0) [0|1] ""  gtw
 SG_ RCM_a071_eventFactoryMode m71 : 12|1@1+ (1,0) [0|1] ""  gtw
 SG_ RCM_a017_eventFactoryMode m17 : 12|1@1+ (1,0) [0|1] ""  gtw
 SG_ RCM_a116_eventFactoryMode m116 : 12|1@1+ (1,0) [0|1] ""  gtw
 SG_ RCM_a053_eventFactoryMode m53 : 12|1@1+ (1,0) [0|1] ""  gtw
 SG_ RCM_a074_eventFactoryMode m74 : 12|1@1+ (1,0) [0|1] ""  gtw
 SG_ RCM_a012_eventFactoryMode m12 : 12|1@1+ (1,0) [0|1] ""  gtw
 SG_ RCM_a056_eventFactoryMode m56 : 12|1@1+ (1,0) [0|1] ""  gtw
 SG_ RCM_a113_eventFactoryMode m113 : 12|1@1+ (1,0) [0|1] ""  gtw
 SG_ RCM_a083_eventFactoryMode m83 : 12|1@1+ (1,0) [0|1] ""  gtw
 SG_ RCM_a029_eventFactoryMode m29 : 12|1@1+ (1,0) [0|1] ""  gtw
 SG_ RCM_a030_eventFactoryMode m30 : 12|1@1+ (1,0) [0|1] ""  gtw
 SG_ RCM_a004_eventFactoryMode m4 : 12|1@1+ (1,0) [0|1] ""  gtw
 SG_ RCM_a040_eventFactoryMode m40 : 12|1@1+ (1,0) [0|1] ""  gtw
 SG_ RCM_a059_eventFactoryMode m59 : 12|1@1+ (1,0) [0|1] ""  gtw
 SG_ RCM_a105_eventFactoryMode m105 : 12|1@1+ (1,0) [0|1] ""  gtw
 SG_ RCM_a026_eventFactoryMode m26 : 12|1@1+ (1,0) [0|1] ""  gtw
 SG_ RCM_a095_eventFactoryMode m95 : 12|1@1+ (1,0) [0|1] ""  gtw
 SG_ RCM_a062_eventFactoryMode m62 : 12|1@1+ (1,0) [0|1] ""  gtw
 SG_ RCM_a045_eventFactoryMode m45 : 12|1@1+ (1,0) [0|1] ""  gtw
 SG_ RCM_a089_eventFactoryMode m89 : 12|1@1+ (1,0) [0|1] ""  gtw
 SG_ RCM_a090_eventFactoryMode m90 : 12|1@1+ (1,0) [0|1] ""  gtw
 SG_ RCM_a018_eventFactoryMode m18 : 12|1@1+ (1,0) [0|1] ""  gtw
 SG_ RCM_a100_eventFactoryMode m100 : 12|1@1+ (1,0) [0|1] ""  gtw
 SG_ RCM_a023_eventFactoryMode m23 : 12|1@1+ (1,0) [0|1] ""  gtw
 SG_ RCM_a067_eventFactoryMode m67 : 12|1@1+ (1,0) [0|1] ""  gtw
 SG_ RCM_a001_eventFactoryMode m1 : 12|1@1+ (1,0) [0|1] ""  gtw
 SG_ RCM_a020_eventFactoryMode m20 : 12|1@1+ (1,0) [0|1] ""  gtw
 SG_ RCM_a103_eventFactoryMode m103 : 12|1@1+ (1,0) [0|1] ""  gtw
 SG_ RCM_a039_eventFactoryMode m39 : 12|1@1+ (1,0) [0|1] ""  gtw
 SG_ RCM_a064_eventFactoryMode m64 : 12|1@1+ (1,0) [0|1] ""  gtw
 SG_ RCM_a002_eventFactoryMode m2 : 12|1@1+ (1,0) [0|1] ""  gtw
 SG_ RCM_a046_eventFactoryMode m46 : 12|1@1+ (1,0) [0|1] ""  gtw
 SG_ RCM_a093_eventFactoryMode m93 : 12|1@1+ (1,0) [0|1] ""  gtw
 SG_ RCM_a087_eventFactoryMode m87 : 12|1@1+ (1,0) [0|1] ""  gtw
 SG_ RCM_a016_eventFactoryMode m16 : 12|1@1+ (1,0) [0|1] ""  gtw
 SG_ RCM_a117_eventFactoryMode m117 : 12|1@1+ (1,0) [0|1] ""  gtw
 SG_ RCM_a052_eventFactoryMode m52 : 12|1@1+ (1,0) [0|1] ""  gtw
 SG_ RCM_a034_eventFactoryMode m34 : 12|1@1+ (1,0) [0|1] ""  gtw
 SG_ RCM_a069_eventFactoryMode m69 : 12|1@1+ (1,0) [0|1] ""  gtw
 SG_ RCM_a070_eventFactoryMode m70 : 12|1@1+ (1,0) [0|1] ""  gtw
 SG_ RCM_a055_eventFactoryMode m55 : 12|1@1+ (1,0) [0|1] ""  gtw
 SG_ RCM_a110_eventFactoryMode m110 : 12|1@1+ (1,0) [0|1] ""  gtw
 SG_ RCM_a109_eventFactoryMode m109 : 12|1@1+ (1,0) [0|1] ""  gtw
 SG_ RCM_a033_eventFactoryMode m33 : 12|1@1+ (1,0) [0|1] ""  gtw
 SG_ RCM_a077_eventFactoryMode m77 : 12|1@1+ (1,0) [0|1] ""  gtw
 SG_ RCM_a008_eventFactoryMode m8 : 12|1@1+ (1,0) [0|1] ""  gtw
 SG_ RCM_a080_eventFactoryMode m80 : 12|1@1+ (1,0) [0|1] ""  gtw
 SG_ RCM_a099_eventFactoryMode m99 : 12|1@1+ (1,0) [0|1] ""  gtw
 SG_ RCM_a011_eventFactoryMode m11 : 12|1@1+ (1,0) [0|1] ""  gtw
 SG_ RCM_a005_eventFactoryMode m5 : 12|1@1+ (1,0) [0|1] ""  gtw
 SG_ RCM_a041_eventFactoryMode m41 : 12|1@1+ (1,0) [0|1] ""  gtw
 SG_ RCM_a058_eventFactoryMode m58 : 12|1@1+ (1,0) [0|1] ""  gtw
 SG_ RCM_a027_eventFactoryMode m27 : 12|1@1+ (1,0) [0|1] ""  gtw
 SG_ RCM_a104_eventFactoryMode m104 : 12|1@1+ (1,0) [0|1] ""  gtw
 SG_ RCM_a094_eventFactoryMode m94 : 12|1@1+ (1,0) [0|1] ""  gtw
 SG_ RCM_a063_eventFactoryMode m63 : 12|1@1+ (1,0) [0|1] ""  gtw
 SG_ RCM_a060_eventFactoryMode m60 : 12|1@1+ (1,0) [0|1] ""  gtw
 SG_ RCM_a079_eventFactoryMode m79 : 12|1@1+ (1,0) [0|1] ""  gtw
 SG_ RCM_a006_eventFactoryMode m6 : 12|1@1+ (1,0) [0|1] ""  gtw
 SG_ RCM_a042_eventFactoryMode m42 : 12|1@1+ (1,0) [0|1] ""  gtw
 SG_ RCM_a097_eventFactoryMode m97 : 12|1@1+ (1,0) [0|1] ""  gtw
 SG_ RCM_a024_eventFactoryMode m24 : 12|1@1+ (1,0) [0|1] ""  gtw
 SG_ RCM_a107_eventFactoryMode m107 : 12|1@1+ (1,0) [0|1] ""  gtw
 SG_ RCM_a047_eventFactoryMode m47 : 12|1@1+ (1,0) [0|1] ""  gtw
 SG_ RCM_a092_eventFactoryMode m92 : 12|1@1+ (1,0) [0|1] ""  gtw
 SG_ RCM_a065_eventFactoryMode m65 : 12|1@1+ (1,0) [0|1] ""  gtw
 SG_ RCM_a003_eventFactoryMode m3 : 12|1@1+ (1,0) [0|1] ""  gtw
 SG_ RCM_a021_eventFactoryMode m21 : 12|1@1+ (1,0) [0|1] ""  gtw
 SG_ RCM_a102_eventFactoryMode m102 : 12|1@1+ (1,0) [0|1] ""  gtw
 SG_ RCM_a038_eventFactoryMode m38 : 12|1@1+ (1,0) [0|1] ""  gtw
 SG_ RCM_a037_eventFactoryMode m37 : 12|1@1+ (1,0) [0|1] ""  gtw
 SG_ RCM_a073_eventFactoryMode m73 : 12|1@1+ (1,0) [0|1] ""  gtw
 SG_ RCM_a048_eventFactoryMode m48 : 12|1@1+ (1,0) [0|1] ""  gtw
 SG_ RCM_a084_eventFactoryMode m84 : 12|1@1+ (1,0) [0|1] ""  gtw
 SG_ RCM_a015_eventFactoryMode m15 : 12|1@1+ (1,0) [0|1] ""  gtw
 SG_ RCM_a051_eventFactoryMode m51 : 12|1@1+ (1,0) [0|1] ""  gtw
 SG_ RCM_a114_eventFactoryMode m114 : 12|1@1+ (1,0) [0|1] ""  gtw
 SG_ RCM_a010_eventFactoryMode m10 : 12|1@1+ (1,0) [0|1] ""  gtw
 SG_ RCM_a108_eventFactoryMode m108 : 12|1@1+ (1,0) [0|1] ""  gtw
 SG_ RCM_a098_eventFactoryMode m98 : 12|1@1+ (1,0) [0|1] ""  gtw
 SG_ RCM_a009_eventFactoryMode m9 : 12|1@1+ (1,0) [0|1] ""  gtw
 SG_ RCM_a076_eventFactoryMode m76 : 12|1@1+ (1,0) [0|1] ""  gtw
 SG_ RCM_a054_eventFactoryMode m54 : 12|1@1+ (1,0) [0|1] ""  gtw
 SG_ RCM_a111_eventFactoryMode m111 : 12|1@1+ (1,0) [0|1] ""  gtw
 SG_ RCM_a081_eventFactoryMode m81 : 12|1@1+ (1,0) [0|1] ""  gtw
 SG_ RCM_a032_eventFactoryMode m32 : 12|1@1+ (1,0) [0|1] ""  gtw
 SG_ RCM_a057_eventFactoryMode m57 : 12|1@1+ (1,0) [0|1] ""  gtw
 SG_ RCM_a112_eventFactoryMode m112 : 12|1@1+ (1,0) [0|1] ""  gtw
 SG_ RCM_a082_eventFactoryMode m82 : 12|1@1+ (1,0) [0|1] ""  gtw
 SG_ RCM_a028_eventFactoryMode m28 : 12|1@1+ (1,0) [0|1] ""  gtw
 SG_ RCM_a031_eventFactoryMode m31 : 12|1@1+ (1,0) [0|1] ""  gtw
 SG_ RCM_a075_eventFactoryMode m75 : 12|1@1+ (1,0) [0|1] ""  gtw
 SG_ RCM_a013_eventFactoryMode m13 : 12|1@1+ (1,0) [0|1] ""  gtw
 SG_ RCM_a082_eventArmStatus m82 : 11|1@1+ (1,0) [0|1] ""  gtw
 SG_ RCM_a013_eventArmStatus m13 : 11|1@1+ (1,0) [0|1] ""  gtw
 SG_ RCM_a057_eventArmStatus m57 : 11|1@1+ (1,0) [0|1] ""  gtw
 SG_ RCM_a112_eventArmStatus m112 : 11|1@1+ (1,0) [0|1] ""  gtw
 SG_ RCM_a031_eventArmStatus m31 : 11|1@1+ (1,0) [0|1] ""  gtw
 SG_ RCM_a028_eventArmStatus m28 : 11|1@1+ (1,0) [0|1] ""  gtw
 SG_ RCM_a075_eventArmStatus m75 : 11|1@1+ (1,0) [0|1] ""  gtw
 SG_ RCM_a036_eventArmStatus m36 : 11|1@1+ (1,0) [0|1] ""  gtw
 SG_ RCM_a014_eventArmStatus m14 : 11|1@1+ (1,0) [0|1] ""  gtw
 SG_ RCM_a072_eventArmStatus m72 : 11|1@1+ (1,0) [0|1] ""  gtw
 SG_ RCM_a115_eventArmStatus m115 : 11|1@1+ (1,0) [0|1] ""  gtw
 SG_ RCM_a050_eventArmStatus m50 : 11|1@1+ (1,0) [0|1] ""  gtw
 SG_ RCM_a049_eventArmStatus m49 : 11|1@1+ (1,0) [0|1] ""  gtw
 SG_ RCM_a085_eventArmStatus m85 : 11|1@1+ (1,0) [0|1] ""  gtw
 SG_ RCM_a000_eventArmStatus m0 : 11|1@1+ (1,0) [0|1] ""  gtw
 SG_ RCM_a118_eventArmStatus m118 : 11|1@1+ (1,0) [0|1] ""  gtw
 SG_ RCM_a044_eventArmStatus m44 : 11|1@1+ (1,0) [0|1] ""  gtw
 SG_ RCM_a088_eventArmStatus m88 : 11|1@1+ (1,0) [0|1] ""  gtw
 SG_ RCM_a066_eventArmStatus m66 : 11|1@1+ (1,0) [0|1] ""  gtw
 SG_ RCM_a091_eventArmStatus m91 : 11|1@1+ (1,0) [0|1] ""  gtw
 SG_ RCM_a019_eventArmStatus m19 : 11|1@1+ (1,0) [0|1] ""  gtw
 SG_ RCM_a022_eventArmStatus m22 : 11|1@1+ (1,0) [0|1] ""  gtw
 SG_ RCM_a101_eventArmStatus m101 : 11|1@1+ (1,0) [0|1] ""  gtw
 SG_ RCM_a047_eventArmStatus m47 : 11|1@1+ (1,0) [0|1] ""  gtw
 SG_ RCM_a021_eventArmStatus m21 : 11|1@1+ (1,0) [0|1] ""  gtw
 SG_ RCM_a102_eventArmStatus m102 : 11|1@1+ (1,0) [0|1] ""  gtw
 SG_ RCM_a065_eventArmStatus m65 : 11|1@1+ (1,0) [0|1] ""  gtw
 SG_ RCM_a092_eventArmStatus m92 : 11|1@1+ (1,0) [0|1] ""  gtw
 SG_ RCM_a003_eventArmStatus m3 : 11|1@1+ (1,0) [0|1] ""  gtw
 SG_ RCM_a038_eventArmStatus m38 : 11|1@1+ (1,0) [0|1] ""  gtw
 SG_ RCM_a097_eventArmStatus m97 : 11|1@1+ (1,0) [0|1] ""  gtw
 SG_ RCM_a060_eventArmStatus m60 : 11|1@1+ (1,0) [0|1] ""  gtw
 SG_ RCM_a024_eventArmStatus m24 : 11|1@1+ (1,0) [0|1] ""  gtw
 SG_ RCM_a107_eventArmStatus m107 : 11|1@1+ (1,0) [0|1] ""  gtw
 SG_ RCM_a006_eventArmStatus m6 : 11|1@1+ (1,0) [0|1] ""  gtw
 SG_ RCM_a079_eventArmStatus m79 : 11|1@1+ (1,0) [0|1] ""  gtw
 SG_ RCM_a042_eventArmStatus m42 : 11|1@1+ (1,0) [0|1] ""  gtw
 SG_ RCM_a076_eventArmStatus m76 : 11|1@1+ (1,0) [0|1] ""  gtw
 SG_ RCM_a009_eventArmStatus m9 : 11|1@1+ (1,0) [0|1] ""  gtw
 SG_ RCM_a081_eventArmStatus m81 : 11|1@1+ (1,0) [0|1] ""  gtw
 SG_ RCM_a098_eventArmStatus m98 : 11|1@1+ (1,0) [0|1] ""  gtw
 SG_ RCM_a010_eventArmStatus m10 : 11|1@1+ (1,0) [0|1] ""  gtw
 SG_ RCM_a054_eventArmStatus m54 : 11|1@1+ (1,0) [0|1] ""  gtw
 SG_ RCM_a111_eventArmStatus m111 : 11|1@1+ (1,0) [0|1] ""  gtw
 SG_ RCM_a108_eventArmStatus m108 : 11|1@1+ (1,0) [0|1] ""  gtw
 SG_ RCM_a032_eventArmStatus m32 : 11|1@1+ (1,0) [0|1] ""  gtw
 SG_ RCM_a084_eventArmStatus m84 : 11|1@1+ (1,0) [0|1] ""  gtw
 SG_ RCM_a015_eventArmStatus m15 : 11|1@1+ (1,0) [0|1] ""  gtw
 SG_ RCM_a051_eventArmStatus m51 : 11|1@1+ (1,0) [0|1] ""  gtw
 SG_ RCM_a114_eventArmStatus m114 : 11|1@1+ (1,0) [0|1] ""  gtw
 SG_ RCM_a037_eventArmStatus m37 : 11|1@1+ (1,0) [0|1] ""  gtw
 SG_ RCM_a073_eventArmStatus m73 : 11|1@1+ (1,0) [0|1] ""  gtw
 SG_ RCM_a048_eventArmStatus m48 : 11|1@1+ (1,0) [0|1] ""  gtw
 SG_ RCM_a016_eventArmStatus m16 : 11|1@1+ (1,0) [0|1] ""  gtw
 SG_ RCM_a087_eventArmStatus m87 : 11|1@1+ (1,0) [0|1] ""  gtw
 SG_ RCM_a034_eventArmStatus m34 : 11|1@1+ (1,0) [0|1] ""  gtw
 SG_ RCM_a052_eventArmStatus m52 : 11|1@1+ (1,0) [0|1] ""  gtw
 SG_ RCM_a117_eventArmStatus m117 : 11|1@1+ (1,0) [0|1] ""  gtw
 SG_ RCM_a070_eventArmStatus m70 : 11|1@1+ (1,0) [0|1] ""  gtw
 SG_ RCM_a069_eventArmStatus m69 : 11|1@1+ (1,0) [0|1] ""  gtw
 SG_ RCM_a093_eventArmStatus m93 : 11|1@1+ (1,0) [0|1] ""  gtw
 SG_ RCM_a064_eventArmStatus m64 : 11|1@1+ (1,0) [0|1] ""  gtw
 SG_ RCM_a039_eventArmStatus m39 : 11|1@1+ (1,0) [0|1] ""  gtw
 SG_ RCM_a103_eventArmStatus m103 : 11|1@1+ (1,0) [0|1] ""  gtw
 SG_ RCM_a020_eventArmStatus m20 : 11|1@1+ (1,0) [0|1] ""  gtw
 SG_ RCM_a002_eventArmStatus m2 : 11|1@1+ (1,0) [0|1] ""  gtw
 SG_ RCM_a046_eventArmStatus m46 : 11|1@1+ (1,0) [0|1] ""  gtw
 SG_ RCM_a058_eventArmStatus m58 : 11|1@1+ (1,0) [0|1] ""  gtw
 SG_ RCM_a005_eventArmStatus m5 : 11|1@1+ (1,0) [0|1] ""  gtw
 SG_ RCM_a063_eventArmStatus m63 : 11|1@1+ (1,0) [0|1] ""  gtw
 SG_ RCM_a041_eventArmStatus m41 : 11|1@1+ (1,0) [0|1] ""  gtw
 SG_ RCM_a094_eventArmStatus m94 : 11|1@1+ (1,0) [0|1] ""  gtw
 SG_ RCM_a027_eventArmStatus m27 : 11|1@1+ (1,0) [0|1] ""  gtw
 SG_ RCM_a104_eventArmStatus m104 : 11|1@1+ (1,0) [0|1] ""  gtw
 SG_ RCM_a080_eventArmStatus m80 : 11|1@1+ (1,0) [0|1] ""  gtw
 SG_ RCM_a099_eventArmStatus m99 : 11|1@1+ (1,0) [0|1] ""  gtw
 SG_ RCM_a011_eventArmStatus m11 : 11|1@1+ (1,0) [0|1] ""  gtw
 SG_ RCM_a055_eventArmStatus m55 : 11|1@1+ (1,0) [0|1] ""  gtw
 SG_ RCM_a110_eventArmStatus m110 : 11|1@1+ (1,0) [0|1] ""  gtw
 SG_ RCM_a109_eventArmStatus m109 : 11|1@1+ (1,0) [0|1] ""  gtw
 SG_ RCM_a033_eventArmStatus m33 : 11|1@1+ (1,0) [0|1] ""  gtw
 SG_ RCM_a077_eventArmStatus m77 : 11|1@1+ (1,0) [0|1] ""  gtw
 SG_ RCM_a008_eventArmStatus m8 : 11|1@1+ (1,0) [0|1] ""  gtw
 SG_ RCM_a083_eventArmStatus m83 : 11|1@1+ (1,0) [0|1] ""  gtw
 SG_ RCM_a113_eventArmStatus m113 : 11|1@1+ (1,0) [0|1] ""  gtw
 SG_ RCM_a056_eventArmStatus m56 : 11|1@1+ (1,0) [0|1] ""  gtw
 SG_ RCM_a030_eventArmStatus m30 : 11|1@1+ (1,0) [0|1] ""  gtw
 SG_ RCM_a012_eventArmStatus m12 : 11|1@1+ (1,0) [0|1] ""  gtw
 SG_ RCM_a029_eventArmStatus m29 : 11|1@1+ (1,0) [0|1] ""  gtw
 SG_ RCM_a074_eventArmStatus m74 : 11|1@1+ (1,0) [0|1] ""  gtw
 SG_ RCM_a017_eventArmStatus m17 : 11|1@1+ (1,0) [0|1] ""  gtw
 SG_ RCM_a053_eventArmStatus m53 : 11|1@1+ (1,0) [0|1] ""  gtw
 SG_ RCM_a116_eventArmStatus m116 : 11|1@1+ (1,0) [0|1] ""  gtw
 SG_ RCM_a035_eventArmStatus m35 : 11|1@1+ (1,0) [0|1] ""  gtw
 SG_ RCM_a071_eventArmStatus m71 : 11|1@1+ (1,0) [0|1] ""  gtw
 SG_ RCM_a068_eventArmStatus m68 : 11|1@1+ (1,0) [0|1] ""  gtw
 SG_ RCM_a086_eventArmStatus m86 : 11|1@1+ (1,0) [0|1] ""  gtw
 SG_ RCM_a045_eventArmStatus m45 : 11|1@1+ (1,0) [0|1] ""  gtw
 SG_ RCM_a089_eventArmStatus m89 : 11|1@1+ (1,0) [0|1] ""  gtw
 SG_ RCM_a090_eventArmStatus m90 : 11|1@1+ (1,0) [0|1] ""  gtw
 SG_ RCM_a067_eventArmStatus m67 : 11|1@1+ (1,0) [0|1] ""  gtw
 SG_ RCM_a018_eventArmStatus m18 : 11|1@1+ (1,0) [0|1] ""  gtw
 SG_ RCM_a100_eventArmStatus m100 : 11|1@1+ (1,0) [0|1] ""  gtw
 SG_ RCM_a023_eventArmStatus m23 : 11|1@1+ (1,0) [0|1] ""  gtw
 SG_ RCM_a001_eventArmStatus m1 : 11|1@1+ (1,0) [0|1] ""  gtw
 SG_ RCM_a040_eventArmStatus m40 : 11|1@1+ (1,0) [0|1] ""  gtw
 SG_ RCM_a062_eventArmStatus m62 : 11|1@1+ (1,0) [0|1] ""  gtw
 SG_ RCM_a095_eventArmStatus m95 : 11|1@1+ (1,0) [0|1] ""  gtw
 SG_ RCM_a026_eventArmStatus m26 : 11|1@1+ (1,0) [0|1] ""  gtw
 SG_ RCM_a105_eventArmStatus m105 : 11|1@1+ (1,0) [0|1] ""  gtw
 SG_ RCM_a004_eventArmStatus m4 : 11|1@1+ (1,0) [0|1] ""  gtw
 SG_ RCM_a059_eventArmStatus m59 : 11|1@1+ (1,0) [0|1] ""  gtw
 SG_ RCM_a043_eventArmStatus m43 : 11|1@1+ (1,0) [0|1] ""  gtw
 SG_ RCM_a096_eventArmStatus m96 : 11|1@1+ (1,0) [0|1] ""  gtw
 SG_ RCM_a078_eventArmStatus m78 : 11|1@1+ (1,0) [0|1] ""  gtw
 SG_ RCM_a007_eventArmStatus m7 : 11|1@1+ (1,0) [0|1] ""  gtw
 SG_ RCM_a025_eventArmStatus m25 : 11|1@1+ (1,0) [0|1] ""  gtw
 SG_ RCM_a106_eventArmStatus m106 : 11|1@1+ (1,0) [0|1] ""  gtw
 SG_ RCM_a061_eventArmStatus m61 : 11|1@1+ (1,0) [0|1] ""  gtw
 SG_ RCM_alertState : 10|1@1+ (1,0) [0|1] ""  gtw
 SG_ RCM_alertID M : 0|10@1+ (1,0) [0|118] ""  gtw

BO_ 847 OCS1P_debugCushionSelfCNTComp: 8 CH
 SG_ OCS1P_deltaFreqCushionSelf : 32|32@1- (0.001,0) [-2147483.648|2147483.647] "Hz"  X
 SG_ OCS1P_cushionSelfCNTFreqComp : 0|32@1+ (0.001,0) [0|4294967.295] "Hz"  X

BO_ 545 VCFRONT_LVPowerState: 8 CH
 SG_ VCFRONT_LVPowerStateChecksum : 56|8@1+ (1,0) [0|255] ""  ibst
 SG_ VCFRONT_LVPowerStateCounter : 52|4@1+ (1,0) [0|15] ""  ibst
 SG_ VCFRONT_uiAudioLVState m0 : 50|2@1+ (1,0) [0|3] ""  X
 SG_ VCFRONT_uiHiCurrentLVState m0 : 48|2@1+ (1,0) [0|3] ""  X
 SG_ VCFRONT_vcrightHiCurrentLVState m0 : 46|2@1+ (1,0) [0|3] ""  X
 SG_ VCFRONT_vcleftHiCurrentLVState m0 : 44|2@1+ (1,0) [0|3] ""  X
 SG_ VCFRONT_ocsLVRequest m0 : 42|2@1+ (1,0) [0|3] ""  X
 SG_ VCFRONT_oilPumpRearLVRequest m0 : 40|2@1+ (1,0) [0|3] ""  X
 SG_ VCFRONT_oilPumpFrontLVState m0 : 38|2@1+ (1,0) [0|3] ""  X
 SG_ VCFRONT_disLVState m0 : 36|2@1+ (1,0) [0|3] ""  X
 SG_ VCFRONT_diLVRequest m0 : 34|2@1+ (1,0) [0|3] ""  X
 SG_ VCFRONT_das2HighCurrentLVState m0 : 32|2@1+ (1,0) [0|3] ""  das
 SG_ VCFRONT_das1HighCurrentLVState m0 : 30|2@1+ (1,0) [0|3] ""  das
 SG_ VCFRONT_amplifierLVRequest m0 : 28|2@1+ (1,0) [0|3] ""  X
 SG_ VCFRONT_tunerLVRequest m0 : 26|2@1+ (1,0) [0|3] ""  X
 SG_ VCFRONT_iBoosterLVState m0 : 24|2@1+ (1,0) [0|3] ""  ibst
 SG_ VCFRONT_rcmLVRequest m0 : 22|2@1+ (1,0) [0|3] ""  rcm
 SG_ VCFRONT_tpmsLVRequest m0 : 20|2@1+ (1,0) [0|3] ""  tpms
 SG_ VCFRONT_sccmLVRequest m0 : 18|2@1+ (1,0) [0|3] ""  X
 SG_ VCFRONT_pcsLVState m1 : 16|2@1+ (1,0) [0|3] ""  X
 SG_ VCFRONT_ptcLVRequest m0 : 16|2@1+ (1,0) [0|3] ""  X
 SG_ VCFRONT_hvacCompLVState m0 : 14|2@1+ (1,0) [0|3] ""  X
 SG_ VCFRONT_tasLVState m1 : 14|2@1+ (1,0) [0|3] ""  X
 SG_ VCFRONT_hvcLVRequest m1 : 12|2@1+ (1,0) [0|3] ""  X
 SG_ VCFRONT_radcLVState m0 : 12|2@1+ (1,0) [0|3] ""  X
 SG_ VCFRONT_epasLVState m1 : 10|2@1+ (1,0) [0|3] ""  epas3s
 SG_ VCFRONT_espLVState m0 : 10|2@1+ (1,0) [0|3] ""  ibst
 SG_ VCFRONT_parkLVState m0 : 8|2@1+ (1,0) [0|3] ""  X
 SG_ VCFRONT_cpLVRequest m1 : 8|2@1+ (1,0) [0|3] ""  X
 SG_ VCFRONT_vehiclePowerState : 5|2@1+ (1,0) [0|3] ""  park
 SG_ VCFRONT_LVPowerStateIndex M : 0|5@1+ (1,0) [0|1] ""  epas3s

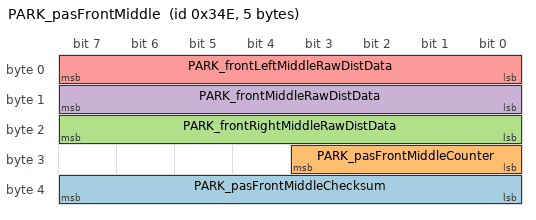
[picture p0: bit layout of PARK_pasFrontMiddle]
BO_ 846 PARK_pasFrontMiddle: 5 CH
 SG_ PARK_pasFrontMiddleChecksum : 32|8@1+ (1,0) [0|255] ""  X
 SG_ PARK_pasFrontMiddleCounter : 24|4@1+ (1,0) [0|15] ""  X
 SG_ PARK_frontRightMiddleRawDistData : 16|8@1+ (1,0) [0|255] "cm"  das
 SG_ PARK_frontMiddleRawDistData : 8|8@1+ (1,0) [0|255] "cm"  das
 SG_ PARK_frontLeftMiddleRawDistData : 0|8@1+ (1,0) [0|255] "cm"  das

BA_DEF_ SG_  "SystemSignalLongSymbol" STRING ;
BA_DEF_DEF_  "SystemSignalLongSymbol" "";
VAL_ 1297 RCM_a001_eventIDFsignal 1 "RCM_DAS_IDF_ACTIVE" 0 "RCM_DAS_IDF_NOT_ACTIVE" ;
VAL_ 1297 RCM_a100_eventIDFsignal 1 "RCM_DAS_IDF_ACTIVE" 0 "RCM_DAS_IDF_NOT_ACTIVE" ;
VAL_ 1297 RCM_a023_eventIDFsignal 1 "RCM_DAS_IDF_ACTIVE" 0 "RCM_DAS_IDF_NOT_ACTIVE" ;
VAL_ 1297 RCM_a090_eventIDFsignal 1 "RCM_DAS_IDF_ACTIVE" 0 "RCM_DAS_IDF_NOT_ACTIVE" ;
VAL_ 1297 RCM_a089_eventIDFsignal 1 "RCM_DAS_IDF_ACTIVE" 0 "RCM_DAS_IDF_NOT_ACTIVE" ;
VAL_ 1297 RCM_a068_eventIDFsignal 1 "RCM_DAS_IDF_ACTIVE" 0 "RCM_DAS_IDF_NOT_ACTIVE" ;
VAL_ 1297 RCM_a071_eventIDFsignal 1 "RCM_DAS_IDF_ACTIVE" 0 "RCM_DAS_IDF_NOT_ACTIVE" ;
VAL_ 1297 RCM_a086_eventIDFsignal 1 "RCM_DAS_IDF_ACTIVE" 0 "RCM_DAS_IDF_NOT_ACTIVE" ;
VAL_ 1297 RCM_a053_eventIDFsignal 1 "RCM_DAS_IDF_ACTIVE" 0 "RCM_DAS_IDF_NOT_ACTIVE" ;
VAL_ 1297 RCM_a116_eventIDFsignal 1 "RCM_DAS_IDF_ACTIVE" 0 "RCM_DAS_IDF_NOT_ACTIVE" ;
VAL_ 1297 RCM_a017_eventIDFsignal 1 "RCM_DAS_IDF_ACTIVE" 0 "RCM_DAS_IDF_NOT_ACTIVE" ;
VAL_ 1297 RCM_a035_eventIDFsignal 1 "RCM_DAS_IDF_ACTIVE" 0 "RCM_DAS_IDF_NOT_ACTIVE" ;
VAL_ 1297 RCM_a056_eventIDFsignal 1 "RCM_DAS_IDF_ACTIVE" 0 "RCM_DAS_IDF_NOT_ACTIVE" ;
VAL_ 1297 RCM_a113_eventIDFsignal 1 "RCM_DAS_IDF_ACTIVE" 0 "RCM_DAS_IDF_NOT_ACTIVE" ;
VAL_ 1297 RCM_a012_eventIDFsignal 1 "RCM_DAS_IDF_ACTIVE" 0 "RCM_DAS_IDF_NOT_ACTIVE" ;
VAL_ 1297 RCM_a074_eventIDFsignal 1 "RCM_DAS_IDF_ACTIVE" 0 "RCM_DAS_IDF_NOT_ACTIVE" ;
VAL_ 1297 RCM_a029_eventIDFsignal 1 "RCM_DAS_IDF_ACTIVE" 0 "RCM_DAS_IDF_NOT_ACTIVE" ;
VAL_ 1297 RCM_a083_eventIDFsignal 1 "RCM_DAS_IDF_ACTIVE" 0 "RCM_DAS_IDF_NOT_ACTIVE" ;
VAL_ 1297 RCM_a030_eventIDFsignal 1 "RCM_DAS_IDF_ACTIVE" 0 "RCM_DAS_IDF_NOT_ACTIVE" ;
VAL_ 1297 RCM_a033_eventIDFsignal 1 "RCM_DAS_IDF_ACTIVE" 0 "RCM_DAS_IDF_NOT_ACTIVE" ;
VAL_ 1297 RCM_a011_eventIDFsignal 1 "RCM_DAS_IDF_ACTIVE" 0 "RCM_DAS_IDF_NOT_ACTIVE" ;
VAL_ 1297 RCM_a077_eventIDFsignal 1 "RCM_DAS_IDF_ACTIVE" 0 "RCM_DAS_IDF_NOT_ACTIVE" ;
VAL_ 1297 RCM_a008_eventIDFsignal 1 "RCM_DAS_IDF_ACTIVE" 0 "RCM_DAS_IDF_NOT_ACTIVE" ;
VAL_ 1297 RCM_a109_eventIDFsignal 1 "RCM_DAS_IDF_ACTIVE" 0 "RCM_DAS_IDF_NOT_ACTIVE" ;
VAL_ 1297 RCM_a099_eventIDFsignal 1 "RCM_DAS_IDF_ACTIVE" 0 "RCM_DAS_IDF_NOT_ACTIVE" ;
VAL_ 1297 RCM_a055_eventIDFsignal 1 "RCM_DAS_IDF_ACTIVE" 0 "RCM_DAS_IDF_NOT_ACTIVE" ;
VAL_ 1297 RCM_a110_eventIDFsignal 1 "RCM_DAS_IDF_ACTIVE" 0 "RCM_DAS_IDF_NOT_ACTIVE" ;
VAL_ 1297 RCM_a080_eventIDFsignal 1 "RCM_DAS_IDF_ACTIVE" 0 "RCM_DAS_IDF_NOT_ACTIVE" ;
VAL_ 1297 RCM_a094_eventIDFsignal 1 "RCM_DAS_IDF_ACTIVE" 0 "RCM_DAS_IDF_NOT_ACTIVE" ;
VAL_ 1297 RCM_a005_eventIDFsignal 1 "RCM_DAS_IDF_ACTIVE" 0 "RCM_DAS_IDF_NOT_ACTIVE" ;
VAL_ 1297 RCM_a027_eventIDFsignal 1 "RCM_DAS_IDF_ACTIVE" 0 "RCM_DAS_IDF_NOT_ACTIVE" ;
VAL_ 1297 RCM_a104_eventIDFsignal 1 "RCM_DAS_IDF_ACTIVE" 0 "RCM_DAS_IDF_NOT_ACTIVE" ;
VAL_ 1297 RCM_a058_eventIDFsignal 1 "RCM_DAS_IDF_ACTIVE" 0 "RCM_DAS_IDF_NOT_ACTIVE" ;
VAL_ 1297 RCM_a041_eventIDFsignal 1 "RCM_DAS_IDF_ACTIVE" 0 "RCM_DAS_IDF_NOT_ACTIVE" ;
VAL_ 1297 RCM_a063_eventIDFsignal 1 "RCM_DAS_IDF_ACTIVE" 0 "RCM_DAS_IDF_NOT_ACTIVE" ;
VAL_ 1297 RCM_a093_eventIDFsignal 1 "RCM_DAS_IDF_ACTIVE" 0 "RCM_DAS_IDF_NOT_ACTIVE" ;
VAL_ 1297 RCM_a020_eventIDFsignal 1 "RCM_DAS_IDF_ACTIVE" 0 "RCM_DAS_IDF_NOT_ACTIVE" ;
VAL_ 1297 RCM_a103_eventIDFsignal 1 "RCM_DAS_IDF_ACTIVE" 0 "RCM_DAS_IDF_NOT_ACTIVE" ;
VAL_ 1297 RCM_a002_eventIDFsignal 1 "RCM_DAS_IDF_ACTIVE" 0 "RCM_DAS_IDF_NOT_ACTIVE" ;
VAL_ 1297 RCM_a039_eventIDFsignal 1 "RCM_DAS_IDF_ACTIVE" 0 "RCM_DAS_IDF_NOT_ACTIVE" ;
VAL_ 1297 RCM_a064_eventIDFsignal 1 "RCM_DAS_IDF_ACTIVE" 0 "RCM_DAS_IDF_NOT_ACTIVE" ;
VAL_ 1297 RCM_a046_eventIDFsignal 1 "RCM_DAS_IDF_ACTIVE" 0 "RCM_DAS_IDF_NOT_ACTIVE" ;
VAL_ 1297 RCM_a070_eventIDFsignal 1 "RCM_DAS_IDF_ACTIVE" 0 "RCM_DAS_IDF_NOT_ACTIVE" ;
VAL_ 1297 RCM_a034_eventIDFsignal 1 "RCM_DAS_IDF_ACTIVE" 0 "RCM_DAS_IDF_NOT_ACTIVE" ;
VAL_ 1297 RCM_a052_eventIDFsignal 1 "RCM_DAS_IDF_ACTIVE" 0 "RCM_DAS_IDF_NOT_ACTIVE" ;
VAL_ 1297 RCM_a117_eventIDFsignal 1 "RCM_DAS_IDF_ACTIVE" 0 "RCM_DAS_IDF_NOT_ACTIVE" ;
VAL_ 1297 RCM_a087_eventIDFsignal 1 "RCM_DAS_IDF_ACTIVE" 0 "RCM_DAS_IDF_NOT_ACTIVE" ;
VAL_ 1297 RCM_a069_eventIDFsignal 1 "RCM_DAS_IDF_ACTIVE" 0 "RCM_DAS_IDF_NOT_ACTIVE" ;
VAL_ 1297 RCM_a016_eventIDFsignal 1 "RCM_DAS_IDF_ACTIVE" 0 "RCM_DAS_IDF_NOT_ACTIVE" ;
VAL_ 1297 RCM_a051_eventIDFsignal 1 "RCM_DAS_IDF_ACTIVE" 0 "RCM_DAS_IDF_NOT_ACTIVE" ;
VAL_ 1297 RCM_a114_eventIDFsignal 1 "RCM_DAS_IDF_ACTIVE" 0 "RCM_DAS_IDF_NOT_ACTIVE" ;
VAL_ 1297 RCM_a015_eventIDFsignal 1 "RCM_DAS_IDF_ACTIVE" 0 "RCM_DAS_IDF_NOT_ACTIVE" ;
VAL_ 1297 RCM_a073_eventIDFsignal 1 "RCM_DAS_IDF_ACTIVE" 0 "RCM_DAS_IDF_NOT_ACTIVE" ;
VAL_ 1297 RCM_a037_eventIDFsignal 1 "RCM_DAS_IDF_ACTIVE" 0 "RCM_DAS_IDF_NOT_ACTIVE" ;
VAL_ 1297 RCM_a084_eventIDFsignal 1 "RCM_DAS_IDF_ACTIVE" 0 "RCM_DAS_IDF_NOT_ACTIVE" ;
VAL_ 1297 RCM_a048_eventIDFsignal 1 "RCM_DAS_IDF_ACTIVE" 0 "RCM_DAS_IDF_NOT_ACTIVE" ;
VAL_ 1297 RCM_a098_eventIDFsignal 1 "RCM_DAS_IDF_ACTIVE" 0 "RCM_DAS_IDF_NOT_ACTIVE" ;
VAL_ 1297 RCM_a081_eventIDFsignal 1 "RCM_DAS_IDF_ACTIVE" 0 "RCM_DAS_IDF_NOT_ACTIVE" ;
VAL_ 1297 RCM_a108_eventIDFsignal 1 "RCM_DAS_IDF_ACTIVE" 0 "RCM_DAS_IDF_NOT_ACTIVE" ;
VAL_ 1297 RCM_a054_eventIDFsignal 1 "RCM_DAS_IDF_ACTIVE" 0 "RCM_DAS_IDF_NOT_ACTIVE" ;
VAL_ 1297 RCM_a111_eventIDFsignal 1 "RCM_DAS_IDF_ACTIVE" 0 "RCM_DAS_IDF_NOT_ACTIVE" ;
VAL_ 1297 RCM_a032_eventIDFsignal 1 "RCM_DAS_IDF_ACTIVE" 0 "RCM_DAS_IDF_NOT_ACTIVE" ;
VAL_ 1297 RCM_a009_eventIDFsignal 1 "RCM_DAS_IDF_ACTIVE" 0 "RCM_DAS_IDF_NOT_ACTIVE" ;
VAL_ 1297 RCM_a076_eventIDFsignal 1 "RCM_DAS_IDF_ACTIVE" 0 "RCM_DAS_IDF_NOT_ACTIVE" ;
VAL_ 1297 RCM_a010_eventIDFsignal 1 "RCM_DAS_IDF_ACTIVE" 0 "RCM_DAS_IDF_NOT_ACTIVE" ;
VAL_ 1297 RCM_a042_eventIDFsignal 1 "RCM_DAS_IDF_ACTIVE" 0 "RCM_DAS_IDF_NOT_ACTIVE" ;
VAL_ 1297 RCM_a079_eventIDFsignal 1 "RCM_DAS_IDF_ACTIVE" 0 "RCM_DAS_IDF_NOT_ACTIVE" ;
VAL_ 1297 RCM_a006_eventIDFsignal 1 "RCM_DAS_IDF_ACTIVE" 0 "RCM_DAS_IDF_NOT_ACTIVE" ;
VAL_ 1297 RCM_a097_eventIDFsignal 1 "RCM_DAS_IDF_ACTIVE" 0 "RCM_DAS_IDF_NOT_ACTIVE" ;
VAL_ 1297 RCM_a060_eventIDFsignal 1 "RCM_DAS_IDF_ACTIVE" 0 "RCM_DAS_IDF_NOT_ACTIVE" ;
VAL_ 1297 RCM_a107_eventIDFsignal 1 "RCM_DAS_IDF_ACTIVE" 0 "RCM_DAS_IDF_NOT_ACTIVE" ;
VAL_ 1297 RCM_a024_eventIDFsignal 1 "RCM_DAS_IDF_ACTIVE" 0 "RCM_DAS_IDF_NOT_ACTIVE" ;
VAL_ 1297 RCM_a047_eventIDFsignal 1 "RCM_DAS_IDF_ACTIVE" 0 "RCM_DAS_IDF_NOT_ACTIVE" ;
VAL_ 1297 RCM_a092_eventIDFsignal 1 "RCM_DAS_IDF_ACTIVE" 0 "RCM_DAS_IDF_NOT_ACTIVE" ;
VAL_ 1297 RCM_a065_eventIDFsignal 1 "RCM_DAS_IDF_ACTIVE" 0 "RCM_DAS_IDF_NOT_ACTIVE" ;
VAL_ 1297 RCM_a021_eventIDFsignal 1 "RCM_DAS_IDF_ACTIVE" 0 "RCM_DAS_IDF_NOT_ACTIVE" ;
VAL_ 1297 RCM_a102_eventIDFsignal 1 "RCM_DAS_IDF_ACTIVE" 0 "RCM_DAS_IDF_NOT_ACTIVE" ;
VAL_ 1297 RCM_a003_eventIDFsignal 1 "RCM_DAS_IDF_ACTIVE" 0 "RCM_DAS_IDF_NOT_ACTIVE" ;
VAL_ 1297 RCM_a038_eventIDFsignal 1 "RCM_DAS_IDF_ACTIVE" 0 "RCM_DAS_IDF_NOT_ACTIVE" ;
VAL_ 1297 RCM_a022_eventIDFsignal 1 "RCM_DAS_IDF_ACTIVE" 0 "RCM_DAS_IDF_NOT_ACTIVE" ;
VAL_ 1297 RCM_a101_eventIDFsignal 1 "RCM_DAS_IDF_ACTIVE" 0 "RCM_DAS_IDF_NOT_ACTIVE" ;
VAL_ 1297 RCM_a118_eventIDFsignal 1 "RCM_DAS_IDF_ACTIVE" 0 "RCM_DAS_IDF_NOT_ACTIVE" ;
VAL_ 1297 RCM_a044_eventIDFsignal 1 "RCM_DAS_IDF_ACTIVE" 0 "RCM_DAS_IDF_NOT_ACTIVE" ;
VAL_ 1297 RCM_a066_eventIDFsignal 1 "RCM_DAS_IDF_ACTIVE" 0 "RCM_DAS_IDF_NOT_ACTIVE" ;
VAL_ 1297 RCM_a000_eventIDFsignal 1 "RCM_DAS_IDF_ACTIVE" 0 "RCM_DAS_IDF_NOT_ACTIVE" ;
VAL_ 1297 RCM_a091_eventIDFsignal 1 "RCM_DAS_IDF_ACTIVE" 0 "RCM_DAS_IDF_NOT_ACTIVE" ;
VAL_ 1297 RCM_a088_eventIDFsignal 1 "RCM_DAS_IDF_ACTIVE" 0 "RCM_DAS_IDF_NOT_ACTIVE" ;
VAL_ 1297 RCM_a019_eventIDFsignal 1 "RCM_DAS_IDF_ACTIVE" 0 "RCM_DAS_IDF_NOT_ACTIVE" ;
VAL_ 1297 RCM_a112_eventDriveOrientation 0 "RCM_LEARNED_LEFT_HAND_DRIVE" 1 "RCM_LEARNED_RIGHT_HAND_DRIVE" ;
VAL_ 1297 RCM_a057_eventDriveOrientation 0 "RCM_LEARNED_LEFT_HAND_DRIVE" 1 "RCM_LEARNED_RIGHT_HAND_DRIVE" ;
VAL_ 1297 RCM_a082_eventDriveOrientation 0 "RCM_LEARNED_LEFT_HAND_DRIVE" 1 "RCM_LEARNED_RIGHT_HAND_DRIVE" ;
VAL_ 1297 RCM_a028_eventDriveOrientation 0 "RCM_LEARNED_LEFT_HAND_DRIVE" 1 "RCM_LEARNED_RIGHT_HAND_DRIVE" ;
VAL_ 1297 RCM_a075_eventDriveOrientation 0 "RCM_LEARNED_LEFT_HAND_DRIVE" 1 "RCM_LEARNED_RIGHT_HAND_DRIVE" ;
VAL_ 1297 RCM_a013_eventDriveOrientation 0 "RCM_LEARNED_LEFT_HAND_DRIVE" 1 "RCM_LEARNED_RIGHT_HAND_DRIVE" ;
VAL_ 1297 RCM_a031_eventDriveOrientation 0 "RCM_LEARNED_LEFT_HAND_DRIVE" 1 "RCM_LEARNED_RIGHT_HAND_DRIVE" ;
VAL_ 1297 RCM_a094_eventDriveOrientation 0 "RCM_LEARNED_LEFT_HAND_DRIVE" 1 "RCM_LEARNED_RIGHT_HAND_DRIVE" ;
VAL_ 1297 RCM_a041_eventDriveOrientation 0 "RCM_LEARNED_LEFT_HAND_DRIVE" 1 "RCM_LEARNED_RIGHT_HAND_DRIVE" ;
VAL_ 1297 RCM_a063_eventDriveOrientation 0 "RCM_LEARNED_LEFT_HAND_DRIVE" 1 "RCM_LEARNED_RIGHT_HAND_DRIVE" ;
VAL_ 1297 RCM_a104_eventDriveOrientation 0 "RCM_LEARNED_LEFT_HAND_DRIVE" 1 "RCM_LEARNED_RIGHT_HAND_DRIVE" ;
VAL_ 1297 RCM_a027_eventDriveOrientation 0 "RCM_LEARNED_LEFT_HAND_DRIVE" 1 "RCM_LEARNED_RIGHT_HAND_DRIVE" ;
VAL_ 1297 RCM_a058_eventDriveOrientation 0 "RCM_LEARNED_LEFT_HAND_DRIVE" 1 "RCM_LEARNED_RIGHT_HAND_DRIVE" ;
VAL_ 1297 RCM_a005_eventDriveOrientation 0 "RCM_LEARNED_LEFT_HAND_DRIVE" 1 "RCM_LEARNED_RIGHT_HAND_DRIVE" ;
VAL_ 1297 RCM_a091_eventDriveOrientation 0 "RCM_LEARNED_LEFT_HAND_DRIVE" 1 "RCM_LEARNED_RIGHT_HAND_DRIVE" ;
VAL_ 1297 RCM_a066_eventDriveOrientation 0 "RCM_LEARNED_LEFT_HAND_DRIVE" 1 "RCM_LEARNED_RIGHT_HAND_DRIVE" ;
VAL_ 1297 RCM_a088_eventDriveOrientation 0 "RCM_LEARNED_LEFT_HAND_DRIVE" 1 "RCM_LEARNED_RIGHT_HAND_DRIVE" ;
VAL_ 1297 RCM_a101_eventDriveOrientation 0 "RCM_LEARNED_LEFT_HAND_DRIVE" 1 "RCM_LEARNED_RIGHT_HAND_DRIVE" ;
VAL_ 1297 RCM_a022_eventDriveOrientation 0 "RCM_LEARNED_LEFT_HAND_DRIVE" 1 "RCM_LEARNED_RIGHT_HAND_DRIVE" ;
VAL_ 1297 RCM_a044_eventDriveOrientation 0 "RCM_LEARNED_LEFT_HAND_DRIVE" 1 "RCM_LEARNED_RIGHT_HAND_DRIVE" ;
VAL_ 1297 RCM_a118_eventDriveOrientation 0 "RCM_LEARNED_LEFT_HAND_DRIVE" 1 "RCM_LEARNED_RIGHT_HAND_DRIVE" ;
VAL_ 1297 RCM_a000_eventDriveOrientation 0 "RCM_LEARNED_LEFT_HAND_DRIVE" 1 "RCM_LEARNED_RIGHT_HAND_DRIVE" ;
VAL_ 1297 RCM_a019_eventDriveOrientation 0 "RCM_LEARNED_LEFT_HAND_DRIVE" 1 "RCM_LEARNED_RIGHT_HAND_DRIVE" ;
VAL_ 1297 RCM_a074_eventDriveOrientation 0 "RCM_LEARNED_LEFT_HAND_DRIVE" 1 "RCM_LEARNED_RIGHT_HAND_DRIVE" ;
VAL_ 1297 RCM_a012_eventDriveOrientation 0 "RCM_LEARNED_LEFT_HAND_DRIVE" 1 "RCM_LEARNED_RIGHT_HAND_DRIVE" ;
VAL_ 1297 RCM_a056_eventDriveOrientation 0 "RCM_LEARNED_LEFT_HAND_DRIVE" 1 "RCM_LEARNED_RIGHT_HAND_DRIVE" ;
VAL_ 1297 RCM_a113_eventDriveOrientation 0 "RCM_LEARNED_LEFT_HAND_DRIVE" 1 "RCM_LEARNED_RIGHT_HAND_DRIVE" ;
VAL_ 1297 RCM_a030_eventDriveOrientation 0 "RCM_LEARNED_LEFT_HAND_DRIVE" 1 "RCM_LEARNED_RIGHT_HAND_DRIVE" ;
VAL_ 1297 RCM_a083_eventDriveOrientation 0 "RCM_LEARNED_LEFT_HAND_DRIVE" 1 "RCM_LEARNED_RIGHT_HAND_DRIVE" ;
VAL_ 1297 RCM_a029_eventDriveOrientation 0 "RCM_LEARNED_LEFT_HAND_DRIVE" 1 "RCM_LEARNED_RIGHT_HAND_DRIVE" ;
VAL_ 1297 RCM_a006_eventDriveOrientation 0 "RCM_LEARNED_LEFT_HAND_DRIVE" 1 "RCM_LEARNED_RIGHT_HAND_DRIVE" ;
VAL_ 1297 RCM_a079_eventDriveOrientation 0 "RCM_LEARNED_LEFT_HAND_DRIVE" 1 "RCM_LEARNED_RIGHT_HAND_DRIVE" ;
VAL_ 1297 RCM_a097_eventDriveOrientation 0 "RCM_LEARNED_LEFT_HAND_DRIVE" 1 "RCM_LEARNED_RIGHT_HAND_DRIVE" ;
VAL_ 1297 RCM_a107_eventDriveOrientation 0 "RCM_LEARNED_LEFT_HAND_DRIVE" 1 "RCM_LEARNED_RIGHT_HAND_DRIVE" ;
VAL_ 1297 RCM_a024_eventDriveOrientation 0 "RCM_LEARNED_LEFT_HAND_DRIVE" 1 "RCM_LEARNED_RIGHT_HAND_DRIVE" ;
VAL_ 1297 RCM_a042_eventDriveOrientation 0 "RCM_LEARNED_LEFT_HAND_DRIVE" 1 "RCM_LEARNED_RIGHT_HAND_DRIVE" ;
VAL_ 1297 RCM_a060_eventDriveOrientation 0 "RCM_LEARNED_LEFT_HAND_DRIVE" 1 "RCM_LEARNED_RIGHT_HAND_DRIVE" ;
VAL_ 1297 RCM_a089_eventDriveOrientation 0 "RCM_LEARNED_LEFT_HAND_DRIVE" 1 "RCM_LEARNED_RIGHT_HAND_DRIVE" ;
VAL_ 1297 RCM_a001_eventDriveOrientation 0 "RCM_LEARNED_LEFT_HAND_DRIVE" 1 "RCM_LEARNED_RIGHT_HAND_DRIVE" ;
VAL_ 1297 RCM_a090_eventDriveOrientation 0 "RCM_LEARNED_LEFT_HAND_DRIVE" 1 "RCM_LEARNED_RIGHT_HAND_DRIVE" ;
VAL_ 1297 RCM_a067_eventDriveOrientation 0 "RCM_LEARNED_LEFT_HAND_DRIVE" 1 "RCM_LEARNED_RIGHT_HAND_DRIVE" ;
VAL_ 1297 RCM_a023_eventDriveOrientation 0 "RCM_LEARNED_LEFT_HAND_DRIVE" 1 "RCM_LEARNED_RIGHT_HAND_DRIVE" ;
VAL_ 1297 RCM_a100_eventDriveOrientation 0 "RCM_LEARNED_LEFT_HAND_DRIVE" 1 "RCM_LEARNED_RIGHT_HAND_DRIVE" ;
VAL_ 1297 RCM_a045_eventDriveOrientation 0 "RCM_LEARNED_LEFT_HAND_DRIVE" 1 "RCM_LEARNED_RIGHT_HAND_DRIVE" ;
VAL_ 1297 RCM_a018_eventDriveOrientation 0 "RCM_LEARNED_LEFT_HAND_DRIVE" 1 "RCM_LEARNED_RIGHT_HAND_DRIVE" ;
VAL_ 1297 RCM_a037_eventDriveOrientation 0 "RCM_LEARNED_LEFT_HAND_DRIVE" 1 "RCM_LEARNED_RIGHT_HAND_DRIVE" ;
VAL_ 1297 RCM_a084_eventDriveOrientation 0 "RCM_LEARNED_LEFT_HAND_DRIVE" 1 "RCM_LEARNED_RIGHT_HAND_DRIVE" ;
VAL_ 1297 RCM_a114_eventDriveOrientation 0 "RCM_LEARNED_LEFT_HAND_DRIVE" 1 "RCM_LEARNED_RIGHT_HAND_DRIVE" ;
VAL_ 1297 RCM_a051_eventDriveOrientation 0 "RCM_LEARNED_LEFT_HAND_DRIVE" 1 "RCM_LEARNED_RIGHT_HAND_DRIVE" ;
VAL_ 1297 RCM_a073_eventDriveOrientation 0 "RCM_LEARNED_LEFT_HAND_DRIVE" 1 "RCM_LEARNED_RIGHT_HAND_DRIVE" ;
VAL_ 1297 RCM_a015_eventDriveOrientation 0 "RCM_LEARNED_LEFT_HAND_DRIVE" 1 "RCM_LEARNED_RIGHT_HAND_DRIVE" ;
VAL_ 1297 RCM_a048_eventDriveOrientation 0 "RCM_LEARNED_LEFT_HAND_DRIVE" 1 "RCM_LEARNED_RIGHT_HAND_DRIVE" ;
VAL_ 1297 RCM_a043_eventDriveOrientation 0 "RCM_LEARNED_LEFT_HAND_DRIVE" 1 "RCM_LEARNED_RIGHT_HAND_DRIVE" ;
VAL_ 1297 RCM_a078_eventDriveOrientation 0 "RCM_LEARNED_LEFT_HAND_DRIVE" 1 "RCM_LEARNED_RIGHT_HAND_DRIVE" ;
VAL_ 1297 RCM_a007_eventDriveOrientation 0 "RCM_LEARNED_LEFT_HAND_DRIVE" 1 "RCM_LEARNED_RIGHT_HAND_DRIVE" ;
VAL_ 1297 RCM_a096_eventDriveOrientation 0 "RCM_LEARNED_LEFT_HAND_DRIVE" 1 "RCM_LEARNED_RIGHT_HAND_DRIVE" ;
VAL_ 1297 RCM_a061_eventDriveOrientation 0 "RCM_LEARNED_LEFT_HAND_DRIVE" 1 "RCM_LEARNED_RIGHT_HAND_DRIVE" ;
VAL_ 1297 RCM_a025_eventDriveOrientation 0 "RCM_LEARNED_LEFT_HAND_DRIVE" 1 "RCM_LEARNED_RIGHT_HAND_DRIVE" ;
VAL_ 1297 RCM_a106_eventDriveOrientation 0 "RCM_LEARNED_LEFT_HAND_DRIVE" 1 "RCM_LEARNED_RIGHT_HAND_DRIVE" ;
VAL_ 1297 RCM_a002_eventDriveOrientation 0 "RCM_LEARNED_LEFT_HAND_DRIVE" 1 "RCM_LEARNED_RIGHT_HAND_DRIVE" ;
VAL_ 1297 RCM_a093_eventDriveOrientation 0 "RCM_LEARNED_LEFT_HAND_DRIVE" 1 "RCM_LEARNED_RIGHT_HAND_DRIVE" ;
VAL_ 1297 RCM_a103_eventDriveOrientation 0 "RCM_LEARNED_LEFT_HAND_DRIVE" 1 "RCM_LEARNED_RIGHT_HAND_DRIVE" ;
VAL_ 1297 RCM_a020_eventDriveOrientation 0 "RCM_LEARNED_LEFT_HAND_DRIVE" 1 "RCM_LEARNED_RIGHT_HAND_DRIVE" ;
VAL_ 1297 RCM_a046_eventDriveOrientation 0 "RCM_LEARNED_LEFT_HAND_DRIVE" 1 "RCM_LEARNED_RIGHT_HAND_DRIVE" ;
VAL_ 1297 RCM_a039_eventDriveOrientation 0 "RCM_LEARNED_LEFT_HAND_DRIVE" 1 "RCM_LEARNED_RIGHT_HAND_DRIVE" ;
VAL_ 1297 RCM_a064_eventDriveOrientation 0 "RCM_LEARNED_LEFT_HAND_DRIVE" 1 "RCM_LEARNED_RIGHT_HAND_DRIVE" ;
VAL_ 1297 RCM_a049_eventDriveOrientation 0 "RCM_LEARNED_LEFT_HAND_DRIVE" 1 "RCM_LEARNED_RIGHT_HAND_DRIVE" ;
VAL_ 1297 RCM_a014_eventDriveOrientation 0 "RCM_LEARNED_LEFT_HAND_DRIVE" 1 "RCM_LEARNED_RIGHT_HAND_DRIVE" ;
VAL_ 1297 RCM_a036_eventDriveOrientation 0 "RCM_LEARNED_LEFT_HAND_DRIVE" 1 "RCM_LEARNED_RIGHT_HAND_DRIVE" ;
VAL_ 1297 RCM_a085_eventDriveOrientation 0 "RCM_LEARNED_LEFT_HAND_DRIVE" 1 "RCM_LEARNED_RIGHT_HAND_DRIVE" ;
VAL_ 1297 RCM_a115_eventDriveOrientation 0 "RCM_LEARNED_LEFT_HAND_DRIVE" 1 "RCM_LEARNED_RIGHT_HAND_DRIVE" ;
VAL_ 1297 RCM_a050_eventDriveOrientation 0 "RCM_LEARNED_LEFT_HAND_DRIVE" 1 "RCM_LEARNED_RIGHT_HAND_DRIVE" ;
VAL_ 1297 RCM_a072_eventDriveOrientation 0 "RCM_LEARNED_LEFT_HAND_DRIVE" 1 "RCM_LEARNED_RIGHT_HAND_DRIVE" ;
VAL_ 1297 RCM_a033_eventDriveOrientation 0 "RCM_LEARNED_LEFT_HAND_DRIVE" 1 "RCM_LEARNED_RIGHT_HAND_DRIVE" ;
VAL_ 1297 RCM_a080_eventDriveOrientation 0 "RCM_LEARNED_LEFT_HAND_DRIVE" 1 "RCM_LEARNED_RIGHT_HAND_DRIVE" ;
VAL_ 1297 RCM_a109_eventDriveOrientation 0 "RCM_LEARNED_LEFT_HAND_DRIVE" 1 "RCM_LEARNED_RIGHT_HAND_DRIVE" ;
VAL_ 1297 RCM_a110_eventDriveOrientation 0 "RCM_LEARNED_LEFT_HAND_DRIVE" 1 "RCM_LEARNED_RIGHT_HAND_DRIVE" ;
VAL_ 1297 RCM_a055_eventDriveOrientation 0 "RCM_LEARNED_LEFT_HAND_DRIVE" 1 "RCM_LEARNED_RIGHT_HAND_DRIVE" ;
VAL_ 1297 RCM_a077_eventDriveOrientation 0 "RCM_LEARNED_LEFT_HAND_DRIVE" 1 "RCM_LEARNED_RIGHT_HAND_DRIVE" ;
VAL_ 1297 RCM_a008_eventDriveOrientation 0 "RCM_LEARNED_LEFT_HAND_DRIVE" 1 "RCM_LEARNED_RIGHT_HAND_DRIVE" ;
VAL_ 1297 RCM_a011_eventDriveOrientation 0 "RCM_LEARNED_LEFT_HAND_DRIVE" 1 "RCM_LEARNED_RIGHT_HAND_DRIVE" ;
VAL_ 1297 RCM_a099_eventDriveOrientation 0 "RCM_LEARNED_LEFT_HAND_DRIVE" 1 "RCM_LEARNED_RIGHT_HAND_DRIVE" ;
VAL_ 1297 RCM_a038_eventDriveOrientation 0 "RCM_LEARNED_LEFT_HAND_DRIVE" 1 "RCM_LEARNED_RIGHT_HAND_DRIVE" ;
VAL_ 1297 RCM_a065_eventDriveOrientation 0 "RCM_LEARNED_LEFT_HAND_DRIVE" 1 "RCM_LEARNED_RIGHT_HAND_DRIVE" ;
VAL_ 1297 RCM_a021_eventDriveOrientation 0 "RCM_LEARNED_LEFT_HAND_DRIVE" 1 "RCM_LEARNED_RIGHT_HAND_DRIVE" ;
VAL_ 1297 RCM_a102_eventDriveOrientation 0 "RCM_LEARNED_LEFT_HAND_DRIVE" 1 "RCM_LEARNED_RIGHT_HAND_DRIVE" ;
VAL_ 1297 RCM_a003_eventDriveOrientation 0 "RCM_LEARNED_LEFT_HAND_DRIVE" 1 "RCM_LEARNED_RIGHT_HAND_DRIVE" ;
VAL_ 1297 RCM_a092_eventDriveOrientation 0 "RCM_LEARNED_LEFT_HAND_DRIVE" 1 "RCM_LEARNED_RIGHT_HAND_DRIVE" ;
VAL_ 1297 RCM_a047_eventDriveOrientation 0 "RCM_LEARNED_LEFT_HAND_DRIVE" 1 "RCM_LEARNED_RIGHT_HAND_DRIVE" ;
VAL_ 1297 RCM_a068_eventDriveOrientation 0 "RCM_LEARNED_LEFT_HAND_DRIVE" 1 "RCM_LEARNED_RIGHT_HAND_DRIVE" ;
VAL_ 1297 RCM_a116_eventDriveOrientation 0 "RCM_LEARNED_LEFT_HAND_DRIVE" 1 "RCM_LEARNED_RIGHT_HAND_DRIVE" ;
VAL_ 1297 RCM_a053_eventDriveOrientation 0 "RCM_LEARNED_LEFT_HAND_DRIVE" 1 "RCM_LEARNED_RIGHT_HAND_DRIVE" ;
VAL_ 1297 RCM_a086_eventDriveOrientation 0 "RCM_LEARNED_LEFT_HAND_DRIVE" 1 "RCM_LEARNED_RIGHT_HAND_DRIVE" ;
VAL_ 1297 RCM_a071_eventDriveOrientation 0 "RCM_LEARNED_LEFT_HAND_DRIVE" 1 "RCM_LEARNED_RIGHT_HAND_DRIVE" ;
VAL_ 1297 RCM_a017_eventDriveOrientation 0 "RCM_LEARNED_LEFT_HAND_DRIVE" 1 "RCM_LEARNED_RIGHT_HAND_DRIVE" ;
VAL_ 1297 RCM_a035_eventDriveOrientation 0 "RCM_LEARNED_LEFT_HAND_DRIVE" 1 "RCM_LEARNED_RIGHT_HAND_DRIVE" ;
VAL_ 1297 RCM_a081_eventDriveOrientation 0 "RCM_LEARNED_LEFT_HAND_DRIVE" 1 "RCM_LEARNED_RIGHT_HAND_DRIVE" ;
VAL_ 1297 RCM_a108_eventDriveOrientation 0 "RCM_LEARNED_LEFT_HAND_DRIVE" 1 "RCM_LEARNED_RIGHT_HAND_DRIVE" ;
VAL_ 1297 RCM_a009_eventDriveOrientation 0 "RCM_LEARNED_LEFT_HAND_DRIVE" 1 "RCM_LEARNED_RIGHT_HAND_DRIVE" ;
VAL_ 1297 RCM_a076_eventDriveOrientation 0 "RCM_LEARNED_LEFT_HAND_DRIVE" 1 "RCM_LEARNED_RIGHT_HAND_DRIVE" ;
VAL_ 1297 RCM_a010_eventDriveOrientation 0 "RCM_LEARNED_LEFT_HAND_DRIVE" 1 "RCM_LEARNED_RIGHT_HAND_DRIVE" ;
VAL_ 1297 RCM_a098_eventDriveOrientation 0 "RCM_LEARNED_LEFT_HAND_DRIVE" 1 "RCM_LEARNED_RIGHT_HAND_DRIVE" ;
VAL_ 1297 RCM_a111_eventDriveOrientation 0 "RCM_LEARNED_LEFT_HAND_DRIVE" 1 "RCM_LEARNED_RIGHT_HAND_DRIVE" ;
VAL_ 1297 RCM_a054_eventDriveOrientation 0 "RCM_LEARNED_LEFT_HAND_DRIVE" 1 "RCM_LEARNED_RIGHT_HAND_DRIVE" ;
VAL_ 1297 RCM_a032_eventDriveOrientation 0 "RCM_LEARNED_LEFT_HAND_DRIVE" 1 "RCM_LEARNED_RIGHT_HAND_DRIVE" ;
VAL_ 1297 RCM_a095_eventDriveOrientation 0 "RCM_LEARNED_LEFT_HAND_DRIVE" 1 "RCM_LEARNED_RIGHT_HAND_DRIVE" ;
VAL_ 1297 RCM_a062_eventDriveOrientation 0 "RCM_LEARNED_LEFT_HAND_DRIVE" 1 "RCM_LEARNED_RIGHT_HAND_DRIVE" ;
VAL_ 1297 RCM_a105_eventDriveOrientation 0 "RCM_LEARNED_LEFT_HAND_DRIVE" 1 "RCM_LEARNED_RIGHT_HAND_DRIVE" ;
VAL_ 1297 RCM_a026_eventDriveOrientation 0 "RCM_LEARNED_LEFT_HAND_DRIVE" 1 "RCM_LEARNED_RIGHT_HAND_DRIVE" ;
VAL_ 1297 RCM_a040_eventDriveOrientation 0 "RCM_LEARNED_LEFT_HAND_DRIVE" 1 "RCM_LEARNED_RIGHT_HAND_DRIVE" ;
VAL_ 1297 RCM_a059_eventDriveOrientation 0 "RCM_LEARNED_LEFT_HAND_DRIVE" 1 "RCM_LEARNED_RIGHT_HAND_DRIVE" ;
VAL_ 1297 RCM_a004_eventDriveOrientation 0 "RCM_LEARNED_LEFT_HAND_DRIVE" 1 "RCM_LEARNED_RIGHT_HAND_DRIVE" ;
VAL_ 1297 RCM_a117_eventDriveOrientation 0 "RCM_LEARNED_LEFT_HAND_DRIVE" 1 "RCM_LEARNED_RIGHT_HAND_DRIVE" ;
VAL_ 1297 RCM_a052_eventDriveOrientation 0 "RCM_LEARNED_LEFT_HAND_DRIVE" 1 "RCM_LEARNED_RIGHT_HAND_DRIVE" ;
VAL_ 1297 RCM_a070_eventDriveOrientation 0 "RCM_LEARNED_LEFT_HAND_DRIVE" 1 "RCM_LEARNED_RIGHT_HAND_DRIVE" ;
VAL_ 1297 RCM_a016_eventDriveOrientation 0 "RCM_LEARNED_LEFT_HAND_DRIVE" 1 "RCM_LEARNED_RIGHT_HAND_DRIVE" ;
VAL_ 1297 RCM_a034_eventDriveOrientation 0 "RCM_LEARNED_LEFT_HAND_DRIVE" 1 "RCM_LEARNED_RIGHT_HAND_DRIVE" ;
VAL_ 1297 RCM_a069_eventDriveOrientation 0 "RCM_LEARNED_LEFT_HAND_DRIVE" 1 "RCM_LEARNED_RIGHT_HAND_DRIVE" ;
VAL_ 1297 RCM_a087_eventDriveOrientation 0 "RCM_LEARNED_LEFT_HAND_DRIVE" 1 "RCM_LEARNED_RIGHT_HAND_DRIVE" ;
VAL_ 1297 RCM_a017_eventDiagEnabled 1 "RCM_DIAGNOSTICS_ENABLED" 0 "RCM_DIAGNOSTICS_DISABLED" ;
VAL_ 1297 RCM_a035_eventDiagEnabled 1 "RCM_DIAGNOSTICS_ENABLED" 0 "RCM_DIAGNOSTICS_DISABLED" ;
VAL_ 1297 RCM_a071_eventDiagEnabled 1 "RCM_DIAGNOSTICS_ENABLED" 0 "RCM_DIAGNOSTICS_DISABLED" ;
VAL_ 1297 RCM_a086_eventDiagEnabled 1 "RCM_DIAGNOSTICS_ENABLED" 0 "RCM_DIAGNOSTICS_DISABLED" ;
VAL_ 1297 RCM_a053_eventDiagEnabled 1 "RCM_DIAGNOSTICS_ENABLED" 0 "RCM_DIAGNOSTICS_DISABLED" ;
VAL_ 1297 RCM_a116_eventDiagEnabled 1 "RCM_DIAGNOSTICS_ENABLED" 0 "RCM_DIAGNOSTICS_DISABLED" ;
VAL_ 1297 RCM_a068_eventDiagEnabled 1 "RCM_DIAGNOSTICS_ENABLED" 0 "RCM_DIAGNOSTICS_DISABLED" ;
VAL_ 1297 RCM_a010_eventDiagEnabled 1 "RCM_DIAGNOSTICS_ENABLED" 0 "RCM_DIAGNOSTICS_DISABLED" ;
VAL_ 1297 RCM_a081_eventDiagEnabled 1 "RCM_DIAGNOSTICS_ENABLED" 0 "RCM_DIAGNOSTICS_DISABLED" ;
VAL_ 1297 RCM_a111_eventDiagEnabled 1 "RCM_DIAGNOSTICS_ENABLED" 0 "RCM_DIAGNOSTICS_DISABLED" ;
VAL_ 1297 RCM_a054_eventDiagEnabled 1 "RCM_DIAGNOSTICS_ENABLED" 0 "RCM_DIAGNOSTICS_DISABLED" ;
VAL_ 1297 RCM_a032_eventDiagEnabled 1 "RCM_DIAGNOSTICS_ENABLED" 0 "RCM_DIAGNOSTICS_DISABLED" ;
VAL_ 1297 RCM_a108_eventDiagEnabled 1 "RCM_DIAGNOSTICS_ENABLED" 0 "RCM_DIAGNOSTICS_DISABLED" ;
VAL_ 1297 RCM_a098_eventDiagEnabled 1 "RCM_DIAGNOSTICS_ENABLED" 0 "RCM_DIAGNOSTICS_DISABLED" ;
VAL_ 1297 RCM_a076_eventDiagEnabled 1 "RCM_DIAGNOSTICS_ENABLED" 0 "RCM_DIAGNOSTICS_DISABLED" ;
VAL_ 1297 RCM_a009_eventDiagEnabled 1 "RCM_DIAGNOSTICS_ENABLED" 0 "RCM_DIAGNOSTICS_DISABLED" ;
VAL_ 1297 RCM_a004_eventDiagEnabled 1 "RCM_DIAGNOSTICS_ENABLED" 0 "RCM_DIAGNOSTICS_DISABLED" ;
VAL_ 1297 RCM_a062_eventDiagEnabled 1 "RCM_DIAGNOSTICS_ENABLED" 0 "RCM_DIAGNOSTICS_DISABLED" ;
VAL_ 1297 RCM_a040_eventDiagEnabled 1 "RCM_DIAGNOSTICS_ENABLED" 0 "RCM_DIAGNOSTICS_DISABLED" ;
VAL_ 1297 RCM_a095_eventDiagEnabled 1 "RCM_DIAGNOSTICS_ENABLED" 0 "RCM_DIAGNOSTICS_DISABLED" ;
VAL_ 1297 RCM_a059_eventDiagEnabled 1 "RCM_DIAGNOSTICS_ENABLED" 0 "RCM_DIAGNOSTICS_DISABLED" ;
VAL_ 1297 RCM_a026_eventDiagEnabled 1 "RCM_DIAGNOSTICS_ENABLED" 0 "RCM_DIAGNOSTICS_DISABLED" ;
VAL_ 1297 RCM_a105_eventDiagEnabled 1 "RCM_DIAGNOSTICS_ENABLED" 0 "RCM_DIAGNOSTICS_DISABLED" ;
VAL_ 1297 RCM_a043_eventDiagEnabled 1 "RCM_DIAGNOSTICS_ENABLED" 0 "RCM_DIAGNOSTICS_DISABLED" ;
VAL_ 1297 RCM_a096_eventDiagEnabled 1 "RCM_DIAGNOSTICS_ENABLED" 0 "RCM_DIAGNOSTICS_DISABLED" ;
VAL_ 1297 RCM_a025_eventDiagEnabled 1 "RCM_DIAGNOSTICS_ENABLED" 0 "RCM_DIAGNOSTICS_DISABLED" ;
VAL_ 1297 RCM_a106_eventDiagEnabled 1 "RCM_DIAGNOSTICS_ENABLED" 0 "RCM_DIAGNOSTICS_DISABLED" ;
VAL_ 1297 RCM_a078_eventDiagEnabled 1 "RCM_DIAGNOSTICS_ENABLED" 0 "RCM_DIAGNOSTICS_DISABLED" ;
VAL_ 1297 RCM_a007_eventDiagEnabled 1 "RCM_DIAGNOSTICS_ENABLED" 0 "RCM_DIAGNOSTICS_DISABLED" ;
VAL_ 1297 RCM_a061_eventDiagEnabled 1 "RCM_DIAGNOSTICS_ENABLED" 0 "RCM_DIAGNOSTICS_DISABLED" ;
VAL_ 1297 RCM_a039_eventDiagEnabled 1 "RCM_DIAGNOSTICS_ENABLED" 0 "RCM_DIAGNOSTICS_DISABLED" ;
VAL_ 1297 RCM_a103_eventDiagEnabled 1 "RCM_DIAGNOSTICS_ENABLED" 0 "RCM_DIAGNOSTICS_DISABLED" ;
VAL_ 1297 RCM_a020_eventDiagEnabled 1 "RCM_DIAGNOSTICS_ENABLED" 0 "RCM_DIAGNOSTICS_DISABLED" ;
VAL_ 1297 RCM_a002_eventDiagEnabled 1 "RCM_DIAGNOSTICS_ENABLED" 0 "RCM_DIAGNOSTICS_DISABLED" ;
VAL_ 1297 RCM_a046_eventDiagEnabled 1 "RCM_DIAGNOSTICS_ENABLED" 0 "RCM_DIAGNOSTICS_DISABLED" ;
VAL_ 1297 RCM_a093_eventDiagEnabled 1 "RCM_DIAGNOSTICS_ENABLED" 0 "RCM_DIAGNOSTICS_DISABLED" ;
VAL_ 1297 RCM_a064_eventDiagEnabled 1 "RCM_DIAGNOSTICS_ENABLED" 0 "RCM_DIAGNOSTICS_DISABLED" ;
VAL_ 1297 RCM_a115_eventDiagEnabled 1 "RCM_DIAGNOSTICS_ENABLED" 0 "RCM_DIAGNOSTICS_DISABLED" ;
VAL_ 1297 RCM_a050_eventDiagEnabled 1 "RCM_DIAGNOSTICS_ENABLED" 0 "RCM_DIAGNOSTICS_DISABLED" ;
VAL_ 1297 RCM_a036_eventDiagEnabled 1 "RCM_DIAGNOSTICS_ENABLED" 0 "RCM_DIAGNOSTICS_DISABLED" ;
VAL_ 1297 RCM_a072_eventDiagEnabled 1 "RCM_DIAGNOSTICS_ENABLED" 0 "RCM_DIAGNOSTICS_DISABLED" ;
VAL_ 1297 RCM_a049_eventDiagEnabled 1 "RCM_DIAGNOSTICS_ENABLED" 0 "RCM_DIAGNOSTICS_DISABLED" ;
VAL_ 1297 RCM_a014_eventDiagEnabled 1 "RCM_DIAGNOSTICS_ENABLED" 0 "RCM_DIAGNOSTICS_DISABLED" ;
VAL_ 1297 RCM_a085_eventDiagEnabled 1 "RCM_DIAGNOSTICS_ENABLED" 0 "RCM_DIAGNOSTICS_DISABLED" ;
VAL_ 1297 RCM_a109_eventDiagEnabled 1 "RCM_DIAGNOSTICS_ENABLED" 0 "RCM_DIAGNOSTICS_DISABLED" ;
VAL_ 1297 RCM_a077_eventDiagEnabled 1 "RCM_DIAGNOSTICS_ENABLED" 0 "RCM_DIAGNOSTICS_DISABLED" ;
VAL_ 1297 RCM_a008_eventDiagEnabled 1 "RCM_DIAGNOSTICS_ENABLED" 0 "RCM_DIAGNOSTICS_DISABLED" ;
VAL_ 1297 RCM_a080_eventDiagEnabled 1 "RCM_DIAGNOSTICS_ENABLED" 0 "RCM_DIAGNOSTICS_DISABLED" ;
VAL_ 1297 RCM_a099_eventDiagEnabled 1 "RCM_DIAGNOSTICS_ENABLED" 0 "RCM_DIAGNOSTICS_DISABLED" ;
VAL_ 1297 RCM_a011_eventDiagEnabled 1 "RCM_DIAGNOSTICS_ENABLED" 0 "RCM_DIAGNOSTICS_DISABLED" ;
VAL_ 1297 RCM_a110_eventDiagEnabled 1 "RCM_DIAGNOSTICS_ENABLED" 0 "RCM_DIAGNOSTICS_DISABLED" ;
VAL_ 1297 RCM_a055_eventDiagEnabled 1 "RCM_DIAGNOSTICS_ENABLED" 0 "RCM_DIAGNOSTICS_DISABLED" ;
VAL_ 1297 RCM_a033_eventDiagEnabled 1 "RCM_DIAGNOSTICS_ENABLED" 0 "RCM_DIAGNOSTICS_DISABLED" ;
VAL_ 1297 RCM_a030_eventDiagEnabled 1 "RCM_DIAGNOSTICS_ENABLED" 0 "RCM_DIAGNOSTICS_DISABLED" ;
VAL_ 1297 RCM_a029_eventDiagEnabled 1 "RCM_DIAGNOSTICS_ENABLED" 0 "RCM_DIAGNOSTICS_DISABLED" ;
VAL_ 1297 RCM_a056_eventDiagEnabled 1 "RCM_DIAGNOSTICS_ENABLED" 0 "RCM_DIAGNOSTICS_DISABLED" ;
VAL_ 1297 RCM_a113_eventDiagEnabled 1 "RCM_DIAGNOSTICS_ENABLED" 0 "RCM_DIAGNOSTICS_DISABLED" ;
VAL_ 1297 RCM_a074_eventDiagEnabled 1 "RCM_DIAGNOSTICS_ENABLED" 0 "RCM_DIAGNOSTICS_DISABLED" ;
VAL_ 1297 RCM_a012_eventDiagEnabled 1 "RCM_DIAGNOSTICS_ENABLED" 0 "RCM_DIAGNOSTICS_DISABLED" ;
VAL_ 1297 RCM_a083_eventDiagEnabled 1 "RCM_DIAGNOSTICS_ENABLED" 0 "RCM_DIAGNOSTICS_DISABLED" ;
VAL_ 1297 RCM_a097_eventDiagEnabled 1 "RCM_DIAGNOSTICS_ENABLED" 0 "RCM_DIAGNOSTICS_DISABLED" ;
VAL_ 1297 RCM_a024_eventDiagEnabled 1 "RCM_DIAGNOSTICS_ENABLED" 0 "RCM_DIAGNOSTICS_DISABLED" ;
VAL_ 1297 RCM_a107_eventDiagEnabled 1 "RCM_DIAGNOSTICS_ENABLED" 0 "RCM_DIAGNOSTICS_DISABLED" ;
VAL_ 1297 RCM_a006_eventDiagEnabled 1 "RCM_DIAGNOSTICS_ENABLED" 0 "RCM_DIAGNOSTICS_DISABLED" ;
VAL_ 1297 RCM_a079_eventDiagEnabled 1 "RCM_DIAGNOSTICS_ENABLED" 0 "RCM_DIAGNOSTICS_DISABLED" ;
VAL_ 1297 RCM_a060_eventDiagEnabled 1 "RCM_DIAGNOSTICS_ENABLED" 0 "RCM_DIAGNOSTICS_DISABLED" ;
VAL_ 1297 RCM_a042_eventDiagEnabled 1 "RCM_DIAGNOSTICS_ENABLED" 0 "RCM_DIAGNOSTICS_DISABLED" ;
VAL_ 1297 RCM_a045_eventDiagEnabled 1 "RCM_DIAGNOSTICS_ENABLED" 0 "RCM_DIAGNOSTICS_DISABLED" ;
VAL_ 1297 RCM_a018_eventDiagEnabled 1 "RCM_DIAGNOSTICS_ENABLED" 0 "RCM_DIAGNOSTICS_DISABLED" ;
VAL_ 1297 RCM_a090_eventDiagEnabled 1 "RCM_DIAGNOSTICS_ENABLED" 0 "RCM_DIAGNOSTICS_DISABLED" ;
VAL_ 1297 RCM_a023_eventDiagEnabled 1 "RCM_DIAGNOSTICS_ENABLED" 0 "RCM_DIAGNOSTICS_DISABLED" ;
VAL_ 1297 RCM_a100_eventDiagEnabled 1 "RCM_DIAGNOSTICS_ENABLED" 0 "RCM_DIAGNOSTICS_DISABLED" ;
VAL_ 1297 RCM_a001_eventDiagEnabled 1 "RCM_DIAGNOSTICS_ENABLED" 0 "RCM_DIAGNOSTICS_DISABLED" ;
VAL_ 1297 RCM_a089_eventDiagEnabled 1 "RCM_DIAGNOSTICS_ENABLED" 0 "RCM_DIAGNOSTICS_DISABLED" ;
VAL_ 1297 RCM_a067_eventDiagEnabled 1 "RCM_DIAGNOSTICS_ENABLED" 0 "RCM_DIAGNOSTICS_DISABLED" ;
VAL_ 1297 RCM_a073_eventDiagEnabled 1 "RCM_DIAGNOSTICS_ENABLED" 0 "RCM_DIAGNOSTICS_DISABLED" ;
VAL_ 1297 RCM_a015_eventDiagEnabled 1 "RCM_DIAGNOSTICS_ENABLED" 0 "RCM_DIAGNOSTICS_DISABLED" ;
VAL_ 1297 RCM_a084_eventDiagEnabled 1 "RCM_DIAGNOSTICS_ENABLED" 0 "RCM_DIAGNOSTICS_DISABLED" ;
VAL_ 1297 RCM_a037_eventDiagEnabled 1 "RCM_DIAGNOSTICS_ENABLED" 0 "RCM_DIAGNOSTICS_DISABLED" ;
VAL_ 1297 RCM_a048_eventDiagEnabled 1 "RCM_DIAGNOSTICS_ENABLED" 0 "RCM_DIAGNOSTICS_DISABLED" ;
VAL_ 1297 RCM_a051_eventDiagEnabled 1 "RCM_DIAGNOSTICS_ENABLED" 0 "RCM_DIAGNOSTICS_DISABLED" ;
VAL_ 1297 RCM_a114_eventDiagEnabled 1 "RCM_DIAGNOSTICS_ENABLED" 0 "RCM_DIAGNOSTICS_DISABLED" ;
VAL_ 1297 RCM_a117_eventDiagEnabled 1 "RCM_DIAGNOSTICS_ENABLED" 0 "RCM_DIAGNOSTICS_DISABLED" ;
VAL_ 1297 RCM_a052_eventDiagEnabled 1 "RCM_DIAGNOSTICS_ENABLED" 0 "RCM_DIAGNOSTICS_DISABLED" ;
VAL_ 1297 RCM_a034_eventDiagEnabled 1 "RCM_DIAGNOSTICS_ENABLED" 0 "RCM_DIAGNOSTICS_DISABLED" ;
VAL_ 1297 RCM_a070_eventDiagEnabled 1 "RCM_DIAGNOSTICS_ENABLED" 0 "RCM_DIAGNOSTICS_DISABLED" ;
VAL_ 1297 RCM_a069_eventDiagEnabled 1 "RCM_DIAGNOSTICS_ENABLED" 0 "RCM_DIAGNOSTICS_DISABLED" ;
VAL_ 1297 RCM_a087_eventDiagEnabled 1 "RCM_DIAGNOSTICS_ENABLED" 0 "RCM_DIAGNOSTICS_DISABLED" ;
VAL_ 1297 RCM_a016_eventDiagEnabled 1 "RCM_DIAGNOSTICS_ENABLED" 0 "RCM_DIAGNOSTICS_DISABLED" ;
VAL_ 1297 RCM_a082_eventDiagEnabled 1 "RCM_DIAGNOSTICS_ENABLED" 0 "RCM_DIAGNOSTICS_DISABLED" ;
VAL_ 1297 RCM_a031_eventDiagEnabled 1 "RCM_DIAGNOSTICS_ENABLED" 0 "RCM_DIAGNOSTICS_DISABLED" ;
VAL_ 1297 RCM_a013_eventDiagEnabled 1 "RCM_DIAGNOSTICS_ENABLED" 0 "RCM_DIAGNOSTICS_DISABLED" ;
VAL_ 1297 RCM_a057_eventDiagEnabled 1 "RCM_DIAGNOSTICS_ENABLED" 0 "RCM_DIAGNOSTICS_DISABLED" ;
VAL_ 1297 RCM_a112_eventDiagEnabled 1 "RCM_DIAGNOSTICS_ENABLED" 0 "RCM_DIAGNOSTICS_DISABLED" ;
VAL_ 1297 RCM_a028_eventDiagEnabled 1 "RCM_DIAGNOSTICS_ENABLED" 0 "RCM_DIAGNOSTICS_DISABLED" ;
VAL_ 1297 RCM_a075_eventDiagEnabled 1 "RCM_DIAGNOSTICS_ENABLED" 0 "RCM_DIAGNOSTICS_DISABLED" ;
VAL_ 1297 RCM_a041_eventDiagEnabled 1 "RCM_DIAGNOSTICS_ENABLED" 0 "RCM_DIAGNOSTICS_DISABLED" ;
VAL_ 1297 RCM_a058_eventDiagEnabled 1 "RCM_DIAGNOSTICS_ENABLED" 0 "RCM_DIAGNOSTICS_DISABLED" ;
VAL_ 1297 RCM_a094_eventDiagEnabled 1 "RCM_DIAGNOSTICS_ENABLED" 0 "RCM_DIAGNOSTICS_DISABLED" ;
VAL_ 1297 RCM_a104_eventDiagEnabled 1 "RCM_DIAGNOSTICS_ENABLED" 0 "RCM_DIAGNOSTICS_DISABLED" ;
VAL_ 1297 RCM_a027_eventDiagEnabled 1 "RCM_DIAGNOSTICS_ENABLED" 0 "RCM_DIAGNOSTICS_DISABLED" ;
VAL_ 1297 RCM_a063_eventDiagEnabled 1 "RCM_DIAGNOSTICS_ENABLED" 0 "RCM_DIAGNOSTICS_DISABLED" ;
VAL_ 1297 RCM_a005_eventDiagEnabled 1 "RCM_DIAGNOSTICS_ENABLED" 0 "RCM_DIAGNOSTICS_DISABLED" ;
VAL_ 1297 RCM_a044_eventDiagEnabled 1 "RCM_DIAGNOSTICS_ENABLED" 0 "RCM_DIAGNOSTICS_DISABLED" ;
VAL_ 1297 RCM_a118_eventDiagEnabled 1 "RCM_DIAGNOSTICS_ENABLED" 0 "RCM_DIAGNOSTICS_DISABLED" ;
VAL_ 1297 RCM_a091_eventDiagEnabled 1 "RCM_DIAGNOSTICS_ENABLED" 0 "RCM_DIAGNOSTICS_DISABLED" ;
VAL_ 1297 RCM_a000_eventDiagEnabled 1 "RCM_DIAGNOSTICS_ENABLED" 0 "RCM_DIAGNOSTICS_DISABLED" ;
VAL_ 1297 RCM_a066_eventDiagEnabled 1 "RCM_DIAGNOSTICS_ENABLED" 0 "RCM_DIAGNOSTICS_DISABLED" ;
VAL_ 1297 RCM_a019_eventDiagEnabled 1 "RCM_DIAGNOSTICS_ENABLED" 0 "RCM_DIAGNOSTICS_DISABLED" ;
VAL_ 1297 RCM_a088_eventDiagEnabled 1 "RCM_DIAGNOSTICS_ENABLED" 0 "RCM_DIAGNOSTICS_DISABLED" ;
VAL_ 1297 RCM_a101_eventDiagEnabled 1 "RCM_DIAGNOSTICS_ENABLED" 0 "RCM_DIAGNOSTICS_DISABLED" ;
VAL_ 1297 RCM_a022_eventDiagEnabled 1 "RCM_DIAGNOSTICS_ENABLED" 0 "RCM_DIAGNOSTICS_DISABLED" ;
VAL_ 1297 RCM_a065_eventDiagEnabled 1 "RCM_DIAGNOSTICS_ENABLED" 0 "RCM_DIAGNOSTICS_DISABLED" ;
VAL_ 1297 RCM_a038_eventDiagEnabled 1 "RCM_DIAGNOSTICS_ENABLED" 0 "RCM_DIAGNOSTICS_DISABLED" ;
VAL_ 1297 RCM_a021_eventDiagEnabled 1 "RCM_DIAGNOSTICS_ENABLED" 0 "RCM_DIAGNOSTICS_DISABLED" ;
VAL_ 1297 RCM_a102_eventDiagEnabled 1 "RCM_DIAGNOSTICS_ENABLED" 0 "RCM_DIAGNOSTICS_DISABLED" ;
VAL_ 1297 RCM_a003_eventDiagEnabled 1 "RCM_DIAGNOSTICS_ENABLED" 0 "RCM_DIAGNOSTICS_DISABLED" ;
VAL_ 1297 RCM_a047_eventDiagEnabled 1 "RCM_DIAGNOSTICS_ENABLED" 0 "RCM_DIAGNOSTICS_DISABLED" ;
VAL_ 1297 RCM_a092_eventDiagEnabled 1 "RCM_DIAGNOSTICS_ENABLED" 0 "RCM_DIAGNOSTICS_DISABLED" ;
VAL_ 1297 RCM_a025_eventFactoryMode 0 "RCM_FACTORY_MODE_DISABLED" 1 "RCM_FACTORY_MODE_ENABLED" ;
VAL_ 1297 RCM_a106_eventFactoryMode 0 "RCM_FACTORY_MODE_DISABLED" 1 "RCM_FACTORY_MODE_ENABLED" ;
VAL_ 1297 RCM_a096_eventFactoryMode 0 "RCM_FACTORY_MODE_DISABLED" 1 "RCM_FACTORY_MODE_ENABLED" ;
VAL_ 1297 RCM_a007_eventFactoryMode 0 "RCM_FACTORY_MODE_DISABLED" 1 "RCM_FACTORY_MODE_ENABLED" ;
VAL_ 1297 RCM_a078_eventFactoryMode 0 "RCM_FACTORY_MODE_DISABLED" 1 "RCM_FACTORY_MODE_ENABLED" ;
VAL_ 1297 RCM_a061_eventFactoryMode 0 "RCM_FACTORY_MODE_DISABLED" 1 "RCM_FACTORY_MODE_ENABLED" ;
VAL_ 1297 RCM_a043_eventFactoryMode 0 "RCM_FACTORY_MODE_DISABLED" 1 "RCM_FACTORY_MODE_ENABLED" ;
VAL_ 1297 RCM_a000_eventFactoryMode 0 "RCM_FACTORY_MODE_DISABLED" 1 "RCM_FACTORY_MODE_ENABLED" ;
VAL_ 1297 RCM_a019_eventFactoryMode 0 "RCM_FACTORY_MODE_DISABLED" 1 "RCM_FACTORY_MODE_ENABLED" ;
VAL_ 1297 RCM_a044_eventFactoryMode 0 "RCM_FACTORY_MODE_DISABLED" 1 "RCM_FACTORY_MODE_ENABLED" ;
VAL_ 1297 RCM_a118_eventFactoryMode 0 "RCM_FACTORY_MODE_DISABLED" 1 "RCM_FACTORY_MODE_ENABLED" ;
VAL_ 1297 RCM_a088_eventFactoryMode 0 "RCM_FACTORY_MODE_DISABLED" 1 "RCM_FACTORY_MODE_ENABLED" ;
VAL_ 1297 RCM_a022_eventFactoryMode 0 "RCM_FACTORY_MODE_DISABLED" 1 "RCM_FACTORY_MODE_ENABLED" ;
VAL_ 1297 RCM_a101_eventFactoryMode 0 "RCM_FACTORY_MODE_DISABLED" 1 "RCM_FACTORY_MODE_ENABLED" ;
VAL_ 1297 RCM_a091_eventFactoryMode 0 "RCM_FACTORY_MODE_DISABLED" 1 "RCM_FACTORY_MODE_ENABLED" ;
VAL_ 1297 RCM_a066_eventFactoryMode 0 "RCM_FACTORY_MODE_DISABLED" 1 "RCM_FACTORY_MODE_ENABLED" ;
VAL_ 1297 RCM_a085_eventFactoryMode 0 "RCM_FACTORY_MODE_DISABLED" 1 "RCM_FACTORY_MODE_ENABLED" ;
VAL_ 1297 RCM_a036_eventFactoryMode 0 "RCM_FACTORY_MODE_DISABLED" 1 "RCM_FACTORY_MODE_ENABLED" ;
VAL_ 1297 RCM_a049_eventFactoryMode 0 "RCM_FACTORY_MODE_DISABLED" 1 "RCM_FACTORY_MODE_ENABLED" ;
VAL_ 1297 RCM_a050_eventFactoryMode 0 "RCM_FACTORY_MODE_DISABLED" 1 "RCM_FACTORY_MODE_ENABLED" ;
VAL_ 1297 RCM_a115_eventFactoryMode 0 "RCM_FACTORY_MODE_DISABLED" 1 "RCM_FACTORY_MODE_ENABLED" ;
VAL_ 1297 RCM_a072_eventFactoryMode 0 "RCM_FACTORY_MODE_DISABLED" 1 "RCM_FACTORY_MODE_ENABLED" ;
VAL_ 1297 RCM_a014_eventFactoryMode 0 "RCM_FACTORY_MODE_DISABLED" 1 "RCM_FACTORY_MODE_ENABLED" ;
VAL_ 1297 RCM_a086_eventFactoryMode 0 "RCM_FACTORY_MODE_DISABLED" 1 "RCM_FACTORY_MODE_ENABLED" ;
VAL_ 1297 RCM_a068_eventFactoryMode 0 "RCM_FACTORY_MODE_DISABLED" 1 "RCM_FACTORY_MODE_ENABLED" ;
VAL_ 1297 RCM_a035_eventFactoryMode 0 "RCM_FACTORY_MODE_DISABLED" 1 "RCM_FACTORY_MODE_ENABLED" ;
VAL_ 1297 RCM_a071_eventFactoryMode 0 "RCM_FACTORY_MODE_DISABLED" 1 "RCM_FACTORY_MODE_ENABLED" ;
VAL_ 1297 RCM_a017_eventFactoryMode 0 "RCM_FACTORY_MODE_DISABLED" 1 "RCM_FACTORY_MODE_ENABLED" ;
VAL_ 1297 RCM_a116_eventFactoryMode 0 "RCM_FACTORY_MODE_DISABLED" 1 "RCM_FACTORY_MODE_ENABLED" ;
VAL_ 1297 RCM_a053_eventFactoryMode 0 "RCM_FACTORY_MODE_DISABLED" 1 "RCM_FACTORY_MODE_ENABLED" ;
VAL_ 1297 RCM_a074_eventFactoryMode 0 "RCM_FACTORY_MODE_DISABLED" 1 "RCM_FACTORY_MODE_ENABLED" ;
VAL_ 1297 RCM_a012_eventFactoryMode 0 "RCM_FACTORY_MODE_DISABLED" 1 "RCM_FACTORY_MODE_ENABLED" ;
VAL_ 1297 RCM_a056_eventFactoryMode 0 "RCM_FACTORY_MODE_DISABLED" 1 "RCM_FACTORY_MODE_ENABLED" ;
VAL_ 1297 RCM_a113_eventFactoryMode 0 "RCM_FACTORY_MODE_DISABLED" 1 "RCM_FACTORY_MODE_ENABLED" ;
VAL_ 1297 RCM_a083_eventFactoryMode 0 "RCM_FACTORY_MODE_DISABLED" 1 "RCM_FACTORY_MODE_ENABLED" ;
VAL_ 1297 RCM_a029_eventFactoryMode 0 "RCM_FACTORY_MODE_DISABLED" 1 "RCM_FACTORY_MODE_ENABLED" ;
VAL_ 1297 RCM_a030_eventFactoryMode 0 "RCM_FACTORY_MODE_DISABLED" 1 "RCM_FACTORY_MODE_ENABLED" ;
VAL_ 1297 RCM_a004_eventFactoryMode 0 "RCM_FACTORY_MODE_DISABLED" 1 "RCM_FACTORY_MODE_ENABLED" ;
VAL_ 1297 RCM_a040_eventFactoryMode 0 "RCM_FACTORY_MODE_DISABLED" 1 "RCM_FACTORY_MODE_ENABLED" ;
VAL_ 1297 RCM_a059_eventFactoryMode 0 "RCM_FACTORY_MODE_DISABLED" 1 "RCM_FACTORY_MODE_ENABLED" ;
VAL_ 1297 RCM_a105_eventFactoryMode 0 "RCM_FACTORY_MODE_DISABLED" 1 "RCM_FACTORY_MODE_ENABLED" ;
VAL_ 1297 RCM_a026_eventFactoryMode 0 "RCM_FACTORY_MODE_DISABLED" 1 "RCM_FACTORY_MODE_ENABLED" ;
VAL_ 1297 RCM_a095_eventFactoryMode 0 "RCM_FACTORY_MODE_DISABLED" 1 "RCM_FACTORY_MODE_ENABLED" ;
VAL_ 1297 RCM_a062_eventFactoryMode 0 "RCM_FACTORY_MODE_DISABLED" 1 "RCM_FACTORY_MODE_ENABLED" ;
VAL_ 1297 RCM_a045_eventFactoryMode 0 "RCM_FACTORY_MODE_DISABLED" 1 "RCM_FACTORY_MODE_ENABLED" ;
VAL_ 1297 RCM_a089_eventFactoryMode 0 "RCM_FACTORY_MODE_DISABLED" 1 "RCM_FACTORY_MODE_ENABLED" ;
VAL_ 1297 RCM_a090_eventFactoryMode 0 "RCM_FACTORY_MODE_DISABLED" 1 "RCM_FACTORY_MODE_ENABLED" ;
VAL_ 1297 RCM_a018_eventFactoryMode 0 "RCM_FACTORY_MODE_DISABLED" 1 "RCM_FACTORY_MODE_ENABLED" ;
VAL_ 1297 RCM_a100_eventFactoryMode 0 "RCM_FACTORY_MODE_DISABLED" 1 "RCM_FACTORY_MODE_ENABLED" ;
VAL_ 1297 RCM_a023_eventFactoryMode 0 "RCM_FACTORY_MODE_DISABLED" 1 "RCM_FACTORY_MODE_ENABLED" ;
VAL_ 1297 RCM_a067_eventFactoryMode 0 "RCM_FACTORY_MODE_DISABLED" 1 "RCM_FACTORY_MODE_ENABLED" ;
VAL_ 1297 RCM_a001_eventFactoryMode 0 "RCM_FACTORY_MODE_DISABLED" 1 "RCM_FACTORY_MODE_ENABLED" ;
VAL_ 1297 RCM_a020_eventFactoryMode 0 "RCM_FACTORY_MODE_DISABLED" 1 "RCM_FACTORY_MODE_ENABLED" ;
VAL_ 1297 RCM_a103_eventFactoryMode 0 "RCM_FACTORY_MODE_DISABLED" 1 "RCM_FACTORY_MODE_ENABLED" ;
VAL_ 1297 RCM_a039_eventFactoryMode 0 "RCM_FACTORY_MODE_DISABLED" 1 "RCM_FACTORY_MODE_ENABLED" ;
VAL_ 1297 RCM_a064_eventFactoryMode 0 "RCM_FACTORY_MODE_DISABLED" 1 "RCM_FACTORY_MODE_ENABLED" ;
VAL_ 1297 RCM_a002_eventFactoryMode 0 "RCM_FACTORY_MODE_DISABLED" 1 "RCM_FACTORY_MODE_ENABLED" ;
VAL_ 1297 RCM_a046_eventFactoryMode 0 "RCM_FACTORY_MODE_DISABLED" 1 "RCM_FACTORY_MODE_ENABLED" ;
VAL_ 1297 RCM_a093_eventFactoryMode 0 "RCM_FACTORY_MODE_DISABLED" 1 "RCM_FACTORY_MODE_ENABLED" ;
VAL_ 1297 RCM_a087_eventFactoryMode 0 "RCM_FACTORY_MODE_DISABLED" 1 "RCM_FACTORY_MODE_ENABLED" ;
VAL_ 1297 RCM_a016_eventFactoryMode 0 "RCM_FACTORY_MODE_DISABLED" 1 "RCM_FACTORY_MODE_ENABLED" ;
VAL_ 1297 RCM_a117_eventFactoryMode 0 "RCM_FACTORY_MODE_DISABLED" 1 "RCM_FACTORY_MODE_ENABLED" ;
VAL_ 1297 RCM_a052_eventFactoryMode 0 "RCM_FACTORY_MODE_DISABLED" 1 "RCM_FACTORY_MODE_ENABLED" ;
VAL_ 1297 RCM_a034_eventFactoryMode 0 "RCM_FACTORY_MODE_DISABLED" 1 "RCM_FACTORY_MODE_ENABLED" ;
VAL_ 1297 RCM_a069_eventFactoryMode 0 "RCM_FACTORY_MODE_DISABLED" 1 "RCM_FACTORY_MODE_ENABLED" ;
VAL_ 1297 RCM_a070_eventFactoryMode 0 "RCM_FACTORY_MODE_DISABLED" 1 "RCM_FACTORY_MODE_ENABLED" ;
VAL_ 1297 RCM_a055_eventFactoryMode 0 "RCM_FACTORY_MODE_DISABLED" 1 "RCM_FACTORY_MODE_ENABLED" ;
VAL_ 1297 RCM_a110_eventFactoryMode 0 "RCM_FACTORY_MODE_DISABLED" 1 "RCM_FACTORY_MODE_ENABLED" ;
VAL_ 1297 RCM_a109_eventFactoryMode 0 "RCM_FACTORY_MODE_DISABLED" 1 "RCM_FACTORY_MODE_ENABLED" ;
VAL_ 1297 RCM_a033_eventFactoryMode 0 "RCM_FACTORY_MODE_DISABLED" 1 "RCM_FACTORY_MODE_ENABLED" ;
VAL_ 1297 RCM_a077_eventFactoryMode 0 "RCM_FACTORY_MODE_DISABLED" 1 "RCM_FACTORY_MODE_ENABLED" ;
VAL_ 1297 RCM_a008_eventFactoryMode 0 "RCM_FACTORY_MODE_DISABLED" 1 "RCM_FACTORY_MODE_ENABLED" ;
VAL_ 1297 RCM_a080_eventFactoryMode 0 "RCM_FACTORY_MODE_DISABLED" 1 "RCM_FACTORY_MODE_ENABLED" ;
VAL_ 1297 RCM_a099_eventFactoryMode 0 "RCM_FACTORY_MODE_DISABLED" 1 "RCM_FACTORY_MODE_ENABLED" ;
VAL_ 1297 RCM_a011_eventFactoryMode 0 "RCM_FACTORY_MODE_DISABLED" 1 "RCM_FACTORY_MODE_ENABLED" ;
VAL_ 1297 RCM_a005_eventFactoryMode 0 "RCM_FACTORY_MODE_DISABLED" 1 "RCM_FACTORY_MODE_ENABLED" ;
VAL_ 1297 RCM_a041_eventFactoryMode 0 "RCM_FACTORY_MODE_DISABLED" 1 "RCM_FACTORY_MODE_ENABLED" ;
VAL_ 1297 RCM_a058_eventFactoryMode 0 "RCM_FACTORY_MODE_DISABLED" 1 "RCM_FACTORY_MODE_ENABLED" ;
VAL_ 1297 RCM_a027_eventFactoryMode 0 "RCM_FACTORY_MODE_DISABLED" 1 "RCM_FACTORY_MODE_ENABLED" ;
VAL_ 1297 RCM_a104_eventFactoryMode 0 "RCM_FACTORY_MODE_DISABLED" 1 "RCM_FACTORY_MODE_ENABLED" ;
VAL_ 1297 RCM_a094_eventFactoryMode 0 "RCM_FACTORY_MODE_DISABLED" 1 "RCM_FACTORY_MODE_ENABLED" ;
VAL_ 1297 RCM_a063_eventFactoryMode 0 "RCM_FACTORY_MODE_DISABLED" 1 "RCM_FACTORY_MODE_ENABLED" ;
VAL_ 1297 RCM_a060_eventFactoryMode 0 "RCM_FACTORY_MODE_DISABLED" 1 "RCM_FACTORY_MODE_ENABLED" ;
VAL_ 1297 RCM_a079_eventFactoryMode 0 "RCM_FACTORY_MODE_DISABLED" 1 "RCM_FACTORY_MODE_ENABLED" ;
VAL_ 1297 RCM_a006_eventFactoryMode 0 "RCM_FACTORY_MODE_DISABLED" 1 "RCM_FACTORY_MODE_ENABLED" ;
VAL_ 1297 RCM_a042_eventFactoryMode 0 "RCM_FACTORY_MODE_DISABLED" 1 "RCM_FACTORY_MODE_ENABLED" ;
VAL_ 1297 RCM_a097_eventFactoryMode 0 "RCM_FACTORY_MODE_DISABLED" 1 "RCM_FACTORY_MODE_ENABLED" ;
VAL_ 1297 RCM_a024_eventFactoryMode 0 "RCM_FACTORY_MODE_DISABLED" 1 "RCM_FACTORY_MODE_ENABLED" ;
VAL_ 1297 RCM_a107_eventFactoryMode 0 "RCM_FACTORY_MODE_DISABLED" 1 "RCM_FACTORY_MODE_ENABLED" ;
VAL_ 1297 RCM_a047_eventFactoryMode 0 "RCM_FACTORY_MODE_DISABLED" 1 "RCM_FACTORY_MODE_ENABLED" ;
VAL_ 1297 RCM_a092_eventFactoryMode 0 "RCM_FACTORY_MODE_DISABLED" 1 "RCM_FACTORY_MODE_ENABLED" ;
VAL_ 1297 RCM_a065_eventFactoryMode 0 "RCM_FACTORY_MODE_DISABLED" 1 "RCM_FACTORY_MODE_ENABLED" ;
VAL_ 1297 RCM_a003_eventFactoryMode 0 "RCM_FACTORY_MODE_DISABLED" 1 "RCM_FACTORY_MODE_ENABLED" ;
VAL_ 1297 RCM_a021_eventFactoryMode 0 "RCM_FACTORY_MODE_DISABLED" 1 "RCM_FACTORY_MODE_ENABLED" ;
VAL_ 1297 RCM_a102_eventFactoryMode 0 "RCM_FACTORY_MODE_DISABLED" 1 "RCM_FACTORY_MODE_ENABLED" ;
VAL_ 1297 RCM_a038_eventFactoryMode 0 "RCM_FACTORY_MODE_DISABLED" 1 "RCM_FACTORY_MODE_ENABLED" ;
VAL_ 1297 RCM_a037_eventFactoryMode 0 "RCM_FACTORY_MODE_DISABLED" 1 "RCM_FACTORY_MODE_ENABLED" ;
VAL_ 1297 RCM_a073_eventFactoryMode 0 "RCM_FACTORY_MODE_DISABLED" 1 "RCM_FACTORY_MODE_ENABLED" ;
VAL_ 1297 RCM_a048_eventFactoryMode 0 "RCM_FACTORY_MODE_DISABLED" 1 "RCM_FACTORY_MODE_ENABLED" ;
VAL_ 1297 RCM_a084_eventFactoryMode 0 "RCM_FACTORY_MODE_DISABLED" 1 "RCM_FACTORY_MODE_ENABLED" ;
VAL_ 1297 RCM_a015_eventFactoryMode 0 "RCM_FACTORY_MODE_DISABLED" 1 "RCM_FACTORY_MODE_ENABLED" ;
VAL_ 1297 RCM_a051_eventFactoryMode 0 "RCM_FACTORY_MODE_DISABLED" 1 "RCM_FACTORY_MODE_ENABLED" ;
VAL_ 1297 RCM_a114_eventFactoryMode 0 "RCM_FACTORY_MODE_DISABLED" 1 "RCM_FACTORY_MODE_ENABLED" ;
VAL_ 1297 RCM_a010_eventFactoryMode 0 "RCM_FACTORY_MODE_DISABLED" 1 "RCM_FACTORY_MODE_ENABLED" ;
VAL_ 1297 RCM_a108_eventFactoryMode 0 "RCM_FACTORY_MODE_DISABLED" 1 "RCM_FACTORY_MODE_ENABLED" ;
VAL_ 1297 RCM_a098_eventFactoryMode 0 "RCM_FACTORY_MODE_DISABLED" 1 "RCM_FACTORY_MODE_ENABLED" ;
VAL_ 1297 RCM_a009_eventFactoryMode 0 "RCM_FACTORY_MODE_DISABLED" 1 "RCM_FACTORY_MODE_ENABLED" ;
VAL_ 1297 RCM_a076_eventFactoryMode 0 "RCM_FACTORY_MODE_DISABLED" 1 "RCM_FACTORY_MODE_ENABLED" ;
VAL_ 1297 RCM_a054_eventFactoryMode 0 "RCM_FACTORY_MODE_DISABLED" 1 "RCM_FACTORY_MODE_ENABLED" ;
VAL_ 1297 RCM_a111_eventFactoryMode 0 "RCM_FACTORY_MODE_DISABLED" 1 "RCM_FACTORY_MODE_ENABLED" ;
VAL_ 1297 RCM_a081_eventFactoryMode 0 "RCM_FACTORY_MODE_DISABLED" 1 "RCM_FACTORY_MODE_ENABLED" ;
VAL_ 1297 RCM_a032_eventFactoryMode 0 "RCM_FACTORY_MODE_DISABLED" 1 "RCM_FACTORY_MODE_ENABLED" ;
VAL_ 1297 RCM_a057_eventFactoryMode 0 "RCM_FACTORY_MODE_DISABLED" 1 "RCM_FACTORY_MODE_ENABLED" ;
VAL_ 1297 RCM_a112_eventFactoryMode 0 "RCM_FACTORY_MODE_DISABLED" 1 "RCM_FACTORY_MODE_ENABLED" ;
VAL_ 1297 RCM_a082_eventFactoryMode 0 "RCM_FACTORY_MODE_DISABLED" 1 "RCM_FACTORY_MODE_ENABLED" ;
VAL_ 1297 RCM_a028_eventFactoryMode 0 "RCM_FACTORY_MODE_DISABLED" 1 "RCM_FACTORY_MODE_ENABLED" ;
VAL_ 1297 RCM_a031_eventFactoryMode 0 "RCM_FACTORY_MODE_DISABLED" 1 "RCM_FACTORY_MODE_ENABLED" ;
VAL_ 1297 RCM_a075_eventFactoryMode 0 "RCM_FACTORY_MODE_DISABLED" 1 "RCM_FACTORY_MODE_ENABLED" ;
VAL_ 1297 RCM_a013_eventFactoryMode 0 "RCM_FACTORY_MODE_DISABLED" 1 "RCM_FACTORY_MODE_ENABLED" ;
VAL_ 1297 RCM_a082_eventArmStatus 1 "RCM_ARMED" 0 "RCM_UNARMED" ;
VAL_ 1297 RCM_a013_eventArmStatus 1 "RCM_ARMED" 0 "RCM_UNARMED" ;
VAL_ 1297 RCM_a057_eventArmStatus 1 "RCM_ARMED" 0 "RCM_UNARMED" ;
VAL_ 1297 RCM_a112_eventArmStatus 1 "RCM_ARMED" 0 "RCM_UNARMED" ;
VAL_ 1297 RCM_a031_eventArmStatus 1 "RCM_ARMED" 0 "RCM_UNARMED" ;
VAL_ 1297 RCM_a028_eventArmStatus 1 "RCM_ARMED" 0 "RCM_UNARMED" ;
VAL_ 1297 RCM_a075_eventArmStatus 1 "RCM_ARMED" 0 "RCM_UNARMED" ;
VAL_ 1297 RCM_a036_eventArmStatus 1 "RCM_ARMED" 0 "RCM_UNARMED" ;
VAL_ 1297 RCM_a014_eventArmStatus 1 "RCM_ARMED" 0 "RCM_UNARMED" ;
VAL_ 1297 RCM_a072_eventArmStatus 1 "RCM_ARMED" 0 "RCM_UNARMED" ;
VAL_ 1297 RCM_a115_eventArmStatus 1 "RCM_ARMED" 0 "RCM_UNARMED" ;
VAL_ 1297 RCM_a050_eventArmStatus 1 "RCM_ARMED" 0 "RCM_UNARMED" ;
VAL_ 1297 RCM_a049_eventArmStatus 1 "RCM_ARMED" 0 "RCM_UNARMED" ;
VAL_ 1297 RCM_a085_eventArmStatus 1 "RCM_ARMED" 0 "RCM_UNARMED" ;
VAL_ 1297 RCM_a000_eventArmStatus 1 "RCM_ARMED" 0 "RCM_UNARMED" ;
VAL_ 1297 RCM_a118_eventArmStatus 1 "RCM_ARMED" 0 "RCM_UNARMED" ;
VAL_ 1297 RCM_a044_eventArmStatus 1 "RCM_ARMED" 0 "RCM_UNARMED" ;
VAL_ 1297 RCM_a088_eventArmStatus 1 "RCM_ARMED" 0 "RCM_UNARMED" ;
VAL_ 1297 RCM_a066_eventArmStatus 1 "RCM_ARMED" 0 "RCM_UNARMED" ;
VAL_ 1297 RCM_a091_eventArmStatus 1 "RCM_ARMED" 0 "RCM_UNARMED" ;
VAL_ 1297 RCM_a019_eventArmStatus 1 "RCM_ARMED" 0 "RCM_UNARMED" ;
VAL_ 1297 RCM_a022_eventArmStatus 1 "RCM_ARMED" 0 "RCM_UNARMED" ;
VAL_ 1297 RCM_a101_eventArmStatus 1 "RCM_ARMED" 0 "RCM_UNARMED" ;
VAL_ 1297 RCM_a047_eventArmStatus 1 "RCM_ARMED" 0 "RCM_UNARMED" ;
VAL_ 1297 RCM_a021_eventArmStatus 1 "RCM_ARMED" 0 "RCM_UNARMED" ;
VAL_ 1297 RCM_a102_eventArmStatus 1 "RCM_ARMED" 0 "RCM_UNARMED" ;
VAL_ 1297 RCM_a065_eventArmStatus 1 "RCM_ARMED" 0 "RCM_UNARMED" ;
VAL_ 1297 RCM_a092_eventArmStatus 1 "RCM_ARMED" 0 "RCM_UNARMED" ;
VAL_ 1297 RCM_a003_eventArmStatus 1 "RCM_ARMED" 0 "RCM_UNARMED" ;
VAL_ 1297 RCM_a038_eventArmStatus 1 "RCM_ARMED" 0 "RCM_UNARMED" ;
VAL_ 1297 RCM_a097_eventArmStatus 1 "RCM_ARMED" 0 "RCM_UNARMED" ;
VAL_ 1297 RCM_a060_eventArmStatus 1 "RCM_ARMED" 0 "RCM_UNARMED" ;
VAL_ 1297 RCM_a024_eventArmStatus 1 "RCM_ARMED" 0 "RCM_UNARMED" ;
VAL_ 1297 RCM_a107_eventArmStatus 1 "RCM_ARMED" 0 "RCM_UNARMED" ;
VAL_ 1297 RCM_a006_eventArmStatus 1 "RCM_ARMED" 0 "RCM_UNARMED" ;
VAL_ 1297 RCM_a079_eventArmStatus 1 "RCM_ARMED" 0 "RCM_UNARMED" ;
VAL_ 1297 RCM_a042_eventArmStatus 1 "RCM_ARMED" 0 "RCM_UNARMED" ;
VAL_ 1297 RCM_a076_eventArmStatus 1 "RCM_ARMED" 0 "RCM_UNARMED" ;
VAL_ 1297 RCM_a009_eventArmStatus 1 "RCM_ARMED" 0 "RCM_UNARMED" ;
VAL_ 1297 RCM_a081_eventArmStatus 1 "RCM_ARMED" 0 "RCM_UNARMED" ;
VAL_ 1297 RCM_a098_eventArmStatus 1 "RCM_ARMED" 0 "RCM_UNARMED" ;
VAL_ 1297 RCM_a010_eventArmStatus 1 "RCM_ARMED" 0 "RCM_UNARMED" ;
VAL_ 1297 RCM_a054_eventArmStatus 1 "RCM_ARMED" 0 "RCM_UNARMED" ;
VAL_ 1297 RCM_a111_eventArmStatus 1 "RCM_ARMED" 0 "RCM_UNARMED" ;
VAL_ 1297 RCM_a108_eventArmStatus 1 "RCM_ARMED" 0 "RCM_UNARMED" ;
VAL_ 1297 RCM_a032_eventArmStatus 1 "RCM_ARMED" 0 "RCM_UNARMED" ;
VAL_ 1297 RCM_a084_eventArmStatus 1 "RCM_ARMED" 0 "RCM_UNARMED" ;
VAL_ 1297 RCM_a015_eventArmStatus 1 "RCM_ARMED" 0 "RCM_UNARMED" ;
VAL_ 1297 RCM_a051_eventArmStatus 1 "RCM_ARMED" 0 "RCM_UNARMED" ;
VAL_ 1297 RCM_a114_eventArmStatus 1 "RCM_ARMED" 0 "RCM_UNARMED" ;
VAL_ 1297 RCM_a037_eventArmStatus 1 "RCM_ARMED" 0 "RCM_UNARMED" ;
VAL_ 1297 RCM_a073_eventArmStatus 1 "RCM_ARMED" 0 "RCM_UNARMED" ;
VAL_ 1297 RCM_a048_eventArmStatus 1 "RCM_ARMED" 0 "RCM_UNARMED" ;
VAL_ 1297 RCM_a016_eventArmStatus 1 "RCM_ARMED" 0 "RCM_UNARMED" ;
VAL_ 1297 RCM_a087_eventArmStatus 1 "RCM_ARMED" 0 "RCM_UNARMED" ;
VAL_ 1297 RCM_a034_eventArmStatus 1 "RCM_ARMED" 0 "RCM_UNARMED" ;
VAL_ 1297 RCM_a052_eventArmStatus 1 "RCM_ARMED" 0 "RCM_UNARMED" ;
VAL_ 1297 RCM_a117_eventArmStatus 1 "RCM_ARMED" 0 "RCM_UNARMED" ;
VAL_ 1297 RCM_a070_eventArmStatus 1 "RCM_ARMED" 0 "RCM_UNARMED" ;
VAL_ 1297 RCM_a069_eventArmStatus 1 "RCM_ARMED" 0 "RCM_UNARMED" ;
VAL_ 1297 RCM_a093_eventArmStatus 1 "RCM_ARMED" 0 "RCM_UNARMED" ;
VAL_ 1297 RCM_a064_eventArmStatus 1 "RCM_ARMED" 0 "RCM_UNARMED" ;
VAL_ 1297 RCM_a039_eventArmStatus 1 "RCM_ARMED" 0 "RCM_UNARMED" ;
VAL_ 1297 RCM_a103_eventArmStatus 1 "RCM_ARMED" 0 "RCM_UNARMED" ;
VAL_ 1297 RCM_a020_eventArmStatus 1 "RCM_ARMED" 0 "RCM_UNARMED" ;
VAL_ 1297 RCM_a002_eventArmStatus 1 "RCM_ARMED" 0 "RCM_UNARMED" ;
VAL_ 1297 RCM_a046_eventArmStatus 1 "RCM_ARMED" 0 "RCM_UNARMED" ;
VAL_ 1297 RCM_a058_eventArmStatus 1 "RCM_ARMED" 0 "RCM_UNARMED" ;
VAL_ 1297 RCM_a005_eventArmStatus 1 "RCM_ARMED" 0 "RCM_UNARMED" ;
VAL_ 1297 RCM_a063_eventArmStatus 1 "RCM_ARMED" 0 "RCM_UNARMED" ;
VAL_ 1297 RCM_a041_eventArmStatus 1 "RCM_ARMED" 0 "RCM_UNARMED" ;
VAL_ 1297 RCM_a094_eventArmStatus 1 "RCM_ARMED" 0 "RCM_UNARMED" ;
VAL_ 1297 RCM_a027_eventArmStatus 1 "RCM_ARMED" 0 "RCM_UNARMED" ;
VAL_ 1297 RCM_a104_eventArmStatus 1 "RCM_ARMED" 0 "RCM_UNARMED" ;
VAL_ 1297 RCM_a080_eventArmStatus 1 "RCM_ARMED" 0 "RCM_UNARMED" ;
VAL_ 1297 RCM_a099_eventArmStatus 1 "RCM_ARMED" 0 "RCM_UNARMED" ;
VAL_ 1297 RCM_a011_eventArmStatus 1 "RCM_ARMED" 0 "RCM_UNARMED" ;
VAL_ 1297 RCM_a055_eventArmStatus 1 "RCM_ARMED" 0 "RCM_UNARMED" ;
VAL_ 1297 RCM_a110_eventArmStatus 1 "RCM_ARMED" 0 "RCM_UNARMED" ;
VAL_ 1297 RCM_a109_eventArmStatus 1 "RCM_ARMED" 0 "RCM_UNARMED" ;
VAL_ 1297 RCM_a033_eventArmStatus 1 "RCM_ARMED" 0 "RCM_UNARMED" ;
VAL_ 1297 RCM_a077_eventArmStatus 1 "RCM_ARMED" 0 "RCM_UNARMED" ;
VAL_ 1297 RCM_a008_eventArmStatus 1 "RCM_ARMED" 0 "RCM_UNARMED" ;
VAL_ 1297 RCM_a083_eventArmStatus 1 "RCM_ARMED" 0 "RCM_UNARMED" ;
VAL_ 1297 RCM_a113_eventArmStatus 1 "RCM_ARMED" 0 "RCM_UNARMED" ;
VAL_ 1297 RCM_a056_eventArmStatus 1 "RCM_ARMED" 0 "RCM_UNARMED" ;
VAL_ 1297 RCM_a030_eventArmStatus 1 "RCM_ARMED" 0 "RCM_UNARMED" ;
VAL_ 1297 RCM_a012_eventArmStatus 1 "RCM_ARMED" 0 "RCM_UNARMED" ;
VAL_ 1297 RCM_a029_eventArmStatus 1 "RCM_ARMED" 0 "RCM_UNARMED" ;
VAL_ 1297 RCM_a074_eventArmStatus 1 "RCM_ARMED" 0 "RCM_UNARMED" ;
VAL_ 1297 RCM_a017_eventArmStatus 1 "RCM_ARMED" 0 "RCM_UNARMED" ;
VAL_ 1297 RCM_a053_eventArmStatus 1 "RCM_ARMED" 0 "RCM_UNARMED" ;
VAL_ 1297 RCM_a116_eventArmStatus 1 "RCM_ARMED" 0 "RCM_UNARMED" ;
VAL_ 1297 RCM_a035_eventArmStatus 1 "RCM_ARMED" 0 "RCM_UNARMED" ;
VAL_ 1297 RCM_a071_eventArmStatus 1 "RCM_ARMED" 0 "RCM_UNARMED" ;
VAL_ 1297 RCM_a068_eventArmStatus 1 "RCM_ARMED" 0 "RCM_UNARMED" ;
VAL_ 1297 RCM_a086_eventArmStatus 1 "RCM_ARMED" 0 "RCM_UNARMED" ;
VAL_ 1297 RCM_a045_eventArmStatus 1 "RCM_ARMED" 0 "RCM_UNARMED" ;
VAL_ 1297 RCM_a089_eventArmStatus 1 "RCM_ARMED" 0 "RCM_UNARMED" ;
VAL_ 1297 RCM_a090_eventArmStatus 1 "RCM_ARMED" 0 "RCM_UNARMED" ;
VAL_ 1297 RCM_a067_eventArmStatus 1 "RCM_ARMED" 0 "RCM_UNARMED" ;
VAL_ 1297 RCM_a018_eventArmStatus 1 "RCM_ARMED" 0 "RCM_UNARMED" ;
VAL_ 1297 RCM_a100_eventArmStatus 1 "RCM_ARMED" 0 "RCM_UNARMED" ;
VAL_ 1297 RCM_a023_eventArmStatus 1 "RCM_ARMED" 0 "RCM_UNARMED" ;
VAL_ 1297 RCM_a001_eventArmStatus 1 "RCM_ARMED" 0 "RCM_UNARMED" ;
VAL_ 1297 RCM_a040_eventArmStatus 1 "RCM_ARMED" 0 "RCM_UNARMED" ;
VAL_ 1297 RCM_a062_eventArmStatus 1 "RCM_ARMED" 0 "RCM_UNARMED" ;
VAL_ 1297 RCM_a095_eventArmStatus 1 "RCM_ARMED" 0 "RCM_UNARMED" ;
VAL_ 1297 RCM_a026_eventArmStatus 1 "RCM_ARMED" 0 "RCM_UNARMED" ;
VAL_ 1297 RCM_a105_eventArmStatus 1 "RCM_ARMED" 0 "RCM_UNARMED" ;
VAL_ 1297 RCM_a004_eventArmStatus 1 "RCM_ARMED" 0 "RCM_UNARMED" ;
VAL_ 1297 RCM_a059_eventArmStatus 1 "RCM_ARMED" 0 "RCM_UNARMED" ;
VAL_ 1297 RCM_a043_eventArmStatus 1 "RCM_ARMED" 0 "RCM_UNARMED" ;
VAL_ 1297 RCM_a096_eventArmStatus 1 "RCM_ARMED" 0 "RCM_UNARMED" ;
VAL_ 1297 RCM_a078_eventArmStatus 1 "RCM_ARMED" 0 "RCM_UNARMED" ;
VAL_ 1297 RCM_a007_eventArmStatus 1 "RCM_ARMED" 0 "RCM_UNARMED" ;
VAL_ 1297 RCM_a025_eventArmStatus 1 "RCM_ARMED" 0 "RCM_UNARMED" ;
VAL_ 1297 RCM_a106_eventArmStatus 1 "RCM_ARMED" 0 "RCM_UNARMED" ;
VAL_ 1297 RCM_a061_eventArmStatus 1 "RCM_ARMED" 0 "RCM_UNARMED" ;
VAL_ 1297 RCM_alertState 0 "ALERT_CLEARED" 1 "ALERT_SET" ;
VAL_ 1297 RCM_alertID 60 "RCM_a060_stpsLeft" 42 "RCM_a042_ens1Line" 41 "RCM_a041_hoodActuatorLeft" 37 "RCM_a037_curAB2ndRowRight" 4 "RCM_a004_internalFault" 79 "RCM_a079_comOCS1DStatus" 44 "RCM_a044_upFrontSensorLeft" 26 "RCM_a026_kneeABFrontPassenger" 93 "RCM_a093_comVCLEFTStatus" 13 "RCM_a013_driverOrientation" 55 "RCM_a055_inertialMeasurement" 107 "RCM_a107_imuVertAccOffstCompLim" 85 "RCM_a085_comGTWCarConfig" 118 "RCM_a118_imuInPlaneAcceleration" 104 "RCM_a104_imuRollR8OffstCompLim" 1 "RCM_a001_nearDeploy" 95 "RCM_a095_comESPstatus" 96 "RCM_a096_comESPwheelSpeeds" 103 "RCM_a103_imuPtchR8OffstCompLim" 9 "RCM_a009_reprogramLimit" 32 "RCM_a032_curtainABLeft" 110 "RCM_a110_factoryMode" 76 "RCM_a076_comEPBLStatus" 49 "RCM_a049_sideAccelCPillarRight" 15 "RCM_a015_driverABStage2" 20 "RCM_a020_pretenShldFrontRight" 51 "RCM_a051_pressureFrontLftDoor" 91 "RCM_a091_comEPAS3PsysStatus" 3 "RCM_a003_warningIndicator" 47 "RCM_a047_sideAccelBPillarRight" 74 "RCM_a074_comCHCANPH5" 90 "RCM_a090_comPartyBusOff" 0 "RCM_a000_crashDetected" 14 "RCM_a014_driverABStage1" 66 "RCM_a066_seatBackSw2ndRowLeft" 48 "RCM_a048_sideAccelCPillarLeft" 97 "RCM_a097_comDIspeed" 30 "RCM_a030_farSideInboardAirbag" 6 "RCM_a006_batteryVoltageRange" 67 "RCM_a067_comCANInitFailure" 31 "RCM_a031_frontCenterAirbag" 117 "RCM_a117_imuVerticalAcceleration" 73 "RCM_a073_comCHCANPH4" 69 "RCM_a069_comCHCANPH7" 59 "RCM_a059_buckle1stRowRight" 7 "RCM_a007_powerSupplyExternal" 18 "RCM_a018_passengerActiveVent" 113 "RCM_a113_imuPitchRate" 45 "RCM_a045_upFrontSensorRight" 84 "RCM_a084_comTPMSStatus" 115 "RCM_a115_imuLinearAcceleration" 87 "RCM_a087_comCANSilent" 52 "RCM_a052_pressureFrontRtDoor" 81 "RCM_a081_comVCFRONTLVPwr" 86 "RCM_a086_comVINMIA" 36 "RCM_a036_curAB2ndRowLeft" 12 "RCM_a012_vinStorage" 8 "RCM_a008_powerSupplyInternal" 65 "RCM_a065_driverOrientConfigPin" 50 "RCM_a050_upFrontSensorCenter" 53 "RCM_a053_pressurePedProLeft" 100 "RCM_a100_comDIsystemStatus" 35 "RCM_a035_preten2ndRowRight" 78 "RCM_a078_comOCS1PStatus" 88 "RCM_a088_comCHCANPH2" 89 "RCM_a089_comCHCANPH3" 68 "RCM_a068_comChassisBusOff" 39 "RCM_a039_unusedB" 62 "RCM_a062_alrSwitch" 70 "RCM_a070_comCHCANPH8" 83 "RCM_a083_comGTWCarState" 71 "RCM_a071_comCHCANPH9" 24 "RCM_a024_loadLimiterRightSide" 114 "RCM_a114_imuRollRate" 108 "RCM_a108_crashAlgoWakeup" 75 "RCM_a075_comCHCANPH6" 98 "RCM_a098_comDIchassisControl" 46 "RCM_a046_sideAccelBPillarLeft" 11 "RCM_a011_eepromDataLocked" 17 "RCM_a017_passABStage2" 64 "RCM_a064_hardwareCodingPin1" 27 "RCM_a027_sideAB1stRowLeft" 63 "RCM_a063_sbsw2ndRowRight" 105 "RCM_a105_imuLongAccOffstCompLim" 25 "RCM_a025_kneeABDriver" 56 "RCM_a056_passengerFrontOCS" 5 "RCM_a005_crcError" 106 "RCM_a106_imuLatAccOffstCompLim" 77 "RCM_a077_comEPBRStatus" 92 "RCM_a092_comDASISF" 111 "RCM_a111_diagnosticsEnabled" 16 "RCM_a016_passABStage1" 54 "RCM_a054_pressurePedProRight" 72 "RCM_a072_comUnused" 94 "RCM_a094_comVCRIGHTStatus" 23 "RCM_a023_loadLimiterLeftSide" 33 "RCM_a033_curtainABRight" 2 "RCM_a002_airbagsNotArmed" 101 "RCM_a101_idfSystem" 28 "RCM_a028_sideAB1stRowRight" 102 "RCM_a102_imuYawR8OffstCompLim" 34 "RCM_a034_preten2ndRowLeft" 116 "RCM_a116_imuLateralAcceleration" 38 "RCM_a038_unusedA" 112 "RCM_a112_imuYawRate" 109 "RCM_a109_abuseImmunity" 57 "RCM_a057_driverOCS" 82 "RCM_a082_comUIodo" 19 "RCM_a019_pretenShldrFrontLeft" 43 "RCM_a043_ens2Line" 29 "RCM_a029_driverABActiveVent" 40 "RCM_a040_hoodActuatorRight" 61 "RCM_a061_stpsRight" 58 "RCM_a058_buckle1stRowLeft" 21 "RCM_a021_pretenLapFrontLeft" 22 "RCM_a022_pretenLapFrontRight" 10 "RCM_a010_scmDisabled" 80 "RCM_a080_comGTWACS" 99 "RCM_a099_comDItorque" ;
VAL_ 545 VCFRONT_uiAudioLVState 1 "LV_ON" 2 "LV_GOING_DOWN" 3 "LV_FAULT" 0 "LV_OFF" ;
VAL_ 545 VCFRONT_uiHiCurrentLVState 1 "LV_ON" 2 "LV_GOING_DOWN" 3 "LV_FAULT" 0 "LV_OFF" ;
VAL_ 545 VCFRONT_vcrightHiCurrentLVState 1 "LV_ON" 2 "LV_GOING_DOWN" 3 "LV_FAULT" 0 "LV_OFF" ;
VAL_ 545 VCFRONT_vcleftHiCurrentLVState 1 "LV_ON" 2 "LV_GOING_DOWN" 3 "LV_FAULT" 0 "LV_OFF" ;
VAL_ 545 VCFRONT_ocsLVRequest 1 "LV_ON" 2 "LV_GOING_DOWN" 3 "LV_FAULT" 0 "LV_OFF" ;
VAL_ 545 VCFRONT_oilPumpRearLVRequest 1 "LV_ON" 2 "LV_GOING_DOWN" 3 "LV_FAULT" 0 "LV_OFF" ;
VAL_ 545 VCFRONT_oilPumpFrontLVState 1 "LV_ON" 2 "LV_GOING_DOWN" 3 "LV_FAULT" 0 "LV_OFF" ;
VAL_ 545 VCFRONT_disLVState 1 "LV_ON" 2 "LV_GOING_DOWN" 3 "LV_FAULT" 0 "LV_OFF" ;
VAL_ 545 VCFRONT_diLVRequest 1 "LV_ON" 2 "LV_GOING_DOWN" 3 "LV_FAULT" 0 "LV_OFF" ;
VAL_ 545 VCFRONT_das2HighCurrentLVState 1 "LV_ON" 2 "LV_GOING_DOWN" 3 "LV_FAULT" 0 "LV_OFF" ;
VAL_ 545 VCFRONT_das1HighCurrentLVState 1 "LV_ON" 2 "LV_GOING_DOWN" 3 "LV_FAULT" 0 "LV_OFF" ;
VAL_ 545 VCFRONT_amplifierLVRequest 1 "LV_ON" 2 "LV_GOING_DOWN" 3 "LV_FAULT" 0 "LV_OFF" ;
VAL_ 545 VCFRONT_tunerLVRequest 1 "LV_ON" 2 "LV_GOING_DOWN" 3 "LV_FAULT" 0 "LV_OFF" ;
VAL_ 545 VCFRONT_iBoosterLVState 1 "LV_ON" 2 "LV_GOING_DOWN" 3 "LV_FAULT" 0 "LV_OFF" ;
VAL_ 545 VCFRONT_rcmLVRequest 1 "LV_ON" 2 "LV_GOING_DOWN" 3 "LV_FAULT" 0 "LV_OFF" ;
VAL_ 545 VCFRONT_tpmsLVRequest 1 "LV_ON" 2 "LV_GOING_DOWN" 3 "LV_FAULT" 0 "LV_OFF" ;
VAL_ 545 VCFRONT_sccmLVRequest 1 "LV_ON" 2 "LV_GOING_DOWN" 3 "LV_FAULT" 0 "LV_OFF" ;
VAL_ 545 VCFRONT_pcsLVState 1 "LV_ON" 2 "LV_GOING_DOWN" 3 "LV_FAULT" 0 "LV_OFF" ;
VAL_ 545 VCFRONT_ptcLVRequest 1 "LV_ON" 2 "LV_GOING_DOWN" 3 "LV_FAULT" 0 "LV_OFF" ;
VAL_ 545 VCFRONT_hvacCompLVState 1 "LV_ON" 2 "LV_GOING_DOWN" 3 "LV_FAULT" 0 "LV_OFF" ;
VAL_ 545 VCFRONT_tasLVState 1 "LV_ON" 2 "LV_GOING_DOWN" 3 "LV_FAULT" 0 "LV_OFF" ;
VAL_ 545 VCFRONT_hvcLVRequest 1 "LV_ON" 2 "LV_GOING_DOWN" 3 "LV_FAULT" 0 "LV_OFF" ;
VAL_ 545 VCFRONT_radcLVState 1 "LV_ON" 2 "LV_GOING_DOWN" 3 "LV_FAULT" 0 "LV_OFF" ;
VAL_ 545 VCFRONT_epasLVState 1 "LV_ON" 2 "LV_GOING_DOWN" 3 "LV_FAULT" 0 "LV_OFF" ;
VAL_ 545 VCFRONT_espLVState 1 "LV_ON" 2 "LV_GOING_DOWN" 3 "LV_FAULT" 0 "LV_OFF" ;
VAL_ 545 VCFRONT_parkLVState 1 "LV_ON" 2 "LV_GOING_DOWN" 3 "LV_FAULT" 0 "LV_OFF" ;
VAL_ 545 VCFRONT_cpLVRequest 1 "LV_ON" 2 "LV_GOING_DOWN" 3 "LV_FAULT" 0 "LV_OFF" ;
VAL_ 545 VCFRONT_vehiclePowerState 3 "VEHICLE_POWER_STATE_DRIVE" 1 "VEHICLE_POWER_STATE_CONDITIONING" 2 "VEHICLE_POWER_STATE_ACCESSORY" 0 "VEHICLE_POWER_STATE_OFF" ;
VAL_ 545 VCFRONT_LVPowerStateIndex 0 "Mux0" 1 "Mux1" ;
VAL_ 846 PARK_frontRightMiddleRawDistData 255 "SNA" ;
VAL_ 846 PARK_frontMiddleRawDistData 255 "SNA" ;
VAL_ 846 PARK_frontLeftMiddleRawDistData 255 "SNA" ;
